VERSION ""

NS_ :

BS_:

BU_: CGW CLU EPB FCA SCC FR_CMR FR_RDR ADAS_PRK AMP BCW LDW_LKA MDPS RVM HUD AVM ACU ESC AFS

BO_ 870 CGW_PC4: 7 CGW
 SG_ F_N_ENG : 49|1@1+ (1,0) [0|1] ""  CLU,EPB,FCA,SCC,FR_CMR,FR_RDR
 SG_ N : 8|16@1+ (0.25,0) [0|16383.75] "rpm"  ADAS_PRK,AMP,CLU,EPB,FCA,SCC,FR_CMR,FR_RDR

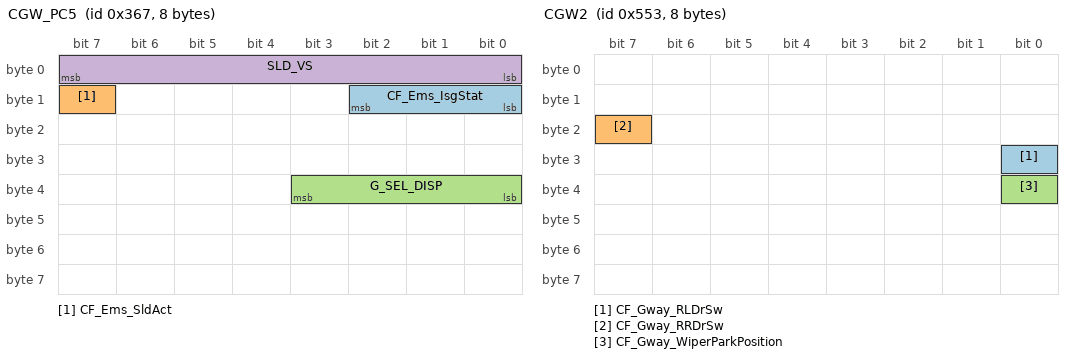
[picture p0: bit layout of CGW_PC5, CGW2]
BO_ 871 CGW_PC5: 8 CGW
 SG_ CF_Ems_IsgStat : 8|3@1+ (1,0) [0|7] ""  BCW,CLU,EPB,LDW_LKA,MDPS,SCC,FR_CMR,FR_RDR
 SG_ CF_Ems_SldAct : 15|1@1+ (1,0) [0|1] ""  CLU,LDW_LKA,SCC,FR_CMR,FR_RDR
 SG_ G_SEL_DISP : 32|4@1+ (1,0) [0|15] ""  ADAS_PRK,BCW,CLU,EPB,FCA,LDW_LKA,RVM,SCC,FR_CMR,FR_RDR
 SG_ SLD_VS : 0|8@1+ (1,0) [0|255] "km/h"  CLU,LDW_LKA,FR_CMR,FR_RDR

BO_ 1345 CGW1: 8 CGW
 SG_ CF_Gway_AstDrSw : 35|1@1+ (1,0) [0|1] ""  ADAS_PRK,CLU,LDW_LKA,FR_CMR,FR_RDR
 SG_ CF_Gway_DrvDrSw : 8|2@1+ (1,0) [0|3] ""  ADAS_PRK,CLU,EPB,LDW_LKA,SCC,FR_CMR,FR_RDR
 SG_ CF_Gway_DrvSeatBeltSw : 10|2@1+ (1,0) [0|3] ""  ADAS_PRK,EPB,LDW_LKA,FR_CMR,FR_RDR
 SG_ CF_Gway_HazardSw : 33|2@1+ (1,0) [0|3] ""  LDW_LKA,FR_CMR,FR_RDR
 SG_ CF_Gway_HBAControlMode : 52|1@1+ (1,0) [0|1] ""  LDW_LKA,FR_CMR,FR_RDR
 SG_ CF_Gway_HeadLampHigh : 32|1@1+ (1,0) [0|1] ""  CLU,LDW_LKA,FR_CMR,FR_RDR
 SG_ CF_Gway_HeadLampLow : 31|1@1+ (1,0) [0|1] ""  CLU,LDW_LKA,FR_CMR,FR_RDR
 SG_ CF_Gway_InhibitRMT : 54|2@1+ (1,0) [0|3] ""  ADAS_PRK,BCW,CLU,EPB,FCA,LDW_LKA,RVM,FR_CMR,FR_RDR
 SG_ CF_Gway_RainSnsState : 28|3@1+ (1,0) [0|7] ""  LDW_LKA,FR_CMR,FR_RDR
 SG_ CF_Gway_TSigLHSw : 42|1@1+ (1,0) [0|1] ""  FCA,LDW_LKA,FR_CMR,FR_RDR
 SG_ CF_Gway_TSigRHSw : 41|1@1+ (1,0) [0|1] ""  FCA,LDW_LKA,FR_CMR,FR_RDR
 SG_ CF_Gway_TurnSigLh : 19|2@1+ (1,0) [0|3] ""  BCW,CLU,LDW_LKA,SCC,FR_CMR,FR_RDR
 SG_ CF_Gway_TurnSigRh : 62|2@1+ (1,0) [0|3] ""  BCW,CLU,LDW_LKA,SCC,FR_CMR,FR_RDR
 SG_ CF_Gway_WiperAutoSw : 27|1@1+ (1,0) [0|1] ""  LDW_LKA,FR_CMR,FR_RDR
 SG_ CF_Gway_WiperHighSw : 26|1@1+ (1,0) [0|1] ""  LDW_LKA,FR_CMR,FR_RDR
 SG_ CF_Gway_WiperIntSw : 24|1@1+ (1,0) [0|1] ""  LDW_LKA,FR_CMR,FR_RDR
 SG_ CF_Gway_WiperIntT : 21|3@1+ (1,0) [0|7] ""  CLU,LDW_LKA,FR_CMR,FR_RDR
 SG_ CF_Gway_WiperLowSw : 25|1@1+ (1,0) [0|1] ""  LDW_LKA,FR_CMR,FR_RDR
 SG_ CF_Gway_IGNSw : 0|3@1+ (1,0) [0|7] ""  ADAS_PRK,CLU,LDW_LKA,RVM,HUD,EPB,AVM,BCW,SCC,FR_CMR,FR_RDR

BO_ 1363 CGW2: 8 CGW
 SG_ CF_Gway_RLDrSw : 24|1@1+ (1,0) [0|1] ""  ADAS_PRK,CLU,LDW_LKA,FR_CMR,FR_RDR
 SG_ CF_Gway_RRDrSw : 23|1@1+ (1,0) [0|1] ""  ADAS_PRK,CLU,LDW_LKA,FR_CMR,FR_RDR
 SG_ CF_Gway_WiperParkPosition : 32|1@1+ (1,0) [0|1] ""  LDW_LKA,FR_CMR,FR_RDR

BO_ 1193 CGW8: 8 CGW
 SG_ C_SMKTeleEngineRunning : 3|1@1+ (1,0) [0|1] ""  LDW_LKA,FR_CMR,FR_RDR

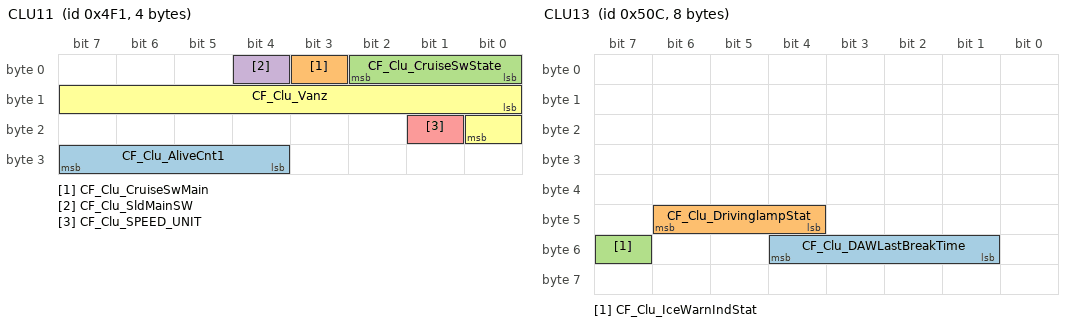
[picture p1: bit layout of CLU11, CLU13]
BO_ 1265 CLU11: 4 CLU
 SG_ CF_Clu_AliveCnt1 : 28|4@1+ (1,0) [0|15] ""  CGW,EPB,FCA,LDW_LKA,MDPS,SCC,FR_CMR,FR_RDR
 SG_ CF_Clu_CruiseSwMain : 3|1@1+ (1,0) [0|1] ""  CGW,SCC,FR_CMR,FR_RDR
 SG_ CF_Clu_CruiseSwState : 0|3@1+ (1,0) [0|7] ""  CGW,LDW_LKA,SCC,FR_CMR,FR_RDR
 SG_ CF_Clu_SldMainSW : 4|1@1+ (1,0) [0|1] ""  CGW,SCC,FR_CMR,FR_RDR
 SG_ CF_Clu_SPEED_UNIT : 17|1@1+ (1,0) [0|1] ""  ACU,ADAS_PRK,BCW,CGW,ESC,FCA,LDW_LKA,MDPS,SCC,FR_CMR,FR_RDR
 SG_ CF_Clu_Vanz : 8|9@1+ (0.5,0) [0|255] "km/h or MPH"  ADAS_PRK,BCW,CGW,FCA,LDW_LKA,MDPS,SCC,FR_CMR,FR_RDR

BO_ 1456 CLU12: 4 CLU
 SG_ CF_Clu_Odometer : 0|24@1+ (0.1,0) [0|1677721.4] "km"  BCW,CGW,EPB,FCA,SCC,FR_CMR,FR_RDR

BO_ 1292 CLU13: 8 CLU
 SG_ CF_Clu_DAWLastBreakTime : 49|4@1+ (1,0) [0|15] ""  CGW,LDW_LKA,FR_CMR,FR_RDR
 SG_ CF_Clu_DrivinglampStat : 44|3@1+ (1,0) [0|7] ""  CGW,ESC,MDPS,SCC,FR_CMR,FR_RDR
 SG_ CF_Clu_IceWarnIndStat : 55|1@1+ (1,0) [0|1] ""  LDW_LKA,FR_CMR,FR_RDR

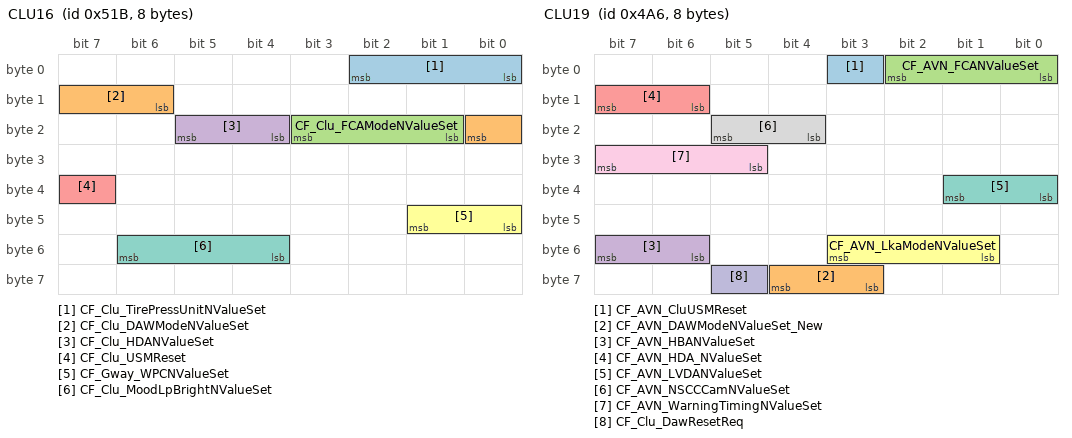
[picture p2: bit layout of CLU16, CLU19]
BO_ 1307 CLU16: 8 CLU
 SG_ CF_Clu_TirePressUnitNValueSet : 0|3@1+ (1,0) [0|7] ""  CGW,FR_CMR,FR_RDR
 SG_ CF_Clu_DAWModeNValueSet : 14|3@1+ (1,0) [0|7] ""  FR_CMR,FR_RDR
 SG_ CF_Clu_FCAModeNValueSet : 17|3@1+ (1,0) [0|7] ""  FR_RDR
 SG_ CF_Clu_HDANValueSet : 20|2@1+ (1,0) [0|3] ""  FR_CMR,FR_RDR
 SG_ CF_Clu_USMReset : 39|1@1+ (1,0) [0|1] ""  SCC,FR_CMR,HUD,CGW,BCW,AFS,FR_RDR
 SG_ CF_Gway_WPCNValueSet : 40|2@1+ (1,0) [0|3] ""  CGW,FR_CMR,FR_RDR
 SG_ CF_Clu_MoodLpBrightNValueSet : 52|3@1+ (1,0) [0|7] ""  CGW,FR_CMR,FR_RDR

BO_ 1190 CLU19: 8 CLU
 SG_ CF_AVN_CluUSMReset : 3|1@1+ (1,0) [0|1] ""  ADAS_PRK,BCW,FCA,LDW_LKA,SCC,FR_CMR,FR_RDR
 SG_ CF_AVN_DAWModeNValueSet_New : 59|2@1+ (1,0) [0|3] ""  LDW_LKA,FR_CMR,FR_RDR
 SG_ CF_AVN_FCANValueSet : 0|3@1+ (1,0) [0|7] ""  FCA,FR_CMR,FR_RDR
 SG_ CF_AVN_HBANValueSet : 54|2@1+ (1,0) [0|3] ""  CGW,LDW_LKA,FR_CMR,FR_RDR
 SG_ CF_AVN_HDA_NValueSet : 14|2@1+ (1,0) [0|3] ""  LDW_LKA,FR_CMR,FR_RDR
 SG_ CF_AVN_LkaModeNValueSet : 49|3@1+ (1,0) [0|7] ""  LDW_LKA,FR_CMR,FR_RDR
 SG_ CF_AVN_LVDANValueSet : 32|2@1+ (1,0) [0|3] ""  LDW_LKA,FR_CMR,FR_RDR
 SG_ CF_AVN_NSCCCamNValueSet : 20|2@1+ (1,0) [0|3] ""  SCC,FR_CMR,FR_RDR
 SG_ CF_AVN_WarningTimingNValueSet : 29|3@1+ (1,0) [0|7] ""  ADAS_PRK,BCW,FCA,LDW_LKA,FR_CMR,FR_RDR
 SG_ CF_Clu_DawResetReq : 61|1@1+ (1,0) [0|1] ""  LDW_LKA,FR_CMR,FR_RDR

BO_ 913 CLU21: 8 CLU
 SG_ CF_Clu_LFASwState : 4|1@1+ (1,0) [0|1] ""  LDW_LKA,FR_CMR,FR_RDR

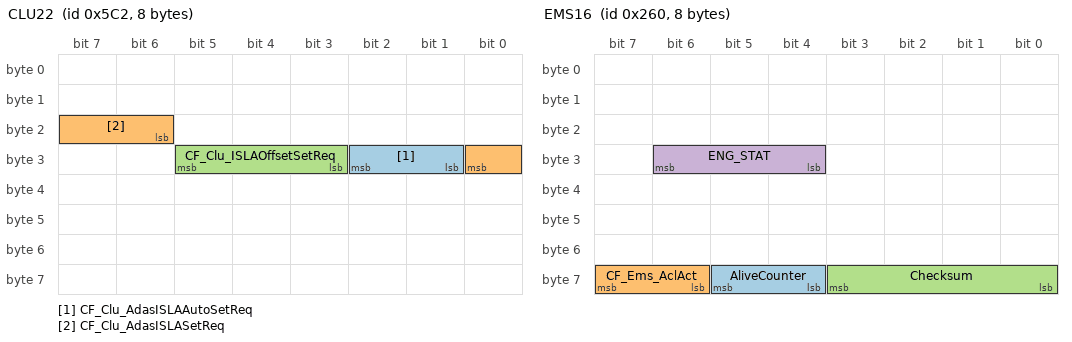
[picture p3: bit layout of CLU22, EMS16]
BO_ 1474 CLU22: 8 CLU
 SG_ CF_Clu_AdasISLAAutoSetReq : 25|2@1+ (1,0) [0|3] ""  LDW_LKA,FR_CMR,FR_RDR
 SG_ CF_Clu_AdasISLASetReq : 22|3@1+ (1,0) [0|7] ""  LDW_LKA,FR_CMR,FR_RDR
 SG_ CF_Clu_ISLAOffsetSetReq : 27|3@1+ (1,0) [0|7] ""  LDW_LKA,FR_CMR,FR_RDR

BO_ 809 EMS12: 8 CGW
 SG_ ACC_ACT : 30|1@1+ (1,0) [0|1] ""  AMP,FCA,FR_CMR,FR_RDR
 SG_ CONF_TCU m1 : 0|6@1+ (1,0) [0|63] ""  AMP,BCW,EPB,FCA,LDW_LKA,FR_CMR,FR_RDR
 SG_ MUL_CODE M : 6|2@1+ (1,0) [0|3] ""  ADAS_PRK,AMP,BCW,EPB,FCA,LDW_LKA,FR_CMR,FR_RDR
 SG_ PV_AV_CAN : 48|8@1+ (0.3906,0) [0|99.603] "%"  ADAS_PRK,AMP,EPB,FCA,LDW_LKA,SCC,FR_CMR,FR_RDR

BO_ 608 EMS16: 8 CGW
 SG_ AliveCounter : 60|2@1+ (1,0) [0|3] ""  FCA,MDPS,SCC,FR_CMR,FR_RDR
 SG_ CF_Ems_AclAct : 62|2@1+ (1,0) [0|3] ""  FCA,FR_CMR,FR_RDR
 SG_ Checksum : 56|4@1+ (1,0) [0|15] ""  FCA,MDPS,SCC,FR_CMR,FR_RDR
 SG_ ENG_STAT : 28|3@1+ (1,0) [0|7] ""  ADAS_PRK,AMP,BCW,CLU,EPB,FCA,LDW_LKA,MDPS,SCC,FR_CMR,FR_RDR

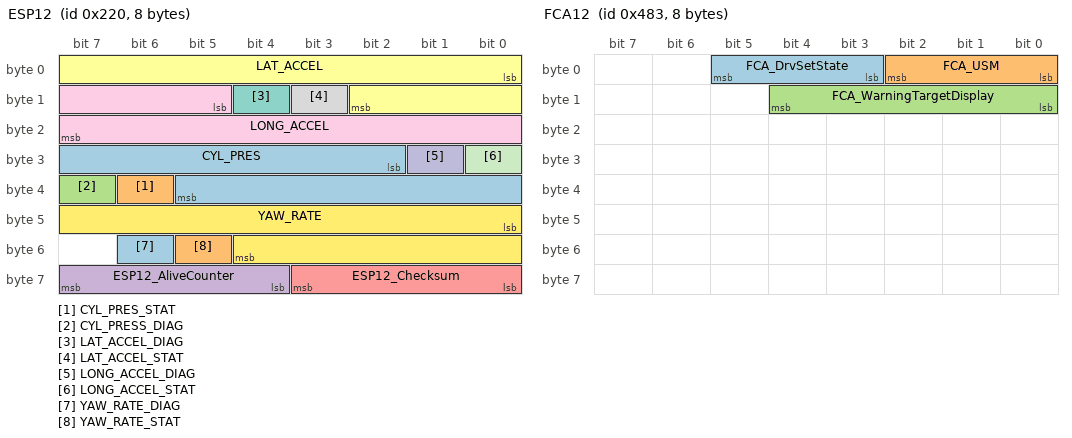
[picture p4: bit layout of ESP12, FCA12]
BO_ 544 ESP12: 8 ESC
 SG_ CYL_PRES : 26|12@1+ (0.1,0) [0|409.5] "Bar"  ADAS_PRK,CGW,EPB,FCA,LDW_LKA,SCC,FR_CMR,FR_RDR
 SG_ CYL_PRES_STAT : 38|1@1+ (1,0) [0|1] ""  ADAS_PRK,CGW,EPB,FCA,LDW_LKA,SCC,FR_CMR,FR_RDR
 SG_ CYL_PRESS_DIAG : 39|1@1+ (1,0) [0|1] ""  CGW,EPB,FCA,LDW_LKA,SCC,FR_CMR,FR_RDR
 SG_ ESP12_AliveCounter : 60|4@1+ (1,0) [0|15] ""  ADAS_PRK,FCA,LDW_LKA,FR_CMR,FR_RDR
 SG_ ESP12_Checksum : 56|4@1+ (1,0) [0|15] ""  ADAS_PRK,FCA,LDW_LKA,FR_CMR,FR_RDR
 SG_ LAT_ACCEL : 0|11@1+ (0.01,-10.23) [-10.23|10.24] "m/s^2"  CGW,FCA,LDW_LKA,MDPS,SCC,FR_CMR,FR_RDR
 SG_ LAT_ACCEL_DIAG : 12|1@1+ (1,0) [0|1] ""  CGW,FCA,LDW_LKA,MDPS,SCC,FR_CMR,FR_RDR
 SG_ LAT_ACCEL_STAT : 11|1@1+ (1,0) [0|1] ""  CGW,FCA,LDW_LKA,MDPS,SCC,FR_CMR,FR_RDR
 SG_ LONG_ACCEL : 13|11@1+ (0.01,-10.23) [-10.23|10.24] "m/s^2"  ADAS_PRK,CGW,EPB,FCA,LDW_LKA,SCC,FR_CMR,FR_RDR
 SG_ LONG_ACCEL_DIAG : 25|1@1+ (1,0) [0|1] ""  ADAS_PRK,CGW,EPB,FCA,LDW_LKA,SCC,FR_CMR,FR_RDR
 SG_ LONG_ACCEL_STAT : 24|1@1+ (1,0) [0|1] ""  ADAS_PRK,CGW,EPB,FCA,LDW_LKA,SCC,FR_CMR,FR_RDR
 SG_ YAW_RATE : 40|13@1+ (0.01,-40.95) [-40.95|40.96] "Deg/s"  ADAS_PRK,BCW,CGW,FCA,LDW_LKA,MDPS,SCC,FR_CMR,FR_RDR
 SG_ YAW_RATE_DIAG : 54|1@1+ (1,0) [0|1] ""  ADAS_PRK,CGW,FCA,LDW_LKA,MDPS,SCC,FR_CMR,FR_RDR
 SG_ YAW_RATE_STAT : 53|1@1+ (1,0) [0|1] ""  ADAS_PRK,CGW,FCA,LDW_LKA,MDPS,SCC,FR_CMR,FR_RDR

BO_ 909 FCA11_FS: 8 FR_CMR
 SG_ CF_VSM_BeltCmd : 5|3@1+ (1,0) [0|7] ""  ESC
 SG_ CF_VSM_DecCmdAct : 31|1@1+ (1,0) [0|1] ""  ESC
 SG_ CF_VSM_HBACmd : 1|2@1+ (1,0) [0|3] ""  ESC
 SG_ CF_VSM_Prefill : 0|1@1+ (1,0) [0|1] ""  CGW,ESC
 SG_ CF_VSM_Warn : 3|2@1+ (1,0) [0|3] ""  ACU,BCW,CGW,CLU,ESC
 SG_ CR_FCA_Alive : 35|4@1+ (1,0) [0|15] ""  ACU,ESC
 SG_ CR_VSM_DecCmd : 8|8@1+ (0.01,0) [0|2.55] "g"  ESC
 SG_ FCA_CmdAct : 20|1@1+ (1,0) [0|1] ""  CGW,ESC
 SG_ FCA_CRC : 56|8@1+ (1,0) [0|255] ""  ACU,ESC
 SG_ FCA_DrvSetStatus : 22|3@1+ (1,0) [0|7] ""  ESC,LDW_LKA
 SG_ FCA_Failinfo : 32|3@1+ (1,0) [0|7] ""  ACU,CGW,CLU,ESC
 SG_ FCA_RelativeVelocity : 39|9@1+ (0.1,-25.5) [-25.5|25.5] "m/s"  ACU
 SG_ FCA_Sensor_Type : 16|1@1+ (1,0) [0|1] ""  ACU
 SG_ FCA_Status : 18|2@1+ (1,0) [0|3] ""  ACU,CGW,CLU,ESC
 SG_ FCA_StopReq : 21|1@1+ (1,0) [0|1] ""  CGW,CLU,ESC
 SG_ FCA_TimetoCollision : 48|8@1+ (10,0) [0|2540] "ms"  ACU
 SG_ FCA_WrngSndSta : 29|2@1+ (1,0) [0|3] ""  CGW,CLU

BO_ 1155 FCA12: 8 FR_CMR
 SG_ FCA_DrvSetState : 3|3@1+ (1,0) [0|7] ""  CGW,CLU,LDW_LKA,FR_CMR
 SG_ FCA_USM : 0|3@1+ (1,0) [0|7] ""  CGW,CLU,FR_CMR
 SG_ FCA_WarningTargetDisplay : 8|5@1+ (1,0) [0|31] ""  CLU,FR_CMR

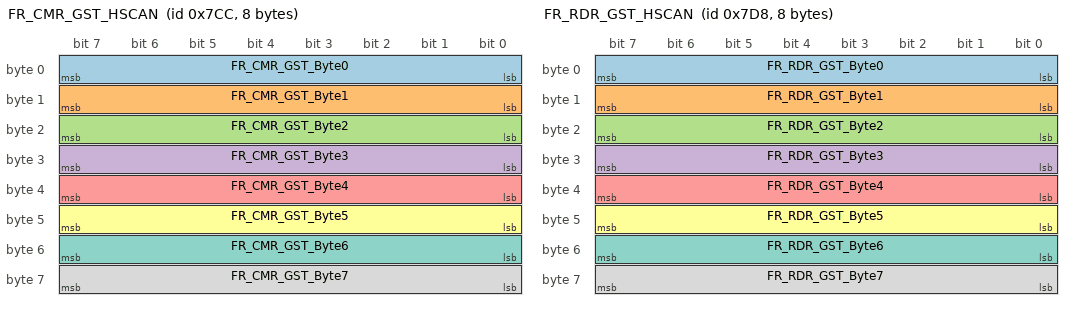
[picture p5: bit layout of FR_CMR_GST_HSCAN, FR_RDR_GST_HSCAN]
BO_ 1996 FR_CMR_GST_HSCAN: 8 FR_CMR
 SG_ FR_CMR_GST_Byte0 : 0|8@1+ (1,0) [0|255] ""  CGW
 SG_ FR_CMR_GST_Byte1 : 8|8@1+ (1,0) [0|255] ""  CGW
 SG_ FR_CMR_GST_Byte2 : 16|8@1+ (1,0) [0|255] ""  CGW
 SG_ FR_CMR_GST_Byte3 : 24|8@1+ (1,0) [0|255] ""  CGW
 SG_ FR_CMR_GST_Byte4 : 32|8@1+ (1,0) [0|255] ""  CGW
 SG_ FR_CMR_GST_Byte5 : 40|8@1+ (1,0) [0|255] ""  CGW
 SG_ FR_CMR_GST_Byte6 : 48|8@1+ (1,0) [0|255] ""  CGW
 SG_ FR_CMR_GST_Byte7 : 56|8@1+ (1,0) [0|255] ""  CGW

BO_ 2008 FR_RDR_GST_HSCAN: 8 FR_CMR
 SG_ FR_RDR_GST_Byte0 : 0|8@1+ (1,0) [0|255] ""  CGW
 SG_ FR_RDR_GST_Byte1 : 8|8@1+ (1,0) [0|255] ""  CGW
 SG_ FR_RDR_GST_Byte2 : 16|8@1+ (1,0) [0|255] ""  CGW
 SG_ FR_RDR_GST_Byte3 : 24|8@1+ (1,0) [0|255] ""  CGW
 SG_ FR_RDR_GST_Byte4 : 32|8@1+ (1,0) [0|255] ""  CGW
 SG_ FR_RDR_GST_Byte5 : 40|8@1+ (1,0) [0|255] ""  CGW
 SG_ FR_RDR_GST_Byte6 : 48|8@1+ (1,0) [0|255] ""  CGW
 SG_ FR_RDR_GST_Byte7 : 56|8@1+ (1,0) [0|255] ""  CGW

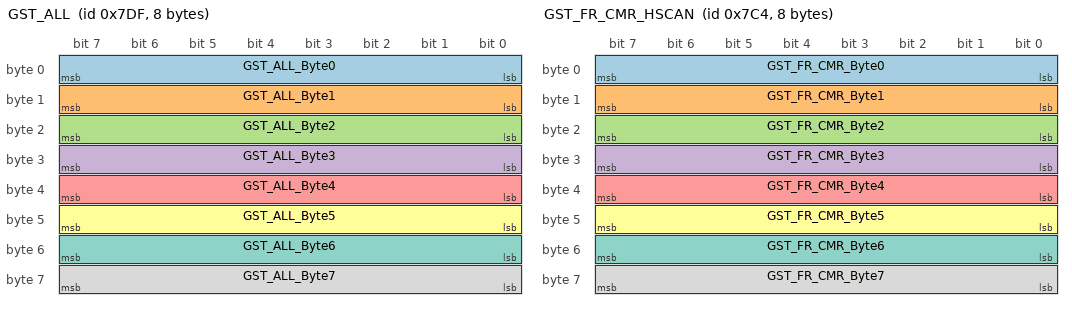
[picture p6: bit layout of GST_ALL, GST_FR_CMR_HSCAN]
BO_ 2015 GST_ALL: 8 CGW
 SG_ GST_ALL_Byte0 : 0|8@1+ (1,0) [0|255] ""  FR_CMR
 SG_ GST_ALL_Byte1 : 8|8@1+ (1,0) [0|255] ""  FR_CMR
 SG_ GST_ALL_Byte2 : 16|8@1+ (1,0) [0|255] ""  FR_CMR
 SG_ GST_ALL_Byte3 : 24|8@1+ (1,0) [0|255] ""  FR_CMR
 SG_ GST_ALL_Byte4 : 32|8@1+ (1,0) [0|255] ""  FR_CMR
 SG_ GST_ALL_Byte5 : 40|8@1+ (1,0) [0|255] ""  FR_CMR
 SG_ GST_ALL_Byte6 : 48|8@1+ (1,0) [0|255] ""  FR_CMR
 SG_ GST_ALL_Byte7 : 56|8@1+ (1,0) [0|255] ""  FR_CMR

BO_ 1988 GST_FR_CMR_HSCAN: 8 CGW
 SG_ GST_FR_CMR_Byte0 : 0|8@1+ (1,0) [0|255] ""  FR_CMR
 SG_ GST_FR_CMR_Byte1 : 8|8@1+ (1,0) [0|255] ""  FR_CMR
 SG_ GST_FR_CMR_Byte2 : 16|8@1+ (1,0) [0|255] ""  FR_CMR
 SG_ GST_FR_CMR_Byte3 : 24|8@1+ (1,0) [0|255] ""  FR_CMR
 SG_ GST_FR_CMR_Byte4 : 32|8@1+ (1,0) [0|255] ""  FR_CMR
 SG_ GST_FR_CMR_Byte5 : 40|8@1+ (1,0) [0|255] ""  FR_CMR
 SG_ GST_FR_CMR_Byte6 : 48|8@1+ (1,0) [0|255] ""  FR_CMR
 SG_ GST_FR_CMR_Byte7 : 56|8@1+ (1,0) [0|255] ""  FR_CMR

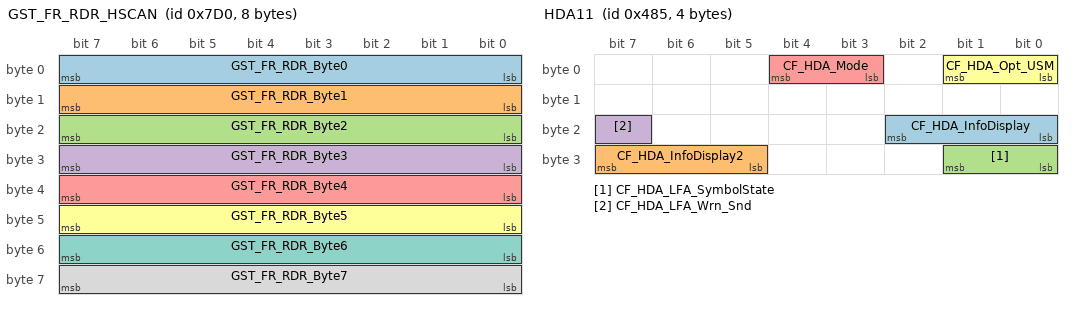
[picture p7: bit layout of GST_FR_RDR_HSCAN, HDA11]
BO_ 2000 GST_FR_RDR_HSCAN: 8 CGW
 SG_ GST_FR_RDR_Byte0 : 0|8@1+ (1,0) [0|255] ""  FR_CMR
 SG_ GST_FR_RDR_Byte1 : 8|8@1+ (1,0) [0|255] ""  FR_CMR
 SG_ GST_FR_RDR_Byte2 : 16|8@1+ (1,0) [0|255] ""  FR_CMR
 SG_ GST_FR_RDR_Byte3 : 24|8@1+ (1,0) [0|255] ""  FR_CMR
 SG_ GST_FR_RDR_Byte4 : 32|8@1+ (1,0) [0|255] ""  FR_CMR
 SG_ GST_FR_RDR_Byte5 : 40|8@1+ (1,0) [0|255] ""  FR_CMR
 SG_ GST_FR_RDR_Byte6 : 48|8@1+ (1,0) [0|255] ""  FR_CMR
 SG_ GST_FR_RDR_Byte7 : 56|8@1+ (1,0) [0|255] ""  FR_CMR

BO_ 1157 HDA11: 4 FR_CMR
 SG_ CF_HDA_InfoDisplay : 16|3@1+ (1,0) [0|7] ""  CLU
 SG_ CF_HDA_InfoDisplay2 : 29|3@1+ (1,0) [0|7] ""  CLU
 SG_ CF_HDA_LFA_SymbolState : 24|2@1+ (1,0) [0|3] ""  CGW,CLU
 SG_ CF_HDA_LFA_Wrn_Snd : 23|1@1+ (1,0) [0|1] ""  CGW,CLU
 SG_ CF_HDA_Mode : 3|2@1+ (1,0) [0|3] ""  CLU,SCC
 SG_ CF_HDA_Opt_USM : 0|2@1+ (1,0) [0|3] ""  CGW,CLU

BO_ 1470 HU_CLU_PE_05: 8 CGW
 SG_ HU_NaviCamSettingStatus : 24|8@1+ (1,0) [0|255] ""  SCC,FR_CMR
 SG_ HU_NaviStatus : 2|2@1+ (1,0) [0|3] ""  LDW_LKA,SCC,FR_CMR

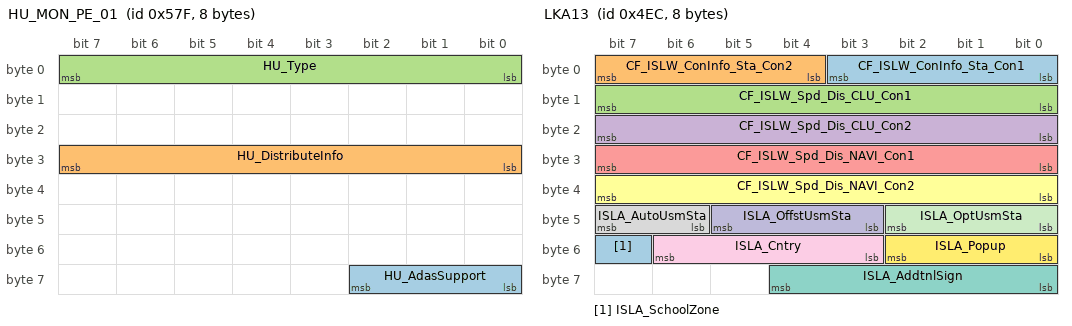
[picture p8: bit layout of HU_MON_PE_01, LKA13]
BO_ 1407 HU_MON_PE_01: 8 CGW
 SG_ HU_AdasSupport : 56|3@1+ (1,0) [0|7] ""  LDW_LKA,SCC,FR_CMR
 SG_ HU_DistributeInfo : 24|8@1+ (1,0) [0|255] ""  ADAS_PRK,LDW_LKA,RVM,SCC,FR_CMR
 SG_ HU_Type : 0|8@1+ (1,0) [0|255] ""  ADAS_PRK,LDW_LKA,RVM,FR_CMR

BO_ 832 LKA11_FS: 8 FR_CMR
 SG_ CF_HBA_Lamp : 14|1@1+ (1,0) [0|1] ""  CGW,CLU,FR_RDR
 SG_ CF_HBA_Opt : 34|1@1+ (1,0) [0|1] ""  CGW,CLU,FR_RDR
 SG_ CF_HBA_Opt_USM : 32|2@1+ (1,0) [0|3] ""  CGW,CLU,FR_RDR
 SG_ CF_HBA_SysState : 29|3@1+ (1,0) [0|7] ""  CGW,CLU,FR_RDR
 SG_ CF_LKA_ActToi : 27|1@1+ (1,0) [0|1] ""  CGW,MDPS,FR_RDR
 SG_ CF_LKA_CRC : 48|8@1+ (1,0) [0|255] ""  CGW,FCA,MDPS,FR_RDR
 SG_ CF_LKA_FusionState : 45|2@1+ (1,0) [0|3] ""  CGW,FCA,FR_RDR
 SG_ CF_LKA_HandsOff_Snd : 15|1@1+ (1,0) [0|1] ""  CGW,CLU,FR_RDR
 SG_ CF_LKA_LaneRecogState : 0|2@1+ (1,0) [0|3] ""  CGW,CLU,FR_RDR
 SG_ CF_LKA_LHWarning : 10|2@1+ (1,0) [0|3] ""  CGW,CLU,FR_RDR
 SG_ CF_LKA_MsgCount : 36|4@1+ (1,0) [0|15] ""  CGW,FCA,MDPS,FR_RDR
 SG_ CF_LKA_Opt_USM : 59|3@1+ (1,0) [0|7] ""  CGW,CLU,FR_RDR
 SG_ CF_LKA_RHWarning : 12|2@1+ (1,0) [0|3] ""  CGW,CLU,FR_RDR
 SG_ CF_LKA_SymbolState : 56|3@1+ (1,0) [0|7] ""  BCW,CGW,CLU,FR_RDR
 SG_ CF_LKA_SysState : 2|4@1+ (1,0) [0|15] ""  BCW,FR_RDR
 SG_ CF_LKA_SysWarning : 6|4@1+ (1,0) [0|15] ""  CGW,CLU,FR_RDR
 SG_ CF_LKA_ToiFlt : 28|1@1+ (1,0) [0|1] ""  CGW,MDPS,FR_RDR
 SG_ CF_LKA_USM_Mode : 40|2@1+ (1,0) [0|3] ""  CGW,CLU,FR_RDR
 SG_ CR_LKA_StrToqReq : 16|11@1+ (0.0078125,-8) [-8|8] "Nm"  CGW,MDPS,FR_RDR

BO_ 1342 LKA12: 8 FR_CMR
 SG_ CF_DAW_Opt_USM_NEW : 46|2@1+ (1,0) [0|3] ""  CGW,CLU,FR_RDR
 SG_ CF_DAW_Status : 40|4@1+ (1,0) [0|15] ""  CLU,FR_RDR
 SG_ CF_DAW_TimeReset : 36|1@1+ (1,0) [0|1] ""  CLU,FR_RDR
 SG_ CF_DAW_Warn : 44|2@1+ (1,0) [0|3] ""  CGW,CLU,FR_RDR
 SG_ CF_ISLW_Addinfo_Display : 8|2@1+ (1,0) [0|3] ""  CGW,CLU,FR_RDR
 SG_ CF_ISLW_OvrlapSign_Dis : 14|2@1+ (1,0) [0|3] ""  CGW,CLU,FR_RDR
 SG_ CF_ISLW_Spd_Dis_CLU_Main : 16|8@1+ (1,0) [0|255] ""  CGW,CLU,SCC,FR_RDR
 SG_ CF_ISLW_Spd_Dis_NAVI_Main : 24|8@1+ (1,0) [0|255] ""  CGW,FR_RDR
 SG_ CF_ISLW_Status : 12|2@1+ (1,0) [0|3] ""  CGW,CLU,SCC,FR_RDR
 SG_ CF_LeadVehDptAlert_Display : 32|2@1+ (1,0) [0|3] ""  CLU,FR_RDR
 SG_ CF_LeadVehDptAlert_USM : 34|2@1+ (1,0) [0|3] ""  CGW,CLU,FR_RDR
 SG_ ISLA_IcyWrn : 3|1@1+ (1,0) [0|1] ""  CGW,CLU,FR_RDR
 SG_ ISLA_SpdChgReq : 58|2@1+ (1,0) [0|3] ""  CGW,SCC,FR_RDR
 SG_ ISLA_SpdwOffst : 48|8@1+ (1,0) [0|255] ""  CGW,CLU,SCC,FR_RDR
 SG_ ISLA_SpdWrn : 60|1@1+ (1,0) [0|1] ""  CGW,CLU,FR_RDR
 SG_ ISLA_SwIgnoreReq : 56|2@1+ (1,0) [0|3] ""  CGW,SCC,FR_RDR
 SG_ ISLA_SymFlashMod : 61|3@1+ (1,0) [0|7] ""  CGW,CLU,FR_RDR

BO_ 1260 LKA13: 8 FR_CMR
 SG_ CF_ISLW_ConInfo_Sta_Con1 : 0|4@1+ (1,0) [0|15] ""  CGW,CLU,FR_RDR
 SG_ CF_ISLW_ConInfo_Sta_Con2 : 4|4@1+ (1,0) [0|15] ""  CGW,CLU,FR_RDR
 SG_ CF_ISLW_Spd_Dis_CLU_Con1 : 8|8@1+ (1,0) [0|255] ""  CGW,CLU,FR_RDR
 SG_ CF_ISLW_Spd_Dis_CLU_Con2 : 16|8@1+ (1,0) [0|255] ""  CGW,CLU,FR_RDR
 SG_ CF_ISLW_Spd_Dis_NAVI_Con1 : 24|8@1+ (1,0) [0|255] ""  CGW,FR_RDR
 SG_ CF_ISLW_Spd_Dis_NAVI_Con2 : 32|8@1+ (1,0) [0|255] ""  CGW,FR_RDR
 SG_ ISLA_AddtnlSign : 56|5@1+ (1,0) [0|31] ""  CGW,CLU,FR_RDR
 SG_ ISLA_AutoUsmSta : 46|2@1+ (1,0) [0|3] ""  CGW,CLU,FR_RDR
 SG_ ISLA_Cntry : 51|4@1+ (1,0) [0|15] ""  CGW,CLU,FR_RDR
 SG_ ISLA_OffstUsmSta : 43|3@1+ (1,0) [0|7] ""  CGW,CLU,FR_RDR
 SG_ ISLA_OptUsmSta : 40|3@1+ (1,0) [0|7] ""  CGW,CLU,SCC,FR_RDR
 SG_ ISLA_Popup : 48|3@1+ (1,0) [0|7] ""  CGW,CLU,FR_RDR
 SG_ ISLA_SchoolZone : 55|1@1+ (1,0) [0|1] ""  CGW,CLU,FR_RDR

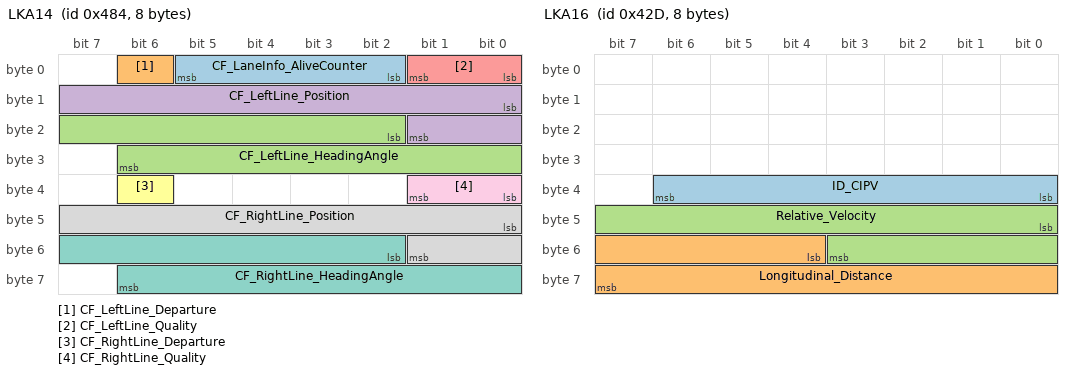
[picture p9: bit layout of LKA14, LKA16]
BO_ 1156 LKA14: 8 FR_CMR
 SG_ CF_LaneInfo_AliveCounter : 2|4@1+ (1,0) [0|15] ""  BCW,FR_RDR
 SG_ CF_LeftLine_Departure : 6|1@1+ (1,0) [0|1] ""  BCW,FR_RDR
 SG_ CF_LeftLine_HeadingAngle : 18|13@1+ (1.52588E-005,-0.0625) [-0.0625|0.0624848308] ""  BCW,FR_RDR
 SG_ CF_LeftLine_Position : 8|10@1- (0.00390625,0) [-2|1.99] ""  BCW,FR_RDR
 SG_ CF_LeftLine_Quality : 0|2@1+ (1,0) [0|3] ""  BCW,FR_RDR
 SG_ CF_RightLine_Departure : 38|1@1+ (1,0) [0|1] ""  BCW,FR_RDR
 SG_ CF_RightLine_HeadingAngle : 50|13@1+ (1.52588E-005,-0.0625) [-0.0625|0.0624848308] ""  BCW,FR_RDR
 SG_ CF_RightLine_Position : 40|10@1- (0.00390625,0) [-2|1.99] "m"  BCW,FR_RDR
 SG_ CF_RightLine_Quality : 32|2@1+ (1,0) [0|3] ""  BCW,FR_RDR

BO_ 1191 LKA15: 2 FR_CMR
 SG_ CF_FCA_Equip_FR_CMR : 0|3@1+ (1,0) [0|7] ""  ACU,ESC,FCA,FR_RDR

BO_ 1069 LKA16: 8 FR_CMR
 SG_ ID_CIPV : 32|7@1+ (1,0) [0|127] ""  CGW,FR_RDR
 SG_ Longitudinal_Distance : 52|12@1+ (0.05,0) [0|200] "m"  CGW,FR_RDR
 SG_ Relative_Velocity : 40|12@1+ (0.05,-100) [-100|100] "m/s"  CGW,FR_RDR

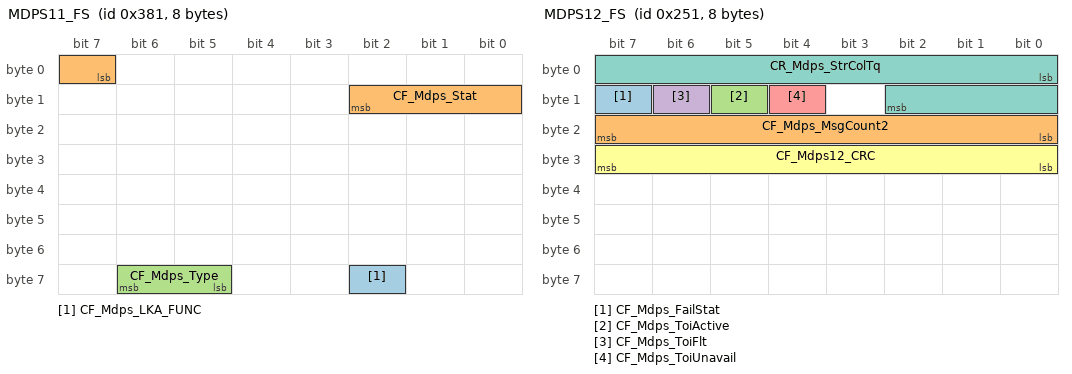
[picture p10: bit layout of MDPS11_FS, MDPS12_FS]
BO_ 897 MDPS11_FS: 8 MDPS
 SG_ CF_Mdps_LKA_FUNC : 58|1@1+ (1,0) [0|1] "flag"  CGW,LDW_LKA,FR_CMR
 SG_ CF_Mdps_Stat : 7|4@1+ (1,0) [0|15] ""  ADAS_PRK,CGW,LDW_LKA,FR_CMR
 SG_ CF_Mdps_Type : 61|2@1+ (1,0) [0|2] ""  ADAS_PRK,CGW,LDW_LKA,FR_CMR

BO_ 593 MDPS12_FS: 8 MDPS
 SG_ CF_Mdps_FailStat : 15|1@1+ (1,0) [0|1] ""  CGW,LDW_LKA,FR_CMR
 SG_ CF_Mdps_MsgCount2 : 16|8@1+ (1,0) [0|255] ""  CGW,ESC,LDW_LKA,FR_CMR
 SG_ CF_Mdps_ToiActive : 13|1@1+ (1,0) [0|1] ""  CGW,LDW_LKA,FR_CMR
 SG_ CF_Mdps_ToiFlt : 14|1@1+ (1,0) [0|1] ""  CGW,LDW_LKA,FR_CMR
 SG_ CF_Mdps_ToiUnavail : 12|1@1+ (1,0) [0|1] ""  CGW,LDW_LKA,FR_CMR
 SG_ CF_Mdps12_CRC : 24|8@1+ (1,0) [0|255] ""  CGW,ESC,LDW_LKA,FR_CMR
 SG_ CR_Mdps_StrColTq : 0|11@1+ (0.0078125,-8) [-8|7.984375] "Nm"  CGW,LDW_LKA,FR_CMR

BO_ 2679898130 MEAS_1: 8 FR_CMR
 SG_ Meas1Data : 0|64@1+ (1,0) [0|1.84467440737096E+019] ""  CGW,FR_RDR

BO_ 2679898131 MEAS_2: 8 FR_CMR
 SG_ Meas2Data : 0|64@1+ (1,0) [0|1.84467440737096E+019] ""  CGW,FR_RDR

BO_ 2679898132 MEAS_3: 8 FR_CMR
 SG_ Meas3Data : 0|64@1+ (1,0) [0|1.84467440737096E+019] ""  CGW,FR_RDR

BO_ 2679898133 MEAS_4: 8 FR_CMR
 SG_ Meas4Data : 0|64@1+ (1,0) [0|1.84467440737096E+019] ""  CGW,FR_RDR

BO_ 2679898134 MEAS_5: 8 FR_CMR
 SG_ Meas5Data : 0|64@1+ (1,0) [0|1.84467440737096E+019] ""  CGW,FR_RDR

CM_ BO_ 870 "[P] Periodic";
CM_ SG_ 870 F_N_ENG "fault engine speed signal";
CM_ SG_ 870 N "Engine speed";
CM_ BO_ 871 "[P] Periodic";
CM_ SG_ 871 CF_Ems_IsgStat "Status of ISG";
CM_ SG_ 871 CF_Ems_SldAct "Speed limiter device in activation";
CM_ SG_ 871 G_SEL_DISP "gear shift selector display";
CM_ SG_ 871 SLD_VS "Speed limiter vehicle speed";
CM_ BO_ 1345 "[PE] Periodic and On Event";
CM_ SG_ 1345 CF_Gway_AstDrSw "Assist door switch";
CM_ SG_ 1345 CF_Gway_DrvDrSw "Driver door switch";
CM_ SG_ 1345 CF_Gway_DrvSeatBeltSw "Driver Seat Belt Indicator";
CM_ SG_ 1345 CF_Gway_HazardSw "Hazard Switch Status";
CM_ SG_ 1345 CF_Gway_HeadLampHigh "Head Lamp High Beam On/Off Information";
CM_ SG_ 1345 CF_Gway_HeadLampLow "Head Lamp Low Beam On/Off Information";
CM_ SG_ 1345 CF_Gway_InhibitRMT "MT Gear R Switch signal";
CM_ SG_ 1345 CF_Gway_RainSnsState "Status of Rain Sensor";
CM_ SG_ 1345 CF_Gway_TSigLHSw "Turn Signal Left Switch";
CM_ SG_ 1345 CF_Gway_TSigRHSw "Turn Signal Right Switch";
CM_ SG_ 1345 CF_Gway_TurnSigLh "Status of Left Turn Signal On/Off";
CM_ SG_ 1345 CF_Gway_TurnSigRh "Status of Right Turn Signal On/Off";
CM_ SG_ 1345 CF_Gway_WiperAutoSw "Wiper Auto switch signal from MF SW";
CM_ SG_ 1345 CF_Gway_WiperHighSw "Wiper High switch signal from MF SW";
CM_ SG_ 1345 CF_Gway_WiperIntSw "Wiper INT switch signal from MF SW";
CM_ SG_ 1345 CF_Gway_WiperIntT "Wiper INT T value from MF SW";
CM_ SG_ 1345 CF_Gway_WiperLowSw "Wiper Low switch signal from MF SW";
CM_ SG_ 1345 CF_Gway_IGNSw "Ignition switch";
CM_ BO_ 1363 "[PE] Periodic and On Event";
CM_ SG_ 1363 CF_Gway_RLDrSw "Rear Left Door Switch";
CM_ SG_ 1363 CF_Gway_RRDrSw "Rear Right Door Switch";
CM_ SG_ 1363 CF_Gway_WiperParkPosition "Wiper Parking Position ";
CM_ BO_ 1193 "[PE] Periodic and On Event";
CM_ BO_ 1265 "[P] Periodic";
CM_ SG_ 1265 CF_Clu_AliveCnt1 "Alive signal";
CM_ SG_ 1265 CF_Clu_CruiseSwMain "Cruise control main switch ";
CM_ SG_ 1265 CF_Clu_CruiseSwState "Cruise operation control switch code";
CM_ SG_ 1265 CF_Clu_SldMainSW "Speed Limiter Main Switch On/Off Information";
CM_ SG_ 1265 CF_Clu_SPEED_UNIT "Kind of vehicle speed unit";
CM_ SG_ 1265 CF_Clu_Vanz "Displayed vehicle speed";
CM_ BO_ 1456 "[P] Periodic";
CM_ SG_ 1456 CF_Clu_Odometer "Odometer - Mileage information";
CM_ BO_ 1292 "[P] Periodic";
CM_ SG_ 1292 CF_Clu_DAWLastBreakTime "elapsed time count after last break_x000D_
";
CM_ SG_ 1292 CF_Clu_DrivinglampStat "This signal sends driving mode lamp status in cluster.";
CM_ SG_ 1292 CF_Clu_IceWarnIndStat "Ice warning indicator information";
CM_ BO_ 1307 "[E] On Event";
CM_ SG_ 1307 CF_Clu_TirePressUnitNValueSet "Request to set Tire Pressure Unit";
CM_ SG_ 1307 CF_Clu_DAWModeNValueSet "Request to set Driver Attention Warning USM";
CM_ SG_ 1307 CF_Clu_FCAModeNValueSet "Request to set FCA USM";
CM_ SG_ 1307 CF_Clu_HDANValueSet "Request to set HDA USM";
CM_ SG_ 1307 CF_Clu_USMReset "Request to reset USM";
CM_ SG_ 1307 CF_Gway_WPCNValueSet "-";
CM_ SG_ 1307 CF_Clu_MoodLpBrightNValueSet "Request to set Mood light bright value";
CM_ BO_ 1190 "[E] On Event";
CM_ SG_ 1190 CF_AVN_CluUSMReset "Request to reset USM menus";
CM_ SG_ 1190 CF_AVN_HBANValueSet "Request to set HBA status";
CM_ SG_ 1190 CF_AVN_LVDANValueSet "State of front vehicle departure notice function";
CM_ SG_ 1190 CF_Clu_DawResetReq "Request to DawReset";
CM_ BO_ 913 "[P] Periodic";
CM_ SG_ 913 CF_Clu_LFASwState "LFA Switch On/Off State";
CM_ BO_ 1474 "[E] On Event";
CM_ SG_ 1474 CF_Clu_AdasISLAAutoSetReq "CF_Clu_AdasISLAAutoSetReq";
CM_ SG_ 1474 CF_Clu_AdasISLASetReq "CF_Clu_AdasISLASetReq";
CM_ SG_ 1474 CF_Clu_ISLAOffsetSetReq "CF_Clu_ISLAOffsetSetReq";
CM_ BO_ 809 "[P] Periodic";
CM_ SG_ 809 ACC_ACT "Auto cruise control in activation";
CM_ SG_ 809 CONF_TCU "A/T or M/T information";
CM_ SG_ 809 MUL_CODE "Code for multiplexed information";
CM_ SG_ 809 PV_AV_CAN "Accelerator Pedal value";
CM_ BO_ 608 "[P] Periodic";
CM_ SG_ 608 AliveCounter "Alive Counter";
CM_ SG_ 608 CF_Ems_AclAct "Accelerator pedal applied";
CM_ SG_ 608 Checksum "Checksum";
CM_ SG_ 608 ENG_STAT "Engine Status";
CM_ BO_ 544 "[P] Periodic";
CM_ SG_ 544 CYL_PRES "Master cylinder pressure";
CM_ SG_ 544 CYL_PRES_STAT "Master cylinder pressure state";
CM_ SG_ 544 CYL_PRESS_DIAG "Diagnosis mode of master cylinder pressure";
CM_ SG_ 544 ESP12_AliveCounter "Message counter";
CM_ SG_ 544 ESP12_Checksum "Checksum ";
CM_ SG_ 544 LAT_ACCEL "Lateral acceleration speed";
CM_ SG_ 544 LAT_ACCEL_DIAG "Diagnosis mode of lateral acceleration ";
CM_ SG_ 544 LAT_ACCEL_STAT "Lateral acceleration signal state";
CM_ SG_ 544 LONG_ACCEL "Longitudinal acceleration speed";
CM_ SG_ 544 LONG_ACCEL_DIAG "Diagnosis mode of Longitudinal acceleration ";
CM_ SG_ 544 LONG_ACCEL_STAT "Longitudinal acceleration signal state";
CM_ SG_ 544 YAW_RATE "Yaw rate ";
CM_ SG_ 544 YAW_RATE_DIAG "Diagnosis mode of yaw rate sensor";
CM_ SG_ 544 YAW_RATE_STAT "Yaw rate signal state";
CM_ BO_ 909 "[P] Periodic";
CM_ SG_ 909 CF_VSM_BeltCmd "Command to active the seat belt";
CM_ SG_ 909 CF_VSM_DecCmdAct "Flag which indicates that the deceleration command from FCA (CR_VSM_DecCmd) is valid or not.";
CM_ SG_ 909 CF_VSM_HBACmd "Command to use lowered HBA (Hydraulic Boost Assist) threshold to sensitize the HBA entrance";
CM_ SG_ 909 CF_VSM_Prefill "Command to activate pre-fill";
CM_ SG_ 909 CF_VSM_Warn "VSM warning level";
CM_ SG_ 909 CR_FCA_Alive "FCA11_FS Message Alive-counter";
CM_ SG_ 909 CR_VSM_DecCmd "Deceleration command";
CM_ SG_ 909 FCA_CmdAct "Flag which indicates that the deceleration command from FCA (CR_VSM_DecCmd) is valid or not";
CM_ SG_ 909 FCA_CRC "CYCLIC RECUNDANCY CHECK";
CM_ SG_ 909 FCA_DrvSetStatus "Status of FCA Mode";
CM_ SG_ 909 FCA_Failinfo "Indication of FCA malfunction";
CM_ SG_ 909 FCA_RelativeVelocity "Relative Velocity between the host vehicle and a forward vehicle";
CM_ SG_ 909 FCA_Sensor_Type "Configuration information of FCA";
CM_ SG_ 909 FCA_Status "Indication of FCA Status";
CM_ SG_ 909 FCA_StopReq "Stop request flag by FCA";
CM_ SG_ 909 FCA_TimetoCollision "Predictive time to Collision between the host vehicle and a forward vehicle";
CM_ SG_ 909 FCA_WrngSndSta "FCA warning sound status";
CM_ BO_ 1155 "[PE] Periodic and On Event";
CM_ SG_ 1155 FCA_DrvSetState "State of FCA Mode";
CM_ SG_ 1155 FCA_USM "Indication of FCA State";
CM_ SG_ 1155 FCA_WarningTargetDisplay "FCA_WarningTargetDisplay";
CM_ BO_ 1996 "[EW] On Event and On Write";
CM_ SG_ 1996 FR_CMR_GST_Byte0 "FR_CMR_GST_Byte0";
CM_ SG_ 1996 FR_CMR_GST_Byte1 "FR_CMR_GST_Byte1";
CM_ SG_ 1996 FR_CMR_GST_Byte2 "FR_CMR_GST_Byte2";
CM_ SG_ 1996 FR_CMR_GST_Byte3 "FR_CMR_GST_Byte3";
CM_ SG_ 1996 FR_CMR_GST_Byte4 "FR_CMR_GST_Byte4";
CM_ SG_ 1996 FR_CMR_GST_Byte5 "FR_CMR_GST_Byte5";
CM_ SG_ 1996 FR_CMR_GST_Byte6 "FR_CMR_GST_Byte6";
CM_ SG_ 1996 FR_CMR_GST_Byte7 "FR_CMR_GST_Byte7";
CM_ BO_ 2008 "[EW] On Event and On Write";
CM_ SG_ 2008 FR_RDR_GST_Byte0 "FR_RDR_GST_Byte0";
CM_ SG_ 2008 FR_RDR_GST_Byte1 "FR_RDR_GST_Byte1";
CM_ SG_ 2008 FR_RDR_GST_Byte2 "FR_RDR_GST_Byte2";
CM_ SG_ 2008 FR_RDR_GST_Byte3 "FR_RDR_GST_Byte3";
CM_ SG_ 2008 FR_RDR_GST_Byte4 "FR_RDR_GST_Byte4";
CM_ SG_ 2008 FR_RDR_GST_Byte5 "FR_RDR_GST_Byte5";
CM_ SG_ 2008 FR_RDR_GST_Byte6 "FR_RDR_GST_Byte6";
CM_ SG_ 2008 FR_RDR_GST_Byte7 "FR_RDR_GST_Byte7";
CM_ BO_ 2015 "[EW] On Event and On Write";
CM_ SG_ 2015 GST_ALL_Byte0 "GST_ALL_Byte0";
CM_ SG_ 2015 GST_ALL_Byte1 "GST_ALL_Byte1";
CM_ SG_ 2015 GST_ALL_Byte2 "GST_ALL_Byte2";
CM_ SG_ 2015 GST_ALL_Byte3 "GST_ALL_Byte3";
CM_ SG_ 2015 GST_ALL_Byte4 "GST_ALL_Byte4";
CM_ SG_ 2015 GST_ALL_Byte5 "GST_ALL_Byte5";
CM_ SG_ 2015 GST_ALL_Byte6 "GST_ALL_Byte6";
CM_ SG_ 2015 GST_ALL_Byte7 "GST_ALL_Byte7";
CM_ BO_ 1988 "[EW] On Event and On Write";
CM_ SG_ 1988 GST_FR_CMR_Byte0 "GST_FR_CMR_Byte0";
CM_ SG_ 1988 GST_FR_CMR_Byte1 "GST_FR_CMR_Byte1";
CM_ SG_ 1988 GST_FR_CMR_Byte2 "GST_FR_CMR_Byte2";
CM_ SG_ 1988 GST_FR_CMR_Byte3 "GST_FR_CMR_Byte3";
CM_ SG_ 1988 GST_FR_CMR_Byte4 "GST_FR_CMR_Byte4";
CM_ SG_ 1988 GST_FR_CMR_Byte5 "GST_FR_CMR_Byte5";
CM_ SG_ 1988 GST_FR_CMR_Byte6 "GST_FR_CMR_Byte6";
CM_ SG_ 1988 GST_FR_CMR_Byte7 "GST_FR_CMR_Byte7";
CM_ BO_ 2000 "[EW] On Event and On Write";
CM_ SG_ 2000 GST_FR_RDR_Byte0 "GST_FR_RDR_Byte0";
CM_ SG_ 2000 GST_FR_RDR_Byte1 "GST_FR_RDR_Byte1";
CM_ SG_ 2000 GST_FR_RDR_Byte2 "GST_FR_RDR_Byte2";
CM_ SG_ 2000 GST_FR_RDR_Byte3 "GST_FR_RDR_Byte3";
CM_ SG_ 2000 GST_FR_RDR_Byte4 "GST_FR_RDR_Byte4";
CM_ SG_ 2000 GST_FR_RDR_Byte5 "GST_FR_RDR_Byte5";
CM_ SG_ 2000 GST_FR_RDR_Byte6 "GST_FR_RDR_Byte6";
CM_ SG_ 2000 GST_FR_RDR_Byte7 "GST_FR_RDR_Byte7";
CM_ BO_ 1157 "[P] Periodic";
CM_ SG_ 1157 CF_HDA_InfoDisplay "HDA Information Display";
CM_ SG_ 1157 CF_HDA_InfoDisplay2 "HDA Information Display2";
CM_ SG_ 1157 CF_HDA_LFA_SymbolState "Steering Wheel Symbol State";
CM_ SG_ 1157 CF_HDA_LFA_Wrn_Snd "HDA/LFA Additional Warning Sound";
CM_ SG_ 1157 CF_HDA_Mode "HDA Control Mode";
CM_ SG_ 1157 CF_HDA_Opt_USM "HDA USM Status";
CM_ BO_ 1470 "[PE] Periodic and On Event";
CM_ SG_ 1470 HU_NaviCamSettingStatus "Navigation Camera Alert Setting Status";
CM_ SG_ 1470 HU_NaviStatus "Navi Operation Status";
CM_ BO_ 1407 "[PE] Periodic and On Event";
CM_ SG_ 1407 HU_AdasSupport "Information about ADAS support";
CM_ SG_ 1407 HU_DistributeInfo "Information about nation of navigation";
CM_ SG_ 1407 HU_Type "H/U Type";
CM_ BO_ 832 "[P] Periodic";
CM_ SG_ 832 CF_HBA_Lamp "HBA System Indicator Lamp Status ";
CM_ SG_ 832 CF_HBA_Opt_USM "USM setting Information";
CM_ SG_ 832 CF_HBA_SysState "HBA System Status";
CM_ SG_ 832 CF_LKA_ActToi "Activate TOI";
CM_ SG_ 832 CF_LKA_CRC "CRC";
CM_ SG_ 832 CF_LKA_FusionState "Fusion Function State";
CM_ SG_ 832 CF_LKA_HandsOff_Snd "Hands-Off Sound Warning";
CM_ SG_ 832 CF_LKA_LaneRecogState "Lane Recognition Display";
CM_ SG_ 832 CF_LKA_LHWarning "LDW/LKA Left Warning";
CM_ SG_ 832 CF_LKA_MsgCount "Message Counter";
CM_ SG_ 832 CF_LKA_Opt_USM "LDW/LKA System Option & USM setting Information";
CM_ SG_ 832 CF_LKA_RHWarning "LDW/LKA Right Warning";
CM_ SG_ 832 CF_LKA_SymbolState "LKA Symbol Display";
CM_ SG_ 832 CF_LKA_SysState "LDW/LKA System State";
CM_ SG_ 832 CF_LKA_SysWarning "LKA_Additional_Info";
CM_ SG_ 832 CF_LKA_ToiFlt "LKA TOI Fault";
CM_ SG_ 832 CF_LKA_USM_Mode "LKA USM Mode Information";
CM_ SG_ 832 CR_LKA_StrToqReq "Steering Torque Request";
CM_ BO_ 1342 "[P] Periodic";
CM_ SG_ 1342 CF_DAW_Opt_USM_NEW "DAW USM ON/OFF information";
CM_ SG_ 1342 CF_DAW_Status "DAW Status or Level information";
CM_ SG_ 1342 CF_DAW_TimeReset "CLU Last Break Time Reset Request";
CM_ SG_ 1342 CF_DAW_Warn "DAW Warning Message Popup";
CM_ SG_ 1342 CF_ISLW_Addinfo_Display "Additional information of ISLW";
CM_ SG_ 1342 CF_ISLW_OvrlapSign_Dis "Indicates presence of Overlap sign";
CM_ SG_ 1342 CF_ISLW_Spd_Dis_CLU_Main "Speed information for cluster display";
CM_ SG_ 1342 CF_ISLW_Spd_Dis_NAVI_Main "Speed information for navigation display";
CM_ SG_ 1342 CF_ISLW_Status "Validity of ISLW";
CM_ SG_ 1342 CF_LeadVehDptAlert_Display "Message for displaying LVDA(Lead Vehicle Departure Alert) Warning";
CM_ SG_ 1342 CF_LeadVehDptAlert_USM "LVDA USM state";
CM_ SG_ 1342 ISLA_IcyWrn "ISLA Icy Warning";
CM_ SG_ 1342 ISLA_SpdChgReq "ISLA Speed Change Request";
CM_ SG_ 1342 ISLA_SpdwOffst "ISLA Speed With Offset";
CM_ SG_ 1342 ISLA_SpdWrn "ISLA Speed Warning";
CM_ SG_ 1342 ISLA_SwIgnoreReq "ISLA Switch Ignore Request";
CM_ SG_ 1342 ISLA_SymFlashMod "ISLA Symbol Flashing Mode";
CM_ BO_ 1260 "[P] Periodic";
CM_ SG_ 1260 CF_ISLW_ConInfo_Sta_Con1 "Indicates 1st conditional traffic sign status";
CM_ SG_ 1260 CF_ISLW_ConInfo_Sta_Con2 "Indicates 2nd conditional traffic sign status";
CM_ SG_ 1260 CF_ISLW_Spd_Dis_CLU_Con1 "Indicates speed limit of 1st conditional traffic sign";
CM_ SG_ 1260 CF_ISLW_Spd_Dis_CLU_Con2 "Indicates speed limit of 2nd conditional traffic sign";
CM_ SG_ 1260 CF_ISLW_Spd_Dis_NAVI_Con1 "Indicates speed limit of 1st conditional traffic sign";
CM_ SG_ 1260 CF_ISLW_Spd_Dis_NAVI_Con2 "Indicates speed limit of 2nd conditional traffic sign";
CM_ SG_ 1260 ISLA_AddtnlSign "ISLA Additional Sign";
CM_ SG_ 1260 ISLA_AutoUsmSta "ISLA AUTO USM Status";
CM_ SG_ 1260 ISLA_Cntry "ISLA Country";
CM_ SG_ 1260 ISLA_OffstUsmSta "ISLA Offset USM Status";
CM_ SG_ 1260 ISLA_OptUsmSta "ISLA Option USM Status";
CM_ SG_ 1260 ISLA_Popup "ISLA Pop-up";
CM_ SG_ 1260 ISLA_SchoolZone "ISLA School Zone";
CM_ BO_ 1156 "[P] Periodic";
CM_ BO_ 1191 "[P] Periodic";
CM_ SG_ 1191 CF_FCA_Equip_FR_CMR "FCA Sensor Type";
CM_ BO_ 1069 "[P] Periodic";
CM_ SG_ 1069 ID_CIPV "ID_CIPV (Valid Object = 1 to 127)";
CM_ SG_ 1069 Longitudinal_Distance "Distance to the object for ISG.";
CM_ SG_ 1069 Relative_Velocity "+ : Preceding, - : Oncoming";
CM_ BO_ 897 "[P] Periodic";
CM_ SG_ 897 CF_Mdps_LKA_FUNC "LKA plug-in status";
CM_ SG_ 897 CF_Mdps_Stat "MDPS Status";
CM_ SG_ 897 CF_Mdps_Type "Type of MDPS";
CM_ BO_ 593 "[P] Periodic";
CM_ SG_ 593 CF_Mdps_FailStat "LKA fail state";
CM_ SG_ 593 CF_Mdps_MsgCount2 "Message Counter";
CM_ SG_ 593 CF_Mdps_ToiActive "LKA TOI activated";
CM_ SG_ 593 CF_Mdps_ToiFlt "MDPS TOI fault";
CM_ SG_ 593 CF_Mdps_ToiUnavail "LKA TOI unavailable";
CM_ SG_ 593 CF_Mdps12_CRC "CYCLIC REDUNDANCY CHECK";
CM_ SG_ 593 CR_Mdps_StrColTq "Steering column torque";
CM_ BO_ 2679898130 "[P] Periodic";
CM_ SG_ 2679898130 Meas1Data "Meas1Data";
CM_ BO_ 2679898131 "[P] Periodic";
CM_ SG_ 2679898131 Meas2Data "Meas2Data";
CM_ BO_ 2679898132 "[P] Periodic";
CM_ SG_ 2679898132 Meas3Data "Meas3Data";
CM_ BO_ 2679898133 "[P] Periodic";
CM_ SG_ 2679898133 Meas4Data "Meas4Data";
CM_ BO_ 2679898134 "[P] Periodic";
CM_ SG_ 2679898134 Meas5Data "Meas5Data";
BA_DEF_ BO_  "GenMsgILSupport" ENUM  "No","Yes";
BA_DEF_ BO_  "DiagRequest" ENUM  "No","Yes";
BA_DEF_ BO_  "DiagResponse" ENUM  "No","Yes";
BA_DEF_ BO_  "DiagState" ENUM  "No","Yes";
BA_DEF_  "BusType" STRING ;
BA_DEF_ BO_  "VFrameFormat" ENUM  "StandardCAN","ExtendedCAN","reserved","reserved","reserved","reserved","reserved","reserved","reserved","reserved","reserved","reserved","reserved","reserved","StandardCAN_FD","ExtendedCAN_FD";
BA_DEF_ BO_  "GenMsgSendType" ENUM  "Cyclic","NoMsgSendType";
BA_DEF_ SG_  "UserSigValidity" ENUM  "B+","ACC","IG","IG1","IG2","IG3","IG1 or IG2","IG1 or IG3","Undef";
BA_DEF_ SG_  "RoutingFactor" INT 1 1215752192;
BA_DEF_ SG_  "Description" STRING ;
BA_DEF_ SG_  "Version" STRING ;
BA_DEF_ BO_  "GenMsgCycleTime" INT 0 2000;
BA_DEF_ BO_  "GenMsgStartDelayTime" INT 0 2000;
BA_DEF_ BU_  "NmNode" ENUM  "No","Yes";
BA_DEF_ SG_  "UsrSigPurpose" ENUM  "Undef","FN","DIAG","DEV","NM";
BA_DEF_ SG_  "GenSigStartValue" INT 0 0;
BA_DEF_DEF_  "GenMsgILSupport" "Yes";
BA_DEF_DEF_  "DiagRequest" "No";
BA_DEF_DEF_  "DiagResponse" "No";
BA_DEF_DEF_  "DiagState" "No";
BA_DEF_DEF_  "BusType" "CAN";
BA_DEF_DEF_  "VFrameFormat" "";
BA_DEF_DEF_  "GenMsgSendType" "NoMsgSendType";
BA_DEF_DEF_  "UserSigValidity" "IG";
BA_DEF_DEF_  "RoutingFactor" 1;
BA_DEF_DEF_  "Description" "";
BA_DEF_DEF_  "Version" "";
BA_DEF_DEF_  "GenMsgCycleTime" 0;
BA_DEF_DEF_  "GenMsgStartDelayTime" 0;
BA_DEF_DEF_  "NmNode" "Yes";
BA_DEF_DEF_  "UsrSigPurpose" "FN";
BA_DEF_DEF_  "GenSigStartValue" 0;
BA_ "NmNode" BU_ CGW 0;
BA_ "NmNode" BU_ CLU 0;
BA_ "NmNode" BU_ SCC 0;
BA_ "NmNode" BU_ FR_CMR 0;
BA_ "NmNode" BU_ FR_RDR 0;
BA_ "NmNode" BU_ MDPS 0;
BA_ "NmNode" BU_ ESC 0;
BA_ "GenMsgCycleTime" BO_ 870 10;
BA_ "GenMsgSendType" BO_ 870 0;
BA_ "VFrameFormat" BO_ 870 0;
BA_ "GenMsgCycleTime" BO_ 871 10;
BA_ "GenMsgSendType" BO_ 871 0;
BA_ "VFrameFormat" BO_ 871 0;
BA_ "GenMsgCycleTime" BO_ 1345 100;
BA_ "GenMsgSendType" BO_ 1345 0;
BA_ "VFrameFormat" BO_ 1345 0;
BA_ "GenMsgCycleTime" BO_ 1363 200;
BA_ "GenMsgSendType" BO_ 1363 0;
BA_ "VFrameFormat" BO_ 1363 0;
BA_ "GenMsgCycleTime" BO_ 1193 200;
BA_ "GenMsgSendType" BO_ 1193 0;
BA_ "VFrameFormat" BO_ 1193 0;
BA_ "GenMsgCycleTime" BO_ 1265 20;
BA_ "GenMsgSendType" BO_ 1265 0;
BA_ "VFrameFormat" BO_ 1265 0;
BA_ "GenMsgCycleTime" BO_ 1456 1000;
BA_ "GenMsgSendType" BO_ 1456 0;
BA_ "VFrameFormat" BO_ 1456 0;
BA_ "GenMsgCycleTime" BO_ 1292 100;
BA_ "GenMsgSendType" BO_ 1292 0;
BA_ "VFrameFormat" BO_ 1292 0;
BA_ "GenMsgSendType" BO_ 1307 0;
BA_ "VFrameFormat" BO_ 1307 0;
BA_ "GenMsgSendType" BO_ 1190 0;
BA_ "VFrameFormat" BO_ 1190 0;
BA_ "GenMsgCycleTime" BO_ 913 20;
BA_ "GenMsgSendType" BO_ 913 0;
BA_ "VFrameFormat" BO_ 913 0;
BA_ "GenMsgSendType" BO_ 1474 0;
BA_ "VFrameFormat" BO_ 1474 0;
BA_ "GenMsgCycleTime" BO_ 809 10;
BA_ "GenMsgSendType" BO_ 809 0;
BA_ "VFrameFormat" BO_ 809 0;
BA_ "GenMsgCycleTime" BO_ 608 10;
BA_ "GenMsgSendType" BO_ 608 0;
BA_ "VFrameFormat" BO_ 608 0;
BA_ "GenMsgCycleTime" BO_ 544 10;
BA_ "GenMsgSendType" BO_ 544 0;
BA_ "VFrameFormat" BO_ 544 0;
BA_ "GenMsgCycleTime" BO_ 909 20;
BA_ "GenMsgSendType" BO_ 909 0;
BA_ "VFrameFormat" BO_ 909 0;
BA_ "GenMsgCycleTime" BO_ 1155 200;
BA_ "GenMsgSendType" BO_ 1155 0;
BA_ "VFrameFormat" BO_ 1155 0;
BA_ "GenMsgILSupport" BO_ 1996 0;
BA_ "VFrameFormat" BO_ 1996 0;
BA_ "DiagResponse" BO_ 1996 1;
BA_ "GenMsgILSupport" BO_ 2008 0;
BA_ "VFrameFormat" BO_ 2008 0;
BA_ "GenMsgILSupport" BO_ 2015 0;
BA_ "VFrameFormat" BO_ 2015 0;
BA_ "DiagRequest" BO_ 2015 1;
BA_ "DiagState" BO_ 2015 1;
BA_ "GenMsgILSupport" BO_ 1988 0;
BA_ "VFrameFormat" BO_ 1988 0;
BA_ "DiagRequest" BO_ 1988 1;
BA_ "GenMsgILSupport" BO_ 2000 0;
BA_ "VFrameFormat" BO_ 2000 0;
BA_ "GenMsgCycleTime" BO_ 1157 50;
BA_ "GenMsgSendType" BO_ 1157 0;
BA_ "VFrameFormat" BO_ 1157 0;
BA_ "GenMsgCycleTime" BO_ 1470 1000;
BA_ "GenMsgSendType" BO_ 1470 0;
BA_ "VFrameFormat" BO_ 1470 0;
BA_ "GenMsgCycleTime" BO_ 1407 2000;
BA_ "GenMsgSendType" BO_ 1407 0;
BA_ "VFrameFormat" BO_ 1407 0;
BA_ "GenMsgCycleTime" BO_ 832 10;
BA_ "GenMsgSendType" BO_ 832 0;
BA_ "VFrameFormat" BO_ 832 0;
BA_ "GenMsgCycleTime" BO_ 1342 100;
BA_ "GenMsgSendType" BO_ 1342 0;
BA_ "VFrameFormat" BO_ 1342 0;
BA_ "GenMsgCycleTime" BO_ 1260 100;
BA_ "GenMsgSendType" BO_ 1260 0;
BA_ "VFrameFormat" BO_ 1260 0;
BA_ "GenMsgCycleTime" BO_ 1156 70;
BA_ "GenMsgSendType" BO_ 1156 0;
BA_ "VFrameFormat" BO_ 1156 0;
BA_ "GenMsgCycleTime" BO_ 1191 500;
BA_ "GenMsgSendType" BO_ 1191 0;
BA_ "VFrameFormat" BO_ 1191 0;
BA_ "GenMsgCycleTime" BO_ 1069 100;
BA_ "GenMsgSendType" BO_ 1069 0;
BA_ "VFrameFormat" BO_ 1069 0;
BA_ "GenMsgCycleTime" BO_ 897 20;
BA_ "GenMsgSendType" BO_ 897 0;
BA_ "VFrameFormat" BO_ 897 0;
BA_ "GenMsgCycleTime" BO_ 593 10;
BA_ "GenMsgSendType" BO_ 593 0;
BA_ "VFrameFormat" BO_ 593 0;
BA_ "GenMsgCycleTime" BO_ 2679898130 100;
BA_ "GenMsgSendType" BO_ 2679898130 0;
BA_ "VFrameFormat" BO_ 2679898130 1;
BA_ "GenMsgCycleTime" BO_ 2679898131 100;
BA_ "GenMsgSendType" BO_ 2679898131 0;
BA_ "VFrameFormat" BO_ 2679898131 1;
BA_ "GenMsgCycleTime" BO_ 2679898132 100;
BA_ "GenMsgSendType" BO_ 2679898132 0;
BA_ "VFrameFormat" BO_ 2679898132 1;
BA_ "GenMsgCycleTime" BO_ 2679898133 100;
BA_ "GenMsgSendType" BO_ 2679898133 0;
BA_ "VFrameFormat" BO_ 2679898133 1;
BA_ "GenMsgCycleTime" BO_ 2679898134 100;
BA_ "GenMsgSendType" BO_ 2679898134 0;
BA_ "VFrameFormat" BO_ 2679898134 1;
BA_ "UserSigValidity" SG_ 870 F_N_ENG 3;
BA_ "Description" SG_ 870 F_N_ENG "The signal F_N_ENG identifies an error on searching for a long tooth or on engine speed sensing.

Note : in some cases a limp-home function can be activated in the ECU (the engine speed signal is then based on the camshaft signal), and the engine may run";
BA_ "Version" SG_ 870 F_N_ENG "2.00.00";
BA_ "UserSigValidity" SG_ 870 N 3;
BA_ "Description" SG_ 870 N "The signal N is generated by crankshaft segment period measurement (in case of an six-cylinder engine, this corresponds to a crankshaft angle of 120°) and measured with a resolution of 4 us.

The signal N is represented as a 16 bit value.



The signal ";
BA_ "Version" SG_ 870 N "2.00.00";
BA_ "UserSigValidity" SG_ 871 CF_Ems_IsgStat 3;
BA_ "Description" SG_ 871 CF_Ems_IsgStat "1. ISG Status expressing CAN message divided by CF_EMS_IsgStat and CF_EMS_IsgStat2 

2. In EMS , CF_EMS_IsgStat and CF_EMS_IsgStat2 do not duplicate the output condition

(EX: If CF_EMS_IsgStat is 01h~07h, CF_EMS_IsgStat2 is 00h)";
BA_ "Version" SG_ 871 CF_Ems_IsgStat "2.68.04";
BA_ "UserSigValidity" SG_ 871 CF_Ems_SldAct 3;
BA_ "Description" SG_ 871 CF_Ems_SldAct "This signal indicates that if speed limiter function is active or not.

If the speed limiter function is activated then CF_Ems_SldAct = 1. Although “SLD Main” switch is on, if the Speed limiter function is deactivated then CF_Ems_SldAct should be set";
BA_ "Version" SG_ 871 CF_Ems_SldAct "2.00.00";
BA_ "UserSigValidity" SG_ 871 G_SEL_DISP 3;
BA_ "GenSigStartValue" SG_ 871 G_SEL_DISP 9;
BA_ "Description" SG_ 871 G_SEL_DISP "Position (P, R, N..), which was identified by the gear selector.

In case the gear selector is in a intermediate position, the last clear recognized position is used.

There is no specific phase relationship between the output and any other signal.";
BA_ "Version" SG_ 871 G_SEL_DISP "2.00.00";
BA_ "UserSigValidity" SG_ 871 SLD_VS 3;
BA_ "Description" SG_ 871 SLD_VS "The vehicle speed which is measured by the EMS has to be sent to CLUSTER. This value is used for limiting speed of EMS. 

EMS limite vehicle speed as this value.";
BA_ "Version" SG_ 871 SLD_VS "2.00.00";
BA_ "UserSigValidity" SG_ 1345 CF_Gway_AstDrSw 0;
BA_ "Description" SG_ 1345 CF_Gway_AstDrSw "This signal represents assist side door status.";
BA_ "Version" SG_ 1345 CF_Gway_AstDrSw "2.07.00";
BA_ "UserSigValidity" SG_ 1345 CF_Gway_DrvDrSw 0;
BA_ "Description" SG_ 1345 CF_Gway_DrvDrSw "This signal represents driver side door status. It is coming from IPMmsg02 in the B-CAN and cluster transmits the same signal to C-CAN as gateway. (B-CAN Name : DRVDRSW)

The update period of IPMmsg02 is 200ms. During the time between IPMmsg02 update, cl";
BA_ "Version" SG_ 1345 CF_Gway_DrvDrSw "2.07.00";
BA_ "UserSigValidity" SG_ 1345 CF_Gway_DrvSeatBeltSw 3;
BA_ "Description" SG_ 1345 CF_Gway_DrvSeatBeltSw "This signal represents driver seat belt indication command. It is coming from IPMmsg02 in the B-CAN and cluster transmits the same signal to C-CAN as gateway. (B-CAN Name : C_DRVSeatBeltSW)

The update period of IPMmsg02 is 200ms. During the time between";
BA_ "Version" SG_ 1345 CF_Gway_DrvSeatBeltSw "2.07.00";
BA_ "UserSigValidity" SG_ 1345 CF_Gway_HazardSw 3;
BA_ "Description" SG_ 1345 CF_Gway_HazardSw "Information on Hazard Switch On/Off status from Cluster.";
BA_ "Version" SG_ 1345 CF_Gway_HazardSw "2.07.00";
BA_ "UserSigValidity" SG_ 1345 CF_Gway_HBAControlMode 3;
BA_ "Description" SG_ 1345 CF_Gway_HBAControlMode "This signal indicates the status of BCM HBA control mode.";
BA_ "Version" SG_ 1345 CF_Gway_HBAControlMode "2.09.01";
BA_ "UserSigValidity" SG_ 1345 CF_Gway_HeadLampHigh 3;
BA_ "Description" SG_ 1345 CF_Gway_HeadLampHigh "This signal represents headlamp  High beam status. It is coming from IPMmsg03 or BOXmsg02 in the B-CAN and cluster transmits the same signal to C-CAN as gateway.

(B-CAN name : C_HeadLampHighIND or C_HLampHIGH_Act)";
BA_ "Version" SG_ 1345 CF_Gway_HeadLampHigh "2.03.00";
BA_ "UserSigValidity" SG_ 1345 CF_Gway_HeadLampLow 3;
BA_ "Description" SG_ 1345 CF_Gway_HeadLampLow "This signal represents headlamp low beam status. It is coming from IPMmsg03 or BOXmsg02 in the B-CAN and cluster transmits the same signal to C-CAN as gateway.

(B-CAN name : C_HeadLampLowIND or C_HLampLOW_Act)";
BA_ "Version" SG_ 1345 CF_Gway_HeadLampLow "2.03.00";
BA_ "UserSigValidity" SG_ 1345 CF_Gway_InhibitRMT 3;
BA_ "Description" SG_ 1345 CF_Gway_InhibitRMT "This signal indicates the MT Gear R Switch signal for ESC system.";
BA_ "Version" SG_ 1345 CF_Gway_InhibitRMT "2.07.00";
BA_ "UserSigValidity" SG_ 1345 CF_Gway_RainSnsState 3;
BA_ "Description" SG_ 1345 CF_Gway_RainSnsState "This signal represents the status of Rain Sensor signal state. It is coming from FAM in the B-CAN and cluster transmits the same signal to C-CAN as gateway. (B-CAN Name : C_RainSNSRStatus)

When the incoming B-CAN signal is timeout, cluster transmits the";
BA_ "Version" SG_ 1345 CF_Gway_RainSnsState "2.03.00";
BA_ "UserSigValidity" SG_ 1345 CF_Gway_TSigLHSw 3;
BA_ "Description" SG_ 1345 CF_Gway_TSigLHSw "This signal is used for confirm the status about Turn switch.";
BA_ "Version" SG_ 1345 CF_Gway_TSigLHSw "2.03.00";
BA_ "UserSigValidity" SG_ 1345 CF_Gway_TSigRHSw 3;
BA_ "Description" SG_ 1345 CF_Gway_TSigRHSw "This signal is used for confirm the status about Turn switch.";
BA_ "Version" SG_ 1345 CF_Gway_TSigRHSw "2.03.00";
BA_ "UserSigValidity" SG_ 1345 CF_Gway_TurnSigLh 3;
BA_ "Description" SG_ 1345 CF_Gway_TurnSigLh "This signal represents the left turn signal state. It is coming from MFSW in the B-CAN and cluster transmits the same signal to C-CAN as gateway. (B-CAN Name : C_TSigLHSW)

When the incoming B-CAN signal is timeout, cluster transmits the value for invali";
BA_ "Version" SG_ 1345 CF_Gway_TurnSigLh "2.07.00";
BA_ "UserSigValidity" SG_ 1345 CF_Gway_TurnSigRh 3;
BA_ "Description" SG_ 1345 CF_Gway_TurnSigRh "This signal represents the right turn signal state. It is coming from MFSW in the B-CAN and cluster transmits the same signal to C-CAN as gateway. (B-CAN Name : C_TSigRHSW)

When the incoming B-CAN signal is timeout, cluster transmits the value for inval";
BA_ "Version" SG_ 1345 CF_Gway_TurnSigRh "2.07.00";
BA_ "UserSigValidity" SG_ 1345 CF_Gway_WiperAutoSw 3;
BA_ "Description" SG_ 1345 CF_Gway_WiperAutoSw "This signal represents the wiper auto switch signal state. It is coming from MFSW in the B-CAN and cluster transmits the same signal to C-CAN as gateway. (B-CAN Name : C_WiperAutoSW)

When the incoming B-CAN signal is timeout, cluster transmits the value";
BA_ "Version" SG_ 1345 CF_Gway_WiperAutoSw "2.03.00";
BA_ "UserSigValidity" SG_ 1345 CF_Gway_WiperHighSw 3;
BA_ "Description" SG_ 1345 CF_Gway_WiperHighSw "This signal represents the wiper high switch signal state. It is coming from MFSW in the B-CAN and cluster transmits the same signal to C-CAN as gateway. (B-CAN Name : C_WiperHighSW)

When the incoming B-CAN signal is timeout, cluster transmits the value";
BA_ "Version" SG_ 1345 CF_Gway_WiperHighSw "2.03.00";
BA_ "UserSigValidity" SG_ 1345 CF_Gway_WiperIntSw 3;
BA_ "Description" SG_ 1345 CF_Gway_WiperIntSw "This signal represents the Wiper INT switch signal state. It is coming from MFSW in the B-CAN and cluster transmits the same signal to C-CAN as gateway. (B-CAN Name : C_WiperIntSW)

When the incoming B-CAN signal is timeout, cluster transmits the value f";
BA_ "Version" SG_ 1345 CF_Gway_WiperIntSw "2.03.00";
BA_ "UserSigValidity" SG_ 1345 CF_Gway_WiperIntT 3;
BA_ "Description" SG_ 1345 CF_Gway_WiperIntT "This signal represents the Wiper INT T value. It is coming from MFSW in the B-CAN and cluster 

transmits the same signal to C-CAN as gateway. (B-CAN Name : C_WiperIntT)

When the incoming B-CAN signal is timeout, cluster transmits the value for invalid ";
BA_ "Version" SG_ 1345 CF_Gway_WiperIntT "2.25.00";
BA_ "UserSigValidity" SG_ 1345 CF_Gway_WiperLowSw 3;
BA_ "Description" SG_ 1345 CF_Gway_WiperLowSw "This signal represents the wiper low switch signal state. It is coming from MFSW in the B-CAN and cluster transmits the same signal to C-CAN as gateway. (B-CAN Name : C_WiperLowSW)

When the incoming B-CAN signal is timeout, cluster transmits the value f";
BA_ "Version" SG_ 1345 CF_Gway_WiperLowSw "2.03.00";
BA_ "UserSigValidity" SG_ 1345 CF_Gway_IGNSw 0;
BA_ "Description" SG_ 1345 CF_Gway_IGNSw "This signal represents Ignition switch status";
BA_ "Version" SG_ 1345 CF_Gway_IGNSw "0.00.01";
BA_ "UserSigValidity" SG_ 1363 CF_Gway_RLDrSw 0;
BA_ "Description" SG_ 1363 CF_Gway_RLDrSw "This signal is valid from B+ (Battery attached) state. (Also valid over B+ : ACC, IGN1)

And it can be used to wake up C-CAN bus during IG-OFF Status.";
BA_ "Version" SG_ 1363 CF_Gway_RLDrSw "2.12.00";
BA_ "UserSigValidity" SG_ 1363 CF_Gway_RRDrSw 0;
BA_ "Description" SG_ 1363 CF_Gway_RRDrSw "This signal is valid from B+ (Battery attached) state. (Also valid over B+ : ACC, IGN1)

And it can be used to wake up C-CAN bus during IG-OFF Status.";
BA_ "Version" SG_ 1363 CF_Gway_RRDrSw "2.12.00";
BA_ "UserSigValidity" SG_ 1363 CF_Gway_WiperParkPosition 3;
BA_ "Description" SG_ 1363 CF_Gway_WiperParkPosition "This signal indicates Wiper Parking Position ";
BA_ "Version" SG_ 1363 CF_Gway_WiperParkPosition "2.03.00";
BA_ "UserSigValidity" SG_ 1193 C_SMKTeleEngineRunning 0;
BA_ "Version" SG_ 1193 C_SMKTeleEngineRunning "2.54.07";
BA_ "UserSigValidity" SG_ 1265 CF_Clu_AliveCnt1 3;
BA_ "Description" SG_ 1265 CF_Clu_AliveCnt1 "This cyclic counter indicates the actuality of the dashboard message.

This signal counts up every 20msec only when ignition is ON.

When ignition is off, AliveCounter is set as initial value (00H) 



IPM receives this signal from CLUSTER and IPM sends ";
BA_ "Version" SG_ 1265 CF_Clu_AliveCnt1 "2.11.00";
BA_ "UserSigValidity" SG_ 1265 CF_Clu_CruiseSwMain 3;
BA_ "Description" SG_ 1265 CF_Clu_CruiseSwMain "This signal enables or disables ACC/SCC function (ACC/SCC main switch). Default value of this sgnal is 0 and the value is set to 1 only while a driver is pressing the ACC/SCC main switch. This signal changes enable/disable state of SCC function according";
BA_ "Version" SG_ 1265 CF_Clu_CruiseSwMain "2.03.00";
BA_ "UserSigValidity" SG_ 1265 CF_Clu_CruiseSwState 3;
BA_ "Description" SG_ 1265 CF_Clu_CruiseSwState "Depending on whether “One-touch' logic is applied, the meaning of each signal value is divided into two cases as shown below



Case1) Not applied

0x0:Idle Position

0x1:Resume/Plus

0x2:Set/Minus

0x3:Time gap (Distance, SCC only)

0x4:ACC/SCC cancel";
BA_ "Version" SG_ 1265 CF_Clu_CruiseSwState "2.62.05";
BA_ "UserSigValidity" SG_ 1265 CF_Clu_SldMainSW 3;
BA_ "Description" SG_ 1265 CF_Clu_SldMainSW "This signal represents operating status of Speed Limiter Main Switch in Steering Wheel. This signal enables or disables SLD function (SLD main switch). Default value of this signal is 0 and the value is set to 1 only while a driver is pressing the SLD ma";
BA_ "Version" SG_ 1265 CF_Clu_SldMainSW "2.03.00";
BA_ "UserSigValidity" SG_ 1265 CF_Clu_SPEED_UNIT 3;
BA_ "Description" SG_ 1265 CF_Clu_SPEED_UNIT "This signal indicates the unit of the speed displayed in the speedometer.";
BA_ "Version" SG_ 1265 CF_Clu_SPEED_UNIT "2.03.00";
BA_ "UserSigValidity" SG_ 1265 CF_Clu_Vanz 3;
BA_ "Description" SG_ 1265 CF_Clu_Vanz "The vehicle speed which is indicated in the speedmeter has to be sent to SCC. This value is used for evalution of SCC command values instead of the vehicle velocity in order to avoid significant difference between the speedmeter indicator and the set spe";
BA_ "Version" SG_ 1265 CF_Clu_Vanz "2.54.00";
BA_ "UserSigValidity" SG_ 1456 CF_Clu_Odometer 3;
BA_ "Description" SG_ 1456 CF_Clu_Odometer "This signal indicates mileage counter of a vehicle. Cluster calculates total mileage and sends it to SCC and CUBIS. This value shall be the same with the mileage that is displayed to a driver.";
BA_ "Version" SG_ 1456 CF_Clu_Odometer "2.21.00";
BA_ "UserSigValidity" SG_ 1292 CF_Clu_DAWLastBreakTime 3;
BA_ "Description" SG_ 1292 CF_Clu_DAWLastBreakTime "This signal indicates that the elapsed time count after last driver's break. The elapsed time count increase 1 at an interval of 30 minutes._x000D_

";
BA_ "Version" SG_ 1292 CF_Clu_DAWLastBreakTime "2.47.03";
BA_ "UserSigValidity" SG_ 1292 CF_Clu_DrivinglampStat 3;
BA_ "Description" SG_ 1292 CF_Clu_DrivinglampStat "This signal sends driving mode lamp status in cluster_x000D_

(normal, eco, sport, sport+, smart, individual, N-mode)";
BA_ "Version" SG_ 1292 CF_Clu_DrivinglampStat "2.43.10";
BA_ "UserSigValidity" SG_ 1292 CF_Clu_IceWarnIndStat 3;
BA_ "Description" SG_ 1292 CF_Clu_IceWarnIndStat "This signal indicates that the Ice warning indicator in the cluster is on or off.

When Ice warning indicator is on, its value is 0x1 otherwise its value is 0x0.

";
BA_ "Version" SG_ 1292 CF_Clu_IceWarnIndStat "2.46.01";
BA_ "UserSigValidity" SG_ 1307 CF_Clu_TirePressUnitNValueSet 3;
BA_ "Description" SG_ 1307 CF_Clu_TirePressUnitNValueSet "This signal requests to set Tire Pressure Unit";
BA_ "Version" SG_ 1307 CF_Clu_TirePressUnitNValueSet "0.00.01";
BA_ "UserSigValidity" SG_ 1307 CF_Clu_DAWModeNValueSet 3;
BA_ "Description" SG_ 1307 CF_Clu_DAWModeNValueSet "This signal is used for Driver Attention Warning USM setting";
BA_ "Version" SG_ 1307 CF_Clu_DAWModeNValueSet "0.00.01";
BA_ "UserSigValidity" SG_ 1307 CF_Clu_FCAModeNValueSet 3;
BA_ "Description" SG_ 1307 CF_Clu_FCAModeNValueSet "This signal is used for FCA USM setting";
BA_ "Version" SG_ 1307 CF_Clu_FCAModeNValueSet "0.00.01";
BA_ "UserSigValidity" SG_ 1307 CF_Clu_HDANValueSet 3;
BA_ "Description" SG_ 1307 CF_Clu_HDANValueSet "This signal is used for HDA USM setting";
BA_ "Version" SG_ 1307 CF_Clu_HDANValueSet "0.00.01";
BA_ "UserSigValidity" SG_ 1307 CF_Clu_USMReset 3;
BA_ "Description" SG_ 1307 CF_Clu_USMReset "This signal is used to reset USM";
BA_ "Version" SG_ 1307 CF_Clu_USMReset "0.00.01";
BA_ "UserSigValidity" SG_ 1307 CF_Gway_WPCNValueSet 3;
BA_ "Description" SG_ 1307 CF_Gway_WPCNValueSet "-";
BA_ "Version" SG_ 1307 CF_Gway_WPCNValueSet "0.00.01";
BA_ "UserSigValidity" SG_ 1307 CF_Clu_MoodLpBrightNValueSet 3;
BA_ "Description" SG_ 1307 CF_Clu_MoodLpBrightNValueSet "This signal is used for Mood light bright setting";
BA_ "Version" SG_ 1307 CF_Clu_MoodLpBrightNValueSet "0.00.01";
BA_ "UserSigValidity" SG_ 1190 CF_AVN_CluUSMReset 3;
BA_ "Description" SG_ 1190 CF_AVN_CluUSMReset "This signal is used for a request to reset the value of USM menus._x000D_

When this signal change, the message (CLU19) is sent 3 times.";
BA_ "Version" SG_ 1190 CF_AVN_CluUSMReset "2.53.03";
BA_ "UserSigValidity" SG_ 1190 CF_AVN_DAWModeNValueSet_New 3;
BA_ "Description" SG_ 1190 CF_AVN_DAWModeNValueSet_New "This signal is used for a request to set the value of USM Menus.



If USM setting is changed, the message is sent 3 times.";
BA_ "Version" SG_ 1190 CF_AVN_DAWModeNValueSet_New "2.61.08";
BA_ "UserSigValidity" SG_ 1190 CF_AVN_FCANValueSet 3;
BA_ "Description" SG_ 1190 CF_AVN_FCANValueSet "This signal is used for a request to set the value of USM Menus. This signal requests to change status of FCA.";
BA_ "Version" SG_ 1190 CF_AVN_FCANValueSet "2.50.09";
BA_ "UserSigValidity" SG_ 1190 CF_AVN_HBANValueSet 3;
BA_ "Description" SG_ 1190 CF_AVN_HBANValueSet "This signal is used for a request to set the value of USM Menus. This signal requests to set HBA status.

When this signal change, the message is sent 3 times.";
BA_ "Version" SG_ 1190 CF_AVN_HBANValueSet "2.59.21";
BA_ "UserSigValidity" SG_ 1190 CF_AVN_HDA_NValueSet 3;
BA_ "Description" SG_ 1190 CF_AVN_HDA_NValueSet "This signal is used to set HDA(Highway Driving Assist) Function.";
BA_ "Version" SG_ 1190 CF_AVN_HDA_NValueSet "2.53.03";
BA_ "UserSigValidity" SG_ 1190 CF_AVN_LkaModeNValueSet 3;
BA_ "Description" SG_ 1190 CF_AVN_LkaModeNValueSet "This signal is used for a request to set the value of USM Menus. This signal requests to set LKA control mode.

When this signal change, the message is sent 3 times.";
BA_ "Version" SG_ 1190 CF_AVN_LkaModeNValueSet "2.51.07";
BA_ "UserSigValidity" SG_ 1190 CF_AVN_LVDANValueSet 3;
BA_ "Description" SG_ 1190 CF_AVN_LVDANValueSet "This signal is used for a request to set the value of USM menus. 

This signal requests to change the state of front vehicle departure notice function.



When this signal change, the message is sent 3 times";
BA_ "Version" SG_ 1190 CF_AVN_LVDANValueSet "2.58.05";
BA_ "UserSigValidity" SG_ 1190 CF_AVN_NSCCCamNValueSet 3;
BA_ "Description" SG_ 1190 CF_AVN_NSCCCamNValueSet "This signal is used for a request to set the value of USM Menus. This signal requests to change status of SCC interlocked with Navi Camera function.



When this signal change, the message is sent 3 times.";
BA_ "Version" SG_ 1190 CF_AVN_NSCCCamNValueSet "2.50.09";
BA_ "UserSigValidity" SG_ 1190 CF_AVN_WarningTimingNValueSet 3;
BA_ "Description" SG_ 1190 CF_AVN_WarningTimingNValueSet "Reqeust to set Warning Timing state";
BA_ "Version" SG_ 1190 CF_AVN_WarningTimingNValueSet "2.50.09";
BA_ "UserSigValidity" SG_ 1190 CF_Clu_DawResetReq 3;
BA_ "Description" SG_ 1190 CF_Clu_DawResetReq "This signal is used for a request to Daw reset request

When this signal change, the message is sent 3 times.";
BA_ "Version" SG_ 1190 CF_Clu_DawResetReq "2.65.05";
BA_ "UserSigValidity" SG_ 913 CF_Clu_LFASwState 3;
BA_ "Description" SG_ 913 CF_Clu_LFASwState "This signal represents operating status of ISA Main Switch in Steering Wheel. This signal enables or disables LFA function. Default value of this signal is 0 and the value is set to 1 only while a driver is pressing the LFA main switch. This signal chang";
BA_ "Version" SG_ 913 CF_Clu_LFASwState "2.59.21";
BA_ "UserSigValidity" SG_ 1474 CF_Clu_AdasISLAAutoSetReq 3;
BA_ "Description" SG_ 1474 CF_Clu_AdasISLAAutoSetReq "This signal is used for a request to set the value of USM menus.";
BA_ "Version" SG_ 1474 CF_Clu_AdasISLAAutoSetReq "2.67.04";
BA_ "UserSigValidity" SG_ 1474 CF_Clu_AdasISLASetReq 3;
BA_ "Description" SG_ 1474 CF_Clu_AdasISLASetReq "This signal is used for a request to set the value of USM menus.

If USM setting is changed, the message is sent 3 times.";
BA_ "Version" SG_ 1474 CF_Clu_AdasISLASetReq "2.67.04";
BA_ "UserSigValidity" SG_ 1474 CF_Clu_ISLAOffsetSetReq 3;
BA_ "Description" SG_ 1474 CF_Clu_ISLAOffsetSetReq "This signal is used for a request to set the value of USM menus.";
BA_ "Version" SG_ 1474 CF_Clu_ISLAOffsetSetReq "2.67.04";
BA_ "UserSigValidity" SG_ 809 ACC_ACT 3;
BA_ "Description" SG_ 809 ACC_ACT "EMS sends the state of the cruise control via the signal ACC_ACT. 

If the EMS does not support this signal the value is 00H



If the cruise control is activated then ACC_ACT = 1. In this period, vehicle speed control (cruise control) is performed by th";
BA_ "Version" SG_ 809 ACC_ACT "2.00.00";
BA_ "UserSigValidity" SG_ 809 CONF_TCU 3;
BA_ "Description" SG_ 809 CONF_TCU "A/T or M/T information generated by automatic variant coding.

A/T information is got from the “TCU_TYPE” signal of TCU1 message. (See TCU1 message information)";
BA_ "Version" SG_ 809 CONF_TCU "2.63.11";
BA_ "UserSigValidity" SG_ 809 MUL_CODE 3;
BA_ "Description" SG_ 809 MUL_CODE "In MUL_INFO the EMS transmits up to four multiplexed messages. The information is selected via MUL_CODE.

In general, the transmission of MUL_INFO and MUL_CODE starts with CAN_VERS.

The information is switched at intervals of 50..100 ms. Cyclic switchin";
BA_ "Version" SG_ 809 MUL_CODE "2.00.00";
BA_ "UserSigValidity" SG_ 809 PV_AV_CAN 3;
BA_ "Description" SG_ 809 PV_AV_CAN "The signal PV_AV_CAN is a measure of the Accelerator Pedal value.

The accelerator pedal value is determined via 2 pedal sensors, which are connected mechanically to the

accelerator pedal. If the EMS-ECU recognizes that the accelerator pedal is not acti";
BA_ "Version" SG_ 809 PV_AV_CAN "2.00.00";
BA_ "UserSigValidity" SG_ 608 AliveCounter 3;
BA_ "Description" SG_ 608 AliveCounter "This value is used to verify the correct transmission of EMS6.";
BA_ "Version" SG_ 608 AliveCounter "2.00.00";
BA_ "UserSigValidity" SG_ 608 CF_Ems_AclAct 3;
BA_ "Description" SG_ 608 CF_Ems_AclAct "This signal indicates if the driver applies the accelerator pedal. 

The signal always indicates the actual operation of the accelerator pedal, independent from SCC mode.";
BA_ "Version" SG_ 608 CF_Ems_AclAct "2.29.00";
BA_ "UserSigValidity" SG_ 608 Checksum 3;
BA_ "Description" SG_ 608 Checksum "(PH) = 10H - (Least Significant Nibbles of (Byte0 + Byte1 + Byte2 + Byte3 + Byte 4 + Byte5 + Byte6) + Most Significant Nibbles of (Byte0 + Byte1 + Byte2 + Byte3 + Byte4 + Byte5 + Byte6 + Byte7))";
BA_ "Version" SG_ 608 Checksum "2.00.00";
BA_ "UserSigValidity" SG_ 608 ENG_STAT 3;
BA_ "Description" SG_ 608 ENG_STAT "This signal indicates that a status of engine.";
BA_ "Version" SG_ 608 ENG_STAT "2.65.03";
BA_ "UserSigValidity" SG_ 544 CYL_PRES 3;
BA_ "Description" SG_ 544 CYL_PRES "This signal indicates pressure of brake master cylinder and provides information how deeply  a driver is pressing brake pedal.";
BA_ "Version" SG_ 544 CYL_PRES "2.25.00";
BA_ "UserSigValidity" SG_ 544 CYL_PRES_STAT 3;
BA_ "Description" SG_ 544 CYL_PRES_STAT "This signal indicates validity of CYL_PRES signal. If pressure signal is invalid, this signal shall be set to 1.";
BA_ "Version" SG_ 544 CYL_PRES_STAT "2.25.00";
BA_ "UserSigValidity" SG_ 544 CYL_PRESS_DIAG 3;
BA_ "Description" SG_ 544 CYL_PRESS_DIAG "This signal indicates self-diagnosis mode of master cylinder pressure signal. During system check, master cylinder pressure information cannot be sent(not available) and this bit should be set to 1.";
BA_ "Version" SG_ 544 CYL_PRESS_DIAG "2.25.00";
BA_ "UserSigValidity" SG_ 544 ESP12_AliveCounter 3;
BA_ "Description" SG_ 544 ESP12_AliveCounter "This signal indicates message counter (alive-counter) for robustness._x000D_

_x000D_

* 0 to15 rolling count ; increases by 1 at every sampling count(20ms)_x000D_

* after the counter is 15, it starts again at 0_x000D_

";
BA_ "Version" SG_ 544 ESP12_AliveCounter "2.33.03";
BA_ "UserSigValidity" SG_ 544 ESP12_Checksum 3;
BA_ "Description" SG_ 544 ESP12_Checksum "This value is used to check the ESP12 message is correctly transmitted._x000D_

(PH) = [ (Byte 0 + Byte 1 + Byte 2 + Byte 3 + Byte 4 + Byte 5 + Byte 6) ] XOR [0x9h]";
BA_ "Version" SG_ 544 ESP12_Checksum "2.33.03";
BA_ "UserSigValidity" SG_ 544 LAT_ACCEL 3;
BA_ "Description" SG_ 544 LAT_ACCEL "This signal indicates lateral acceleration speed information.";
BA_ "Version" SG_ 544 LAT_ACCEL "2.25.00";
BA_ "UserSigValidity" SG_ 544 LAT_ACCEL_DIAG 3;
BA_ "Description" SG_ 544 LAT_ACCEL_DIAG "This signal indicates self-diagnosis mode of lateral acceleration signal. During system check, lateral acceleration speed information cannot be sent(not available) and this bit should be set to 1.";
BA_ "Version" SG_ 544 LAT_ACCEL_DIAG "2.25.00";
BA_ "UserSigValidity" SG_ 544 LAT_ACCEL_STAT 3;
BA_ "Description" SG_ 544 LAT_ACCEL_STAT "This signal indicates validity of LAT_ACCEL signal. If acceleration signal is invalid, this signal shall be set to 1.";
BA_ "Version" SG_ 544 LAT_ACCEL_STAT "2.25.00";
BA_ "UserSigValidity" SG_ 544 LONG_ACCEL 3;
BA_ "Description" SG_ 544 LONG_ACCEL "This signal indicates longitudinal acceleration speed information. 

This signal is offset calibrated value that can cover minimum ±0.07G range offset by installation. 

If calibration process is missed or failed, then this signal send 0x7FF data as err";
BA_ "Version" SG_ 544 LONG_ACCEL "2.25.00";
BA_ "UserSigValidity" SG_ 544 LONG_ACCEL_DIAG 3;
BA_ "Description" SG_ 544 LONG_ACCEL_DIAG "This signal indicates self-diagnosis mode of longitudinal acceleration signal. During system check, longitudinal acceleration speed information cannot be sent(not available) and this bit should be set to 1.";
BA_ "Version" SG_ 544 LONG_ACCEL_DIAG "2.25.00";
BA_ "UserSigValidity" SG_ 544 LONG_ACCEL_STAT 3;
BA_ "Description" SG_ 544 LONG_ACCEL_STAT "This signal indicates validity of LONG_ACCEL signal. If acceleration signal is invalid, this signal shall be set to 1.";
BA_ "Version" SG_ 544 LONG_ACCEL_STAT "2.25.00";
BA_ "UserSigValidity" SG_ 544 YAW_RATE 3;
BA_ "Description" SG_ 544 YAW_RATE "The yaw rate signal provides information about the lateral motion of a vehicle and is used to calculate the curvature of the current vehicle trajectory. This signal is essential to SCC control in curves or during lane changes. If the demanded requirement";
BA_ "Version" SG_ 544 YAW_RATE "2.25.00";
BA_ "UserSigValidity" SG_ 544 YAW_RATE_DIAG 3;
BA_ "Description" SG_ 544 YAW_RATE_DIAG "This signal indicates self-diagnosis mode of yaw rate sensor. During system check, yaw rate information cannot be sent(not available) and this bit should be set to 1.";
BA_ "Version" SG_ 544 YAW_RATE_DIAG "2.25.00";
BA_ "UserSigValidity" SG_ 544 YAW_RATE_STAT 3;
BA_ "Description" SG_ 544 YAW_RATE_STAT "This signal indicates validity of YAW_RATE signal. If yaw rate sensor signal is invalid, this signal shall be set to 1.";
BA_ "Version" SG_ 544 YAW_RATE_STAT "2.25.00";
BA_ "UserSigValidity" SG_ 909 CF_VSM_BeltCmd 3;
BA_ "Description" SG_ 909 CF_VSM_BeltCmd "Depending on the driving situation, FCA tells PSB to release(no alert), retract or pull the seat belt for occupant protection or warning.";
BA_ "Version" SG_ 909 CF_VSM_BeltCmd "2.48.06";
BA_ "UserSigValidity" SG_ 909 CF_VSM_DecCmdAct 3;
BA_ "Description" SG_ 909 CF_VSM_DecCmdAct "Depending on the driving situation, FCA tells ESC to apply brake to decelerate at CR_VSM_DecCmd (pre-brake, BA+) before the driver applies the brake. The signal is to indicate that CR_VSM_DecCmd is valid or not.";
BA_ "Version" SG_ 909 CF_VSM_DecCmdAct "2.46.06";
BA_ "UserSigValidity" SG_ 909 CF_VSM_HBACmd 3;
BA_ "Description" SG_ 909 CF_VSM_HBACmd "Depending on the driving situation, FCA tells ESC to use lowered HBA (Hydraulic Boost Assist) threshold to sensitize the HBA entrance. The boost assist function is more easily activated than under normal driving condition.";
BA_ "Version" SG_ 909 CF_VSM_HBACmd "2.48.06";
BA_ "UserSigValidity" SG_ 909 CF_VSM_Prefill 3;
BA_ "Description" SG_ 909 CF_VSM_Prefill "Depending on the driving situation, FCA tells ESC to apply brake slightly so that the gap between brake pad and disc is removed. The pre-fill enables the braking force to be generated as soon as the driver applies the brake. Without pre-fill, the initial";
BA_ "Version" SG_ 909 CF_VSM_Prefill "2.48.06";
BA_ "UserSigValidity" SG_ 909 CF_VSM_Warn 3;
BA_ "Description" SG_ 909 CF_VSM_Warn "Request CLU to activate the corresponding warning device(s) according to the FCA warning level.";
BA_ "Version" SG_ 909 CF_VSM_Warn "2.48.06";
BA_ "UserSigValidity" SG_ 909 CR_FCA_Alive 3;
BA_ "Description" SG_ 909 CR_FCA_Alive "This signal indicates Alivecounter for robustness._x000D_

_x000D_

(PH)=1*(HEX)_x000D_

0~14 : After the counter is 14 it starts again at 0_x000D_

15 : signal invalid";
BA_ "Version" SG_ 909 CR_FCA_Alive "2.51.04";
BA_ "UserSigValidity" SG_ 909 CR_VSM_DecCmd 3;
BA_ "Description" SG_ 909 CR_VSM_DecCmd "Depending on the driving situation, FCA gives ESC the deceleration command. ESC maintains the deceleration.";
BA_ "Version" SG_ 909 CR_VSM_DecCmd "2.48.06";
BA_ "UserSigValidity" SG_ 909 FCA_CmdAct 3;
BA_ "Description" SG_ 909 FCA_CmdAct "Deceleration command from FCA Control logic is valid or not.";
BA_ "Version" SG_ 909 FCA_CmdAct "2.48.06";
BA_ "UserSigValidity" SG_ 909 FCA_CRC 3;
BA_ "GenSigStartValue" SG_ 909 FCA_CRC 255;
BA_ "Description" SG_ 909 FCA_CRC "Sender calculates CRC : _x000D__x000D_

The sender of safety relevant CAN output signals shall protect the output signals with a CRC on application software level._x000D__x000D_

_x000D__x000D_

Each CAN frame with safety relevant signals shall contain i";
BA_ "Version" SG_ 909 FCA_CRC "2.51.04";
BA_ "UserSigValidity" SG_ 909 FCA_DrvSetStatus 3;
BA_ "GenSigStartValue" SG_ 909 FCA_DrvSetStatus 1;
BA_ "Description" SG_ 909 FCA_DrvSetStatus "1. Acknowledge signal for USM signal from CLU._x000D_

_x000D_

2. Status of FCA control mode.";
BA_ "Version" SG_ 909 FCA_DrvSetStatus "2.46.06";
BA_ "UserSigValidity" SG_ 909 FCA_Failinfo 3;
BA_ "Description" SG_ 909 FCA_Failinfo "This signal describes the failure information of FCA Function.";
BA_ "Version" SG_ 909 FCA_Failinfo "2.46.06";
BA_ "UserSigValidity" SG_ 909 FCA_RelativeVelocity 3;
BA_ "Description" SG_ 909 FCA_RelativeVelocity "This signal indicates the relative velocity between the host vehicle and a forward vehicle._x000D_

_x000D_

(PH) = ((HEX)-0FFH)*0.1 [m/s/digit]_x000D_

       = (HEX)*0.1 [m/s/digit] - 25.5 [m/s]_x000D_

CAN Message Physical range : Max. Relative veloci";
BA_ "Version" SG_ 909 FCA_RelativeVelocity "2.51.04";
BA_ "UserSigValidity" SG_ 909 FCA_Sensor_Type 3;
BA_ "Description" SG_ 909 FCA_Sensor_Type "This signal describes the information for the FCA hardware configuration._x000D_

0x0h : Not Sensor fusion_x000D_

0x1h : Sensor fusion_x000D_

";
BA_ "Version" SG_ 909 FCA_Sensor_Type "2.51.08";
BA_ "UserSigValidity" SG_ 909 FCA_Status 3;
BA_ "Description" SG_ 909 FCA_Status "This signal describes the FCA Function.";
BA_ "Version" SG_ 909 FCA_Status "2.48.06";
BA_ "UserSigValidity" SG_ 909 FCA_StopReq 3;
BA_ "Description" SG_ 909 FCA_StopReq "A control request flag for vehicle stop. FCA expects vehicle to be controlled to a complete stop and hold its state by ESC.";
BA_ "Version" SG_ 909 FCA_StopReq "2.46.06";
BA_ "UserSigValidity" SG_ 909 FCA_TimetoCollision 3;
BA_ "Description" SG_ 909 FCA_TimetoCollision "This signal indicates predictive time to Collision between the host vehicle and a forward vehicle._x000D_

_x000D_

(PH) = 10*(HEX) [ms]_x000D_

CAN Message Physical range : 0 ~ 2540 [ms], Resolution : 10ms";
BA_ "Version" SG_ 909 FCA_TimetoCollision "2.51.04";
BA_ "UserSigValidity" SG_ 909 FCA_WrngSndSta 3;
BA_ "Description" SG_ 909 FCA_WrngSndSta "FCA warning sound status";
BA_ "Version" SG_ 909 FCA_WrngSndSta "2.69.10";
BA_ "UserSigValidity" SG_ 1155 FCA_DrvSetState 3;
BA_ "GenSigStartValue" SG_ 1155 FCA_DrvSetState 2;
BA_ "Description" SG_ 1155 FCA_DrvSetState "1. Acknowledge signal for USM signal from CLU._x000D_

_x000D_

2. State of FCA control mode.";
BA_ "Version" SG_ 1155 FCA_DrvSetState "2.49.06";
BA_ "UserSigValidity" SG_ 1155 FCA_USM 3;
BA_ "GenSigStartValue" SG_ 1155 FCA_USM 3;
BA_ "Description" SG_ 1155 FCA_USM "This signal describes the FCA State.";
BA_ "Version" SG_ 1155 FCA_USM "2.49.06";
BA_ "UserSigValidity" SG_ 1155 FCA_WarningTargetDisplay 3;
BA_ "Description" SG_ 1155 FCA_WarningTargetDisplay "Request CLU to activate the corresponding warning device(s) according to the type of FCA warning target.

- FCA 경고 대상 종류별 표시 정보신호";
BA_ "Version" SG_ 1155 FCA_WarningTargetDisplay "2.61.06";
BA_ "UserSigValidity" SG_ 1996 FR_CMR_GST_Byte0 3;
BA_ "Description" SG_ 1996 FR_CMR_GST_Byte0 "-";
BA_ "Version" SG_ 1996 FR_CMR_GST_Byte0 "0.00.01";
BA_ "UsrSigPurpose" SG_ 1996 FR_CMR_GST_Byte0 2;
BA_ "UserSigValidity" SG_ 1996 FR_CMR_GST_Byte1 3;
BA_ "Description" SG_ 1996 FR_CMR_GST_Byte1 "-";
BA_ "Version" SG_ 1996 FR_CMR_GST_Byte1 "0.00.01";
BA_ "UsrSigPurpose" SG_ 1996 FR_CMR_GST_Byte1 2;
BA_ "UserSigValidity" SG_ 1996 FR_CMR_GST_Byte2 3;
BA_ "Description" SG_ 1996 FR_CMR_GST_Byte2 "-";
BA_ "Version" SG_ 1996 FR_CMR_GST_Byte2 "0.00.01";
BA_ "UsrSigPurpose" SG_ 1996 FR_CMR_GST_Byte2 2;
BA_ "UserSigValidity" SG_ 1996 FR_CMR_GST_Byte3 3;
BA_ "Description" SG_ 1996 FR_CMR_GST_Byte3 "-";
BA_ "Version" SG_ 1996 FR_CMR_GST_Byte3 "0.00.01";
BA_ "UsrSigPurpose" SG_ 1996 FR_CMR_GST_Byte3 2;
BA_ "UserSigValidity" SG_ 1996 FR_CMR_GST_Byte4 3;
BA_ "Description" SG_ 1996 FR_CMR_GST_Byte4 "-";
BA_ "Version" SG_ 1996 FR_CMR_GST_Byte4 "0.00.01";
BA_ "UsrSigPurpose" SG_ 1996 FR_CMR_GST_Byte4 2;
BA_ "UserSigValidity" SG_ 1996 FR_CMR_GST_Byte5 3;
BA_ "Description" SG_ 1996 FR_CMR_GST_Byte5 "-";
BA_ "Version" SG_ 1996 FR_CMR_GST_Byte5 "0.00.01";
BA_ "UsrSigPurpose" SG_ 1996 FR_CMR_GST_Byte5 2;
BA_ "UserSigValidity" SG_ 1996 FR_CMR_GST_Byte6 3;
BA_ "Description" SG_ 1996 FR_CMR_GST_Byte6 "-";
BA_ "Version" SG_ 1996 FR_CMR_GST_Byte6 "0.00.01";
BA_ "UsrSigPurpose" SG_ 1996 FR_CMR_GST_Byte6 2;
BA_ "UserSigValidity" SG_ 1996 FR_CMR_GST_Byte7 3;
BA_ "Description" SG_ 1996 FR_CMR_GST_Byte7 "-";
BA_ "Version" SG_ 1996 FR_CMR_GST_Byte7 "0.00.01";
BA_ "UsrSigPurpose" SG_ 1996 FR_CMR_GST_Byte7 2;
BA_ "UserSigValidity" SG_ 2008 FR_RDR_GST_Byte0 3;
BA_ "Description" SG_ 2008 FR_RDR_GST_Byte0 "-";
BA_ "Version" SG_ 2008 FR_RDR_GST_Byte0 "0.00.01";
BA_ "UsrSigPurpose" SG_ 2008 FR_RDR_GST_Byte0 2;
BA_ "UserSigValidity" SG_ 2008 FR_RDR_GST_Byte1 3;
BA_ "Description" SG_ 2008 FR_RDR_GST_Byte1 "-";
BA_ "Version" SG_ 2008 FR_RDR_GST_Byte1 "0.00.01";
BA_ "UsrSigPurpose" SG_ 2008 FR_RDR_GST_Byte1 2;
BA_ "UserSigValidity" SG_ 2008 FR_RDR_GST_Byte2 3;
BA_ "Description" SG_ 2008 FR_RDR_GST_Byte2 "-";
BA_ "Version" SG_ 2008 FR_RDR_GST_Byte2 "0.00.01";
BA_ "UsrSigPurpose" SG_ 2008 FR_RDR_GST_Byte2 2;
BA_ "UserSigValidity" SG_ 2008 FR_RDR_GST_Byte3 3;
BA_ "Description" SG_ 2008 FR_RDR_GST_Byte3 "-";
BA_ "Version" SG_ 2008 FR_RDR_GST_Byte3 "0.00.01";
BA_ "UsrSigPurpose" SG_ 2008 FR_RDR_GST_Byte3 2;
BA_ "UserSigValidity" SG_ 2008 FR_RDR_GST_Byte4 3;
BA_ "Description" SG_ 2008 FR_RDR_GST_Byte4 "-";
BA_ "Version" SG_ 2008 FR_RDR_GST_Byte4 "0.00.01";
BA_ "UsrSigPurpose" SG_ 2008 FR_RDR_GST_Byte4 2;
BA_ "UserSigValidity" SG_ 2008 FR_RDR_GST_Byte5 3;
BA_ "Description" SG_ 2008 FR_RDR_GST_Byte5 "-";
BA_ "Version" SG_ 2008 FR_RDR_GST_Byte5 "0.00.01";
BA_ "UsrSigPurpose" SG_ 2008 FR_RDR_GST_Byte5 2;
BA_ "UserSigValidity" SG_ 2008 FR_RDR_GST_Byte6 3;
BA_ "Description" SG_ 2008 FR_RDR_GST_Byte6 "-";
BA_ "Version" SG_ 2008 FR_RDR_GST_Byte6 "0.00.01";
BA_ "UsrSigPurpose" SG_ 2008 FR_RDR_GST_Byte6 2;
BA_ "UserSigValidity" SG_ 2008 FR_RDR_GST_Byte7 3;
BA_ "Description" SG_ 2008 FR_RDR_GST_Byte7 "-";
BA_ "Version" SG_ 2008 FR_RDR_GST_Byte7 "0.00.01";
BA_ "UsrSigPurpose" SG_ 2008 FR_RDR_GST_Byte7 2;
BA_ "UserSigValidity" SG_ 2015 GST_ALL_Byte0 3;
BA_ "Description" SG_ 2015 GST_ALL_Byte0 "-";
BA_ "Version" SG_ 2015 GST_ALL_Byte0 "0.00.01";
BA_ "UsrSigPurpose" SG_ 2015 GST_ALL_Byte0 2;
BA_ "UserSigValidity" SG_ 2015 GST_ALL_Byte1 3;
BA_ "Description" SG_ 2015 GST_ALL_Byte1 "-";
BA_ "Version" SG_ 2015 GST_ALL_Byte1 "0.00.01";
BA_ "UsrSigPurpose" SG_ 2015 GST_ALL_Byte1 2;
BA_ "UserSigValidity" SG_ 2015 GST_ALL_Byte2 3;
BA_ "Description" SG_ 2015 GST_ALL_Byte2 "-";
BA_ "Version" SG_ 2015 GST_ALL_Byte2 "0.00.01";
BA_ "UsrSigPurpose" SG_ 2015 GST_ALL_Byte2 2;
BA_ "UserSigValidity" SG_ 2015 GST_ALL_Byte3 3;
BA_ "Description" SG_ 2015 GST_ALL_Byte3 "-";
BA_ "Version" SG_ 2015 GST_ALL_Byte3 "0.00.01";
BA_ "UsrSigPurpose" SG_ 2015 GST_ALL_Byte3 2;
BA_ "UserSigValidity" SG_ 2015 GST_ALL_Byte4 3;
BA_ "Description" SG_ 2015 GST_ALL_Byte4 "-";
BA_ "Version" SG_ 2015 GST_ALL_Byte4 "0.00.01";
BA_ "UsrSigPurpose" SG_ 2015 GST_ALL_Byte4 2;
BA_ "UserSigValidity" SG_ 2015 GST_ALL_Byte5 3;
BA_ "Description" SG_ 2015 GST_ALL_Byte5 "-";
BA_ "Version" SG_ 2015 GST_ALL_Byte5 "0.00.01";
BA_ "UsrSigPurpose" SG_ 2015 GST_ALL_Byte5 2;
BA_ "UserSigValidity" SG_ 2015 GST_ALL_Byte6 3;
BA_ "Description" SG_ 2015 GST_ALL_Byte6 "-";
BA_ "Version" SG_ 2015 GST_ALL_Byte6 "0.00.01";
BA_ "UsrSigPurpose" SG_ 2015 GST_ALL_Byte6 2;
BA_ "UserSigValidity" SG_ 2015 GST_ALL_Byte7 3;
BA_ "Description" SG_ 2015 GST_ALL_Byte7 "-";
BA_ "Version" SG_ 2015 GST_ALL_Byte7 "0.00.01";
BA_ "UsrSigPurpose" SG_ 2015 GST_ALL_Byte7 2;
BA_ "UserSigValidity" SG_ 1988 GST_FR_CMR_Byte0 3;
BA_ "Description" SG_ 1988 GST_FR_CMR_Byte0 "-";
BA_ "Version" SG_ 1988 GST_FR_CMR_Byte0 "0.00.01";
BA_ "UsrSigPurpose" SG_ 1988 GST_FR_CMR_Byte0 2;
BA_ "UserSigValidity" SG_ 1988 GST_FR_CMR_Byte1 3;
BA_ "Description" SG_ 1988 GST_FR_CMR_Byte1 "-";
BA_ "Version" SG_ 1988 GST_FR_CMR_Byte1 "0.00.01";
BA_ "UsrSigPurpose" SG_ 1988 GST_FR_CMR_Byte1 2;
BA_ "UserSigValidity" SG_ 1988 GST_FR_CMR_Byte2 3;
BA_ "Description" SG_ 1988 GST_FR_CMR_Byte2 "-";
BA_ "Version" SG_ 1988 GST_FR_CMR_Byte2 "0.00.01";
BA_ "UsrSigPurpose" SG_ 1988 GST_FR_CMR_Byte2 2;
BA_ "UserSigValidity" SG_ 1988 GST_FR_CMR_Byte3 3;
BA_ "Description" SG_ 1988 GST_FR_CMR_Byte3 "-";
BA_ "Version" SG_ 1988 GST_FR_CMR_Byte3 "0.00.01";
BA_ "UsrSigPurpose" SG_ 1988 GST_FR_CMR_Byte3 2;
BA_ "UserSigValidity" SG_ 1988 GST_FR_CMR_Byte4 3;
BA_ "Description" SG_ 1988 GST_FR_CMR_Byte4 "-";
BA_ "Version" SG_ 1988 GST_FR_CMR_Byte4 "0.00.01";
BA_ "UsrSigPurpose" SG_ 1988 GST_FR_CMR_Byte4 2;
BA_ "UserSigValidity" SG_ 1988 GST_FR_CMR_Byte5 3;
BA_ "Description" SG_ 1988 GST_FR_CMR_Byte5 "-";
BA_ "Version" SG_ 1988 GST_FR_CMR_Byte5 "0.00.01";
BA_ "UsrSigPurpose" SG_ 1988 GST_FR_CMR_Byte5 2;
BA_ "UserSigValidity" SG_ 1988 GST_FR_CMR_Byte6 3;
BA_ "Description" SG_ 1988 GST_FR_CMR_Byte6 "-";
BA_ "Version" SG_ 1988 GST_FR_CMR_Byte6 "0.00.01";
BA_ "UsrSigPurpose" SG_ 1988 GST_FR_CMR_Byte6 2;
BA_ "UserSigValidity" SG_ 1988 GST_FR_CMR_Byte7 3;
BA_ "Description" SG_ 1988 GST_FR_CMR_Byte7 "-";
BA_ "Version" SG_ 1988 GST_FR_CMR_Byte7 "0.00.01";
BA_ "UsrSigPurpose" SG_ 1988 GST_FR_CMR_Byte7 2;
BA_ "UserSigValidity" SG_ 2000 GST_FR_RDR_Byte0 3;
BA_ "Description" SG_ 2000 GST_FR_RDR_Byte0 "-";
BA_ "Version" SG_ 2000 GST_FR_RDR_Byte0 "0.00.01";
BA_ "UsrSigPurpose" SG_ 2000 GST_FR_RDR_Byte0 2;
BA_ "UserSigValidity" SG_ 2000 GST_FR_RDR_Byte1 3;
BA_ "Description" SG_ 2000 GST_FR_RDR_Byte1 "-";
BA_ "Version" SG_ 2000 GST_FR_RDR_Byte1 "0.00.01";
BA_ "UsrSigPurpose" SG_ 2000 GST_FR_RDR_Byte1 2;
BA_ "UserSigValidity" SG_ 2000 GST_FR_RDR_Byte2 3;
BA_ "Description" SG_ 2000 GST_FR_RDR_Byte2 "-";
BA_ "Version" SG_ 2000 GST_FR_RDR_Byte2 "0.00.01";
BA_ "UsrSigPurpose" SG_ 2000 GST_FR_RDR_Byte2 2;
BA_ "UserSigValidity" SG_ 2000 GST_FR_RDR_Byte3 3;
BA_ "Description" SG_ 2000 GST_FR_RDR_Byte3 "-";
BA_ "Version" SG_ 2000 GST_FR_RDR_Byte3 "0.00.01";
BA_ "UsrSigPurpose" SG_ 2000 GST_FR_RDR_Byte3 2;
BA_ "UserSigValidity" SG_ 2000 GST_FR_RDR_Byte4 3;
BA_ "Description" SG_ 2000 GST_FR_RDR_Byte4 "-";
BA_ "Version" SG_ 2000 GST_FR_RDR_Byte4 "0.00.01";
BA_ "UsrSigPurpose" SG_ 2000 GST_FR_RDR_Byte4 2;
BA_ "UserSigValidity" SG_ 2000 GST_FR_RDR_Byte5 3;
BA_ "Description" SG_ 2000 GST_FR_RDR_Byte5 "-";
BA_ "Version" SG_ 2000 GST_FR_RDR_Byte5 "0.00.01";
BA_ "UsrSigPurpose" SG_ 2000 GST_FR_RDR_Byte5 2;
BA_ "UserSigValidity" SG_ 2000 GST_FR_RDR_Byte6 3;
BA_ "Description" SG_ 2000 GST_FR_RDR_Byte6 "-";
BA_ "Version" SG_ 2000 GST_FR_RDR_Byte6 "0.00.01";
BA_ "UsrSigPurpose" SG_ 2000 GST_FR_RDR_Byte6 2;
BA_ "UserSigValidity" SG_ 2000 GST_FR_RDR_Byte7 3;
BA_ "Description" SG_ 2000 GST_FR_RDR_Byte7 "-";
BA_ "Version" SG_ 2000 GST_FR_RDR_Byte7 "0.00.01";
BA_ "UsrSigPurpose" SG_ 2000 GST_FR_RDR_Byte7 2;
BA_ "UserSigValidity" SG_ 1157 CF_HDA_InfoDisplay 3;
BA_ "Description" SG_ 1157 CF_HDA_InfoDisplay "This is HDA information display needed for the cluster pop-up display.";
BA_ "Version" SG_ 1157 CF_HDA_InfoDisplay "2.62.02";
BA_ "UserSigValidity" SG_ 1157 CF_HDA_InfoDisplay2 3;
BA_ "Description" SG_ 1157 CF_HDA_InfoDisplay2 "This is HDA/LFA information display needed for the cluster pop-up display.";
BA_ "Version" SG_ 1157 CF_HDA_InfoDisplay2 "2.69.00";
BA_ "UserSigValidity" SG_ 1157 CF_HDA_LFA_SymbolState 3;
BA_ "Description" SG_ 1157 CF_HDA_LFA_SymbolState "This signal shows the state of steering assist.";
BA_ "Version" SG_ 1157 CF_HDA_LFA_SymbolState "2.62.02";
BA_ "UserSigValidity" SG_ 1157 CF_HDA_LFA_Wrn_Snd 3;
BA_ "Description" SG_ 1157 CF_HDA_LFA_Wrn_Snd "This signal indicates HDA/LFA Additional Warning Sound for ACSF B1.";
BA_ "Version" SG_ 1157 CF_HDA_LFA_Wrn_Snd "2.62.02";
BA_ "UserSigValidity" SG_ 1157 CF_HDA_Mode 3;
BA_ "Description" SG_ 1157 CF_HDA_Mode "This is HDA Control Mode needed for longitudinal/lateral control and cluster display.";
BA_ "Version" SG_ 1157 CF_HDA_Mode "2.62.02";
BA_ "UserSigValidity" SG_ 1157 CF_HDA_Opt_USM 3;
BA_ "Description" SG_ 1157 CF_HDA_Opt_USM "This is HDA system status needed for the USM display. (CLU or AVN)";
BA_ "Version" SG_ 1157 CF_HDA_Opt_USM "2.62.02";
BA_ "UserSigValidity" SG_ 1470 HU_NaviCamSettingStatus 1;
BA_ "Description" SG_ 1470 HU_NaviCamSettingStatus "Navi Camera alert setting status_x000D_

_x000D_

+ Bit-coded field (On 1, Off 0)_x000D_

   - bit 0 : Fixed Camera_x000D_

   - bit 1 : Signal/Speed Violation Camera_x000D_

   - bit 2 : Movable Camera_x000D_

   - bit 3 : User Registration Fixed Camera";
BA_ "Version" SG_ 1470 HU_NaviCamSettingStatus "2.38.05";
BA_ "UserSigValidity" SG_ 1470 HU_NaviStatus 1;
BA_ "GenSigStartValue" SG_ 1470 HU_NaviStatus 3;
BA_ "Description" SG_ 1470 HU_NaviStatus "Navi Operation Status";
BA_ "Version" SG_ 1470 HU_NaviStatus "2.29.01";
BA_ "UserSigValidity" SG_ 1407 HU_AdasSupport 1;
BA_ "Description" SG_ 1407 HU_AdasSupport "Information about ADAS support";
BA_ "Version" SG_ 1407 HU_AdasSupport "2.38.05";
BA_ "UserSigValidity" SG_ 1407 HU_DistributeInfo 1;
BA_ "GenSigStartValue" SG_ 1407 HU_DistributeInfo 255;
BA_ "Description" SG_ 1407 HU_DistributeInfo "Information about nation of navigation";
BA_ "Version" SG_ 1407 HU_DistributeInfo "2.31.02";
BA_ "UserSigValidity" SG_ 1407 HU_Type 1;
BA_ "GenSigStartValue" SG_ 1407 HU_Type 255;
BA_ "Description" SG_ 1407 HU_Type "This signal indicates the type of H/U

";
BA_ "Version" SG_ 1407 HU_Type "2.68.08";
BA_ "UserSigValidity" SG_ 832 CF_HBA_Lamp 3;
BA_ "Description" SG_ 832 CF_HBA_Lamp "HBA System Indicator Lamp Status ";
BA_ "Version" SG_ 832 CF_HBA_Lamp "2.46.06";
BA_ "UserSigValidity" SG_ 832 CF_HBA_Opt 3;
BA_ "Description" SG_ 832 CF_HBA_Opt "HBA System Option Information to Lamp Controller";
BA_ "Version" SG_ 832 CF_HBA_Opt "2.46.06";
BA_ "UserSigValidity" SG_ 832 CF_HBA_Opt_USM 3;
BA_ "Description" SG_ 832 CF_HBA_Opt_USM "HBA System Option & USM setting Information to Cluster";
BA_ "Version" SG_ 832 CF_HBA_Opt_USM "2.58.00";
BA_ "UserSigValidity" SG_ 832 CF_HBA_SysState 3;
BA_ "Description" SG_ 832 CF_HBA_SysState "This signal indicates the status of High Beam Assist system.";
BA_ "Version" SG_ 832 CF_HBA_SysState "2.46.06";
BA_ "UserSigValidity" SG_ 832 CF_LKA_ActToi 3;
BA_ "Description" SG_ 832 CF_LKA_ActToi "This is a flag that is set to 1 when requesting the steering to activate the torque overlay interface (TOI).  This must be done before an attempt is made to request non-zero steering torque overlay.";
BA_ "Version" SG_ 832 CF_LKA_ActToi "2.46.06";
BA_ "UserSigValidity" SG_ 832 CF_LKA_CRC 3;
BA_ "GenSigStartValue" SG_ 832 CF_LKA_CRC 255;
BA_ "Description" SG_ 832 CF_LKA_CRC "Sender calculates CRC : _x000D_

The sender of safety relevant CAN output signals shall protect the output signals with a CRC on application software level._x000D_

_x000D_

Each CAN frame with safety relevant signals shall contain its own CRC._x000D_

 ";
BA_ "Version" SG_ 832 CF_LKA_CRC "2.46.06";
BA_ "UserSigValidity" SG_ 832 CF_LKA_FusionState 3;
BA_ "Description" SG_ 832 CF_LKA_FusionState "Fusion Function State";
BA_ "Version" SG_ 832 CF_LKA_FusionState "2.46.06";
BA_ "UserSigValidity" SG_ 832 CF_LKA_HandsOff_Snd 3;
BA_ "Description" SG_ 832 CF_LKA_HandsOff_Snd "Hands-Off Sound Warning";
BA_ "Version" SG_ 832 CF_LKA_HandsOff_Snd "2.53.03";
BA_ "UserSigValidity" SG_ 832 CF_LKA_LaneRecogState 3;
BA_ "Description" SG_ 832 CF_LKA_LaneRecogState "Lane Recognition Display";
BA_ "Version" SG_ 832 CF_LKA_LaneRecogState "2.53.03";
BA_ "UserSigValidity" SG_ 832 CF_LKA_LHWarning 3;
BA_ "Description" SG_ 832 CF_LKA_LHWarning "This is a simple warning signal that can be used by the HMI to alert the driver to a lane departure on the left hand side of the vehicle.";
BA_ "Version" SG_ 832 CF_LKA_LHWarning "2.57.06";
BA_ "UserSigValidity" SG_ 832 CF_LKA_MsgCount 3;
BA_ "Description" SG_ 832 CF_LKA_MsgCount "This is a counter (counts continuously from 0 to its maximum bit count and back to 0 again), that can be used for checking the internal logic of the LKA controller by the HMI. On power-up, this signal starts counting from 0.";
BA_ "Version" SG_ 832 CF_LKA_MsgCount "2.46.06";
BA_ "UserSigValidity" SG_ 832 CF_LKA_Opt_USM 3;
BA_ "Description" SG_ 832 CF_LKA_Opt_USM "LDW/LKA System Option & USM setting Information to Cluster";
BA_ "Version" SG_ 832 CF_LKA_Opt_USM "2.59.04";
BA_ "UserSigValidity" SG_ 832 CF_LKA_RHWarning 3;
BA_ "Description" SG_ 832 CF_LKA_RHWarning "This is a simple warning signal that can be used by the HMI to alert the driver to a lane departure on the right hand side of the vehicle.";
BA_ "Version" SG_ 832 CF_LKA_RHWarning "2.57.06";
BA_ "UserSigValidity" SG_ 832 CF_LKA_SymbolState 3;
BA_ "Description" SG_ 832 CF_LKA_SymbolState "LKA Symbol Display";
BA_ "Version" SG_ 832 CF_LKA_SymbolState "2.58.03";
BA_ "UserSigValidity" SG_ 832 CF_LKA_SysState 3;
BA_ "Description" SG_ 832 CF_LKA_SysState "A signal indicating the current operational state of the system.";
BA_ "Version" SG_ 832 CF_LKA_SysState "2.46.06";
BA_ "UserSigValidity" SG_ 832 CF_LKA_SysWarning 3;
BA_ "Description" SG_ 832 CF_LKA_SysWarning "A signal that provides additional information on the operation of the LKA system for the HMI to display to the driver. This includes additional fault information, reasons for unavailability of the system and additional warnings like the hands-off warning";
BA_ "Version" SG_ 832 CF_LKA_SysWarning "2.66.04";
BA_ "UserSigValidity" SG_ 832 CF_LKA_ToiFlt 3;
BA_ "Description" SG_ 832 CF_LKA_ToiFlt "This fault flag is set when a fault in the LKA system has been detected by the MFC such that LKA can no longer function. CAN failures, internal video ECU failures, hard-wired component (e.g. master switch) failures and other system logic failures are all";
BA_ "Version" SG_ 832 CF_LKA_ToiFlt "2.46.06";
BA_ "UserSigValidity" SG_ 832 CF_LKA_USM_Mode 3;
BA_ "Description" SG_ 832 CF_LKA_USM_Mode "This signal indicates LKA USM Mode";
BA_ "Version" SG_ 832 CF_LKA_USM_Mode "2.59.07";
BA_ "UserSigValidity" SG_ 832 CR_LKA_StrToqReq 3;
BA_ "GenSigStartValue" SG_ 832 CR_LKA_StrToqReq 1024;
BA_ "Description" SG_ 832 CR_LKA_StrToqReq "This is the driver torque overlay demand value. A negative value represents a torque that would accelerate the steering wheel in a clockwise direction. This signal is always zero whilst the TOI is inactive.";
BA_ "Version" SG_ 832 CR_LKA_StrToqReq "2.46.06";
BA_ "UserSigValidity" SG_ 1342 CF_DAW_Opt_USM_NEW 3;
BA_ "Description" SG_ 1342 CF_DAW_Opt_USM_NEW "This signal represents the lastest DAW ON/OFF value of USM.

※ This signal applies from vehicles produced after '19.1.";
BA_ "Version" SG_ 1342 CF_DAW_Opt_USM_NEW "2.67.00";
BA_ "UserSigValidity" SG_ 1342 CF_DAW_Status 3;
BA_ "Description" SG_ 1342 CF_DAW_Status "This signal represents DAW Status or Attention Level.";
BA_ "Version" SG_ 1342 CF_DAW_Status "2.67.00";
BA_ "UserSigValidity" SG_ 1342 CF_DAW_TimeReset 3;
BA_ "Description" SG_ 1342 CF_DAW_TimeReset "This signal requests CLU 'Last Break Time' Reset.



DAW send '0x1' when detecting driver's rest.";
BA_ "Version" SG_ 1342 CF_DAW_TimeReset "2.67.00";
BA_ "UserSigValidity" SG_ 1342 CF_DAW_Warn 3;
BA_ "Description" SG_ 1342 CF_DAW_Warn "0x1 value requests DAW Rest recommend warning message popup at CLU.

0x2 value requests HDA/LFA Hands-Off call at TMS.";
BA_ "Version" SG_ 1342 CF_DAW_Warn "2.68.03";
BA_ "UserSigValidity" SG_ 1342 CF_ISLW_Addinfo_Display 3;
BA_ "Description" SG_ 1342 CF_ISLW_Addinfo_Display "This signal indicates additional information of Traffic sign. For example no passing.

";
BA_ "Version" SG_ 1342 CF_ISLW_Addinfo_Display "2.67.00";
BA_ "UserSigValidity" SG_ 1342 CF_ISLW_OvrlapSign_Dis 3;
BA_ "Description" SG_ 1342 CF_ISLW_OvrlapSign_Dis "Indicates presence of Overlap sign";
BA_ "Version" SG_ 1342 CF_ISLW_OvrlapSign_Dis "2.67.00";
BA_ "UserSigValidity" SG_ 1342 CF_ISLW_Spd_Dis_CLU_Main 3;
BA_ "Description" SG_ 1342 CF_ISLW_Spd_Dis_CLU_Main "Speed information for cluster display



(0x1~0xFCH : 1*(HEX VALUE)



[KPH or MPH : Reference signal is CF_Clu_SPEED_UNIT of CLU])";
BA_ "Version" SG_ 1342 CF_ISLW_Spd_Dis_CLU_Main "2.67.00";
BA_ "UserSigValidity" SG_ 1342 CF_ISLW_Spd_Dis_NAVI_Main 3;
BA_ "Description" SG_ 1342 CF_ISLW_Spd_Dis_NAVI_Main "Speed information for navigation display



(0x1~0xFCH : 1*(HEX VALUE)



[KPH or MPH : Reference signal is Navi_ISLW_SpdUnit of Navigation])";
BA_ "Version" SG_ 1342 CF_ISLW_Spd_Dis_NAVI_Main "2.67.00";
BA_ "UserSigValidity" SG_ 1342 CF_ISLW_Status 3;
BA_ "Description" SG_ 1342 CF_ISLW_Status "Validity of ISLW";
BA_ "Version" SG_ 1342 CF_ISLW_Status "2.67.00";
BA_ "UserSigValidity" SG_ 1342 CF_LeadVehDptAlert_Display 3;
BA_ "Description" SG_ 1342 CF_LeadVehDptAlert_Display "Message for displaying LVDA(Lead Vehicle Departure Alert) Warning";
BA_ "Version" SG_ 1342 CF_LeadVehDptAlert_Display "2.67.00";
BA_ "UserSigValidity" SG_ 1342 CF_LeadVehDptAlert_USM 3;
BA_ "Description" SG_ 1342 CF_LeadVehDptAlert_USM "LVDA USM state";
BA_ "Version" SG_ 1342 CF_LeadVehDptAlert_USM "2.67.00";
BA_ "UserSigValidity" SG_ 1342 ISLA_IcyWrn 3;
BA_ "Description" SG_ 1342 ISLA_IcyWrn "This is a warning signal when the snow or ice sign is recognized when it is less than 4˚C.";
BA_ "Version" SG_ 1342 ISLA_IcyWrn "2.67.03";
BA_ "UserSigValidity" SG_ 1342 ISLA_SpdChgReq 3;
BA_ "Description" SG_ 1342 ISLA_SpdChgReq "This is a signal requesting to change the set speed of MSLA/CC/SCC to the ISLA speed.";
BA_ "Version" SG_ 1342 ISLA_SpdChgReq "2.67.03";
BA_ "UserSigValidity" SG_ 1342 ISLA_SpdwOffst 3;
BA_ "Description" SG_ 1342 ISLA_SpdwOffst "This is a ISLA speed with offset to change the set speed of MSLA/CC/SCC.

Unit (kph or mph) refers to cluster signal : CF_Clu_SPEED_UNIT@CLU11";
BA_ "Version" SG_ 1342 ISLA_SpdwOffst "2.67.03";
BA_ "UserSigValidity" SG_ 1342 ISLA_SpdWrn 3;
BA_ "Description" SG_ 1342 ISLA_SpdWrn "This is a warning signal when VANZ exceeds the speed limit.";
BA_ "Version" SG_ 1342 ISLA_SpdWrn "2.67.03";
BA_ "UserSigValidity" SG_ 1342 ISLA_SwIgnoreReq 3;
BA_ "Description" SG_ 1342 ISLA_SwIgnoreReq "This is a signal requesting to ignore the -(SET) or +(SET) switch input of the driver.";
BA_ "Version" SG_ 1342 ISLA_SwIgnoreReq "2.67.03";
BA_ "UserSigValidity" SG_ 1342 ISLA_SymFlashMod 3;
BA_ "Description" SG_ 1342 ISLA_SymFlashMod "This is a signal for the flashing mode of the symbol.";
BA_ "Version" SG_ 1342 ISLA_SymFlashMod "2.67.03";
BA_ "UserSigValidity" SG_ 1260 CF_ISLW_ConInfo_Sta_Con1 3;
BA_ "Description" SG_ 1260 CF_ISLW_ConInfo_Sta_Con1 "Indicates 1st conditional traffic sign status";
BA_ "Version" SG_ 1260 CF_ISLW_ConInfo_Sta_Con1 "2.66.00";
BA_ "UserSigValidity" SG_ 1260 CF_ISLW_ConInfo_Sta_Con2 3;
BA_ "Description" SG_ 1260 CF_ISLW_ConInfo_Sta_Con2 "Indicates 2nd conditional traffic sign status";
BA_ "Version" SG_ 1260 CF_ISLW_ConInfo_Sta_Con2 "2.66.00";
BA_ "UserSigValidity" SG_ 1260 CF_ISLW_Spd_Dis_CLU_Con1 3;
BA_ "Description" SG_ 1260 CF_ISLW_Spd_Dis_CLU_Con1 "Indicates speed limit of 1st conditional traffic sign_x000D_

_x000D_

0x0:No Recognition (Default)_x000D_

_x000D_

0x1~0xFC:1~252 (PH)=1*(HEX)_x000D_

_x000D_

               [KPH or MPH : CLU11의 SPEED_UNIT 신호 참조]_x000D_

_x000D_

0xFD:LHD Co";
BA_ "Version" SG_ 1260 CF_ISLW_Spd_Dis_CLU_Con1 "2.49.03";
BA_ "UserSigValidity" SG_ 1260 CF_ISLW_Spd_Dis_CLU_Con2 3;
BA_ "Description" SG_ 1260 CF_ISLW_Spd_Dis_CLU_Con2 "Indicates speed limit of 2nd conditional traffic sign_x000D_

_x000D_

0x0:No Recognition (Default)_x000D_

_x000D_

0x1~0xFC:1~252 (PH)=1*(HEX)_x000D_

_x000D_

               [KPH or MPH : CLU11의 SPEED_UNIT 신호 참조]_x000D_

_x000D_

0xFD:LHD Co";
BA_ "Version" SG_ 1260 CF_ISLW_Spd_Dis_CLU_Con2 "2.49.03";
BA_ "UserSigValidity" SG_ 1260 CF_ISLW_Spd_Dis_NAVI_Con1 3;
BA_ "Description" SG_ 1260 CF_ISLW_Spd_Dis_NAVI_Con1 "Indicates speed limit of 1st conditional traffic sign_x000D_

_x000D_

0x0:No Recognition (Default)_x000D_

_x000D_

0x1~0xFC:1~252 (PH)=1*(HEX)_x000D_

_x000D_

               [KPH or MPH : NAVI_ISLW의 Navi_ISLW_Spd_Unit 신호 참조]_x000D_

_x000D_

";
BA_ "Version" SG_ 1260 CF_ISLW_Spd_Dis_NAVI_Con1 "2.50.03";
BA_ "UserSigValidity" SG_ 1260 CF_ISLW_Spd_Dis_NAVI_Con2 3;
BA_ "Description" SG_ 1260 CF_ISLW_Spd_Dis_NAVI_Con2 "Indicates speed limit of 2nd conditional traffic sign_x000D_

_x000D_

0x0:No Recognition (Default)_x000D_

_x000D_

0x1~0xFC:1~252 (PH)=1*(HEX)_x000D_

_x000D_

               [KPH or MPH : NAVI_ISLW의 Navi_SLIF_Spd_Unit 신호 참조]_x000D_

_x000D_

";
BA_ "Version" SG_ 1260 CF_ISLW_Spd_Dis_NAVI_Con2 "2.50.03";
BA_ "UserSigValidity" SG_ 1260 ISLA_AddtnlSign 3;
BA_ "Description" SG_ 1260 ISLA_AddtnlSign "This is a signal for additional sign";
BA_ "Version" SG_ 1260 ISLA_AddtnlSign "2.68.07";
BA_ "UserSigValidity" SG_ 1260 ISLA_AutoUsmSta 3;
BA_ "Description" SG_ 1260 ISLA_AutoUsmSta "This is a signal for ISLA AUTO USM set by the driver.";
BA_ "Version" SG_ 1260 ISLA_AutoUsmSta "2.67.03";
BA_ "UserSigValidity" SG_ 1260 ISLA_Cntry 3;
BA_ "GenSigStartValue" SG_ 1260 ISLA_Cntry 15;
BA_ "Description" SG_ 1260 ISLA_Cntry "This is a signal for categorizing countries";
BA_ "Version" SG_ 1260 ISLA_Cntry "2.71.02";
BA_ "UserSigValidity" SG_ 1260 ISLA_OffstUsmSta 3;
BA_ "Description" SG_ 1260 ISLA_OffstUsmSta "This is a signal for offset speed set by the driver.

Unit (kph or mph) refers to cluster signal : CF_Clu_SPEED_UNIT@CLU11";
BA_ "Version" SG_ 1260 ISLA_OffstUsmSta "2.67.03";
BA_ "UserSigValidity" SG_ 1260 ISLA_OptUsmSta 3;
BA_ "Description" SG_ 1260 ISLA_OptUsmSta "This is a ISLA Option USM signal set by the driver.";
BA_ "Version" SG_ 1260 ISLA_OptUsmSta "2.67.03";
BA_ "UserSigValidity" SG_ 1260 ISLA_Popup 3;
BA_ "Description" SG_ 1260 ISLA_Popup "This is a signal for ISLA pop-up.";
BA_ "Version" SG_ 1260 ISLA_Popup "2.67.03";
BA_ "UserSigValidity" SG_ 1260 ISLA_SchoolZone 3;
BA_ "Description" SG_ 1260 ISLA_SchoolZone "This is a signal for School Zone";
BA_ "Version" SG_ 1260 ISLA_SchoolZone "2.68.07";
BA_ "UserSigValidity" SG_ 1156 CF_LaneInfo_AliveCounter 3;
BA_ "Description" SG_ 1156 CF_LaneInfo_AliveCounter "This indicates the alive status of lane information message.";
BA_ "Version" SG_ 1156 CF_LaneInfo_AliveCounter "2.46.06";
BA_ "UserSigValidity" SG_ 1156 CF_LeftLine_Departure 3;
BA_ "Description" SG_ 1156 CF_LeftLine_Departure "This signal indicates the lane departure status of left line.";
BA_ "Version" SG_ 1156 CF_LeftLine_Departure "2.46.06";
BA_ "UserSigValidity" SG_ 1156 CF_LeftLine_HeadingAngle 3;
BA_ "Description" SG_ 1156 CF_LeftLine_HeadingAngle "This signal outputs the heading angle of left line.";
BA_ "Version" SG_ 1156 CF_LeftLine_HeadingAngle "2.46.06";
BA_ "UserSigValidity" SG_ 1156 CF_LeftLine_Position 3;
BA_ "Description" SG_ 1156 CF_LeftLine_Position "This signal outputs the position of left line from camera center.";
BA_ "Version" SG_ 1156 CF_LeftLine_Position "2.46.06";
BA_ "UserSigValidity" SG_ 1156 CF_LeftLine_Quality 3;
BA_ "Description" SG_ 1156 CF_LeftLine_Quality "This signal indicates the quality of left line.";
BA_ "Version" SG_ 1156 CF_LeftLine_Quality "2.46.06";
BA_ "UserSigValidity" SG_ 1156 CF_RightLine_Departure 3;
BA_ "Description" SG_ 1156 CF_RightLine_Departure "This signal indicates the lane departure status of right line.";
BA_ "Version" SG_ 1156 CF_RightLine_Departure "2.46.06";
BA_ "UserSigValidity" SG_ 1156 CF_RightLine_HeadingAngle 3;
BA_ "Description" SG_ 1156 CF_RightLine_HeadingAngle "This signal outputs the heading angle of right line.";
BA_ "Version" SG_ 1156 CF_RightLine_HeadingAngle "2.46.06";
BA_ "UserSigValidity" SG_ 1156 CF_RightLine_Position 3;
BA_ "Description" SG_ 1156 CF_RightLine_Position "This signal outputs the position of right line from camera center.";
BA_ "Version" SG_ 1156 CF_RightLine_Position "2.46.06";
BA_ "UserSigValidity" SG_ 1156 CF_RightLine_Quality 3;
BA_ "Description" SG_ 1156 CF_RightLine_Quality "This signal indicates the quality of right line.";
BA_ "Version" SG_ 1156 CF_RightLine_Quality "2.46.06";
BA_ "UserSigValidity" SG_ 1191 CF_FCA_Equip_FR_CMR 3;
BA_ "Description" SG_ 1191 CF_FCA_Equip_FR_CMR "A signal indicating the FCA sensor type. (for detecting coding error)";
BA_ "Version" SG_ 1191 CF_FCA_Equip_FR_CMR "2.71.00";
BA_ "UserSigValidity" SG_ 1069 ID_CIPV 3;
BA_ "Description" SG_ 1069 ID_CIPV "Valid Object = 1 to 127

- ID detected by front camera can vary depending on vehicle environment.

- Additional logic would be required to apply this signal for ISG. 

- Confirmaiton by Autonomous Driving Engineering Team is required to use ID_CIPV signa";
BA_ "Version" SG_ 1069 ID_CIPV "2.68.09";
BA_ "UserSigValidity" SG_ 1069 Longitudinal_Distance 3;
BA_ "Description" SG_ 1069 Longitudinal_Distance "Distance to the object for ISG.

- Distance detected by front camera can vary depending on vehicle environment.

- Additional logic would be required to apply this signal for ISG. ";
BA_ "Version" SG_ 1069 Longitudinal_Distance "2.68.06";
BA_ "UserSigValidity" SG_ 1069 Relative_Velocity 3;
BA_ "Description" SG_ 1069 Relative_Velocity "+ : Preceding, - : Oncoming

- Velocity detected by front camera can vary depending on vehicle environment.

- Additional logic would be required to apply this signal for ISG. ";
BA_ "Version" SG_ 1069 Relative_Velocity "2.68.06";
BA_ "UserSigValidity" SG_ 897 CF_Mdps_LKA_FUNC 3;
BA_ "Description" SG_ 897 CF_Mdps_LKA_FUNC "This signal indicates whether the LKA function of MDPS is plugged in or not._x000D_

";
BA_ "Version" SG_ 897 CF_Mdps_LKA_FUNC "2.47.02";
BA_ "UserSigValidity" SG_ 897 CF_Mdps_Stat 3;
BA_ "GenSigStartValue" SG_ 897 CF_Mdps_Stat 1;
BA_ "Description" SG_ 897 CF_Mdps_Stat "This signal indicates the status of the automatic steering function.";
BA_ "Version" SG_ 897 CF_Mdps_Stat "2.47.00";
BA_ "UserSigValidity" SG_ 897 CF_Mdps_Type 3;
BA_ "Description" SG_ 897 CF_Mdps_Type "Information regarding the type of MDPS. (C-MDPS / R-MDPS)";
BA_ "Version" SG_ 897 CF_Mdps_Type "2.45.07";
BA_ "UserSigValidity" SG_ 593 CF_Mdps_FailStat 3;
BA_ "Description" SG_ 593 CF_Mdps_FailStat "This fault flag is set whilst the MDPS TOI is in a fail state and has not yet recovered from it. This could either be due to an MDPS detected fault (as communicated by the ‘CF_Mdps_ToiFlt’ flag) or an LKA detected fault (as communicated by the ‘CF_";
BA_ "Version" SG_ 593 CF_Mdps_FailStat "2.47.00";
BA_ "UserSigValidity" SG_ 593 CF_Mdps_MsgCount2 3;
BA_ "Description" SG_ 593 CF_Mdps_MsgCount2 "This is a counter (counts continuously from 0 to its maximum bit count and back to 0 again), that can be used for checking the internal logic of the LKA controller. On power-up, this signal starts counting from 0.";
BA_ "Version" SG_ 593 CF_Mdps_MsgCount2 "2.47.00";
BA_ "UserSigValidity" SG_ 593 CF_Mdps_ToiActive 3;
BA_ "Description" SG_ 593 CF_Mdps_ToiActive "This flag is set to 1 in response to the LKA Controller requesting the activation of the torque interface and set back to 0 in response to the LKA Controller requesting the de-activation of the torque interface.";
BA_ "Version" SG_ 593 CF_Mdps_ToiActive "2.47.00";
BA_ "UserSigValidity" SG_ 593 CF_Mdps_ToiFlt 3;
BA_ "Description" SG_ 593 CF_Mdps_ToiFlt "This fault flag is set when a fault within the MDPS system has been detected such that the LKA TOI can no longer function. CAN failures, internal MDPS failures, and LKA controller logic failures are all reported by this flag. Failures reported by the LKA";
BA_ "Version" SG_ 593 CF_Mdps_ToiFlt "2.47.00";
BA_ "UserSigValidity" SG_ 593 CF_Mdps_ToiUnavail 3;
BA_ "Description" SG_ 593 CF_Mdps_ToiUnavail "This is a flag that is set when the MDPS is not faulty, but is temporarily unable to activate the TOI due to steering torque limiting e.g. when the supply voltage is too low.";
BA_ "Version" SG_ 593 CF_Mdps_ToiUnavail "2.47.00";
BA_ "UserSigValidity" SG_ 593 CF_Mdps12_CRC 3;
BA_ "GenSigStartValue" SG_ 593 CF_Mdps12_CRC 255;
BA_ "Description" SG_ 593 CF_Mdps12_CRC "Sender calculates CRC : _x000D_

The sender of safety relevant CAN output signals shall protect the output signals with a CRC on application software level._x000D_

_x000D_

Each CAN frame with safety relevant signals shall contain its own CRC._x000D_

�";
BA_ "Version" SG_ 593 CF_Mdps12_CRC "2.45.07";
BA_ "UserSigValidity" SG_ 593 CR_Mdps_StrColTq 3;
BA_ "GenSigStartValue" SG_ 593 CR_Mdps_StrColTq 1024;
BA_ "Description" SG_ 593 CR_Mdps_StrColTq "The human driver input torque on the steering column as measured by the MDPS torque and angle sensor.  A negative value represents a torque that would accelerate the steering wheel in clockwise direction.";
BA_ "Version" SG_ 593 CR_Mdps_StrColTq "2.57.05";
BA_ "UserSigValidity" SG_ 2679898130 Meas1Data 3;
BA_ "Description" SG_ 2679898130 Meas1Data "-";
BA_ "Version" SG_ 2679898130 Meas1Data "0.00.01";
BA_ "UsrSigPurpose" SG_ 2679898130 Meas1Data 2;
BA_ "UserSigValidity" SG_ 2679898131 Meas2Data 3;
BA_ "Description" SG_ 2679898131 Meas2Data "-";
BA_ "Version" SG_ 2679898131 Meas2Data "0.00.01";
BA_ "UsrSigPurpose" SG_ 2679898131 Meas2Data 2;
BA_ "UserSigValidity" SG_ 2679898132 Meas3Data 3;
BA_ "Description" SG_ 2679898132 Meas3Data "-";
BA_ "Version" SG_ 2679898132 Meas3Data "0.00.01";
BA_ "UsrSigPurpose" SG_ 2679898132 Meas3Data 2;
BA_ "UserSigValidity" SG_ 2679898133 Meas4Data 3;
BA_ "Description" SG_ 2679898133 Meas4Data "-";
BA_ "Version" SG_ 2679898133 Meas4Data "0.00.01";
BA_ "UsrSigPurpose" SG_ 2679898133 Meas4Data 2;
BA_ "UserSigValidity" SG_ 2679898134 Meas5Data 3;
BA_ "Description" SG_ 2679898134 Meas5Data "-";
BA_ "Version" SG_ 2679898134 Meas5Data "0.00.01";
BA_ "UsrSigPurpose" SG_ 2679898134 Meas5Data 2;
VAL_ 870 F_N_ENG 0 "No error" 1 "Engine speed sensor defective" ;
VAL_ 871 CF_Ems_IsgStat 0 "ISG is not operating Normal engine operating without ISG" 1 "Idle stop is activated Idle is stopped by ECU during driving" 2 "Automatically started by ECU Engine is automatically started by ECU regardless driver’s volition during idle stop because the condition that ISG function to be prohibited is satisfied, for example SOC is too low." 3 "ISG is prohibited Driver prohibits to activate ISG in order to avoid start lag when he met traffic jam for example." 4 "Fault is existing in ISG There is fault, which is related with ISG. So, idle stop is prohibited and engine started automatically if it is idle stop condition. But for the vehicles that use CF_EMS_ISGStat2, the condition for not-activated battery sensor can" 5 "Idle stop is inhibited by system automatically for safety and  convenient condition related with battery SOC, brake vacuum pressure etc. ISG function check for EOL." 6 "Auto start is deactivated system automatically to keep safety, Such as door open, hood open and seat belt unlock." 7 "If driver shift gear N to D range without braking to make auto starting. (Economy ISG Only)" ;
VAL_ 871 CF_Ems_SldAct 0 "Speed limiter function is not active" 1 "Speed limiter function is active" ;
VAL_ 871 G_SEL_DISP 0 "P" 1 "L" 2 "2" 3 "3" 4 "DS Mode" 5 "D" 6 "N" 7 "R" 8 "sports mode / manual shift / paddle shift" 9 "Not Display at Cluster" 10 "Sub-Rom Communication" 11 "Sub-Rom Communication Error" 12 "Paddle shift (D-position)" 13 "Reserved" 14 "Intermediate Position" 15 "fault" ;
VAL_ 1345 CF_Gway_AstDrSw 0 "Close" 1 "Open" ;
VAL_ 1345 CF_Gway_DrvDrSw 0 "Close" 1 "Open" 3 "B-CAN signal Time-out" ;
VAL_ 1345 CF_Gway_DrvSeatBeltSw 0 "Unbelted" 1 "Belted" 3 "B-CAN signal Time-out" ;
VAL_ 1345 CF_Gway_HazardSw 0 "Off" 1 "On" 3 "B-CAN signal Time-out" ;
VAL_ 1345 CF_Gway_HBAControlMode 0 "HLamp High Control Mode by BCM" 1 "HLamp High Control Mode by HBA" ;
VAL_ 1345 CF_Gway_HeadLampHigh 0 "Off" 1 "On" ;
VAL_ 1345 CF_Gway_HeadLampLow 0 "Off" 1 "On" ;
VAL_ 1345 CF_Gway_InhibitRMT 0 "Gear_R Switch Off" 1 "Gear_R Switch On" 3 "B-CAN signal Time-out" ;
VAL_ 1345 CF_Gway_RainSnsState 0 "OFF" 1 "Rain Detected" 2 "Low" 3 "High" 4 "Fault 1" 5 "Fault 2" 6 "Fault 3" 7 "Reserved" ;
VAL_ 1345 CF_Gway_TSigLHSw 0 "Off" 1 "On" ;
VAL_ 1345 CF_Gway_TSigRHSw 0 "Off" 1 "On" ;
VAL_ 1345 CF_Gway_TurnSigLh 0 "Off" 1 "On" 3 "B-CAN Time-out" ;
VAL_ 1345 CF_Gway_TurnSigRh 0 "Off" 1 "On" 3 "B-CAN Time-out" ;
VAL_ 1345 CF_Gway_WiperAutoSw 0 "Off" 1 "On" ;
VAL_ 1345 CF_Gway_WiperHighSw 0 "Off" 1 "On" ;
VAL_ 1345 CF_Gway_WiperIntSw 0 "Off" 1 "On" ;
VAL_ 1345 CF_Gway_WiperIntT 0 "Step1(SLOW)" 1 "Step2" 2 "Step3" 3 "Step4" 4 "Step5(FAST)" ;
VAL_ 1345 CF_Gway_WiperLowSw 0 "Off" 1 "On" ;
VAL_ 1345 CF_Gway_IGNSw 0 "Key Off" 1 "Key In" 2 "ACC" 3 "IGN" 4 "Start" 5 "Reserved" 6 "Reserved" 7 "B-CAN signal Timt-out" ;
VAL_ 1363 CF_Gway_RLDrSw 0 "Close" 1 "Open" ;
VAL_ 1363 CF_Gway_RRDrSw 0 "Close" 1 "Open" ;
VAL_ 1363 CF_Gway_WiperParkPosition 0 "else" 1 "Parking Position" ;
VAL_ 1193 C_SMKTeleEngineRunning 0 "Off" 1 "Tele Running" ;
VAL_ 1265 CF_Clu_CruiseSwMain 0 "Off" 1 "On" ;
VAL_ 1265 CF_Clu_CruiseSwState 0 "Idle Position" 1 "Plus" 2 "Minus" 3 "Time gap (Distance, SCC only)" 4 "Cancel/Pause" 5 "Reserved" 6 "Reserved" 7 "Reserved" ;
VAL_ 1265 CF_Clu_SldMainSW 0 "Off" 1 "On" ;
VAL_ 1265 CF_Clu_SPEED_UNIT 0 "km/h" 1 "MPH" ;
VAL_ 1292 CF_Clu_DAWLastBreakTime 0 "Value x 30min (0~6.5hr)" 1 "Value x 30min (0~6.5hr)" 2 "Value x 30min (0~6.5hr)" 3 "Value x 30min (0~6.5hr)" 4 "Value x 30min (0~6.5hr)" 5 "Value x 30min (0~6.5hr)" 6 "Value x 30min (0~6.5hr)" 7 "Value x 30min (0~6.5hr)" 8 "Value x 30min (0~6.5hr)" 9 "Value x 30min (0~6.5hr)" 10 "Value x 30min (0~6.5hr)" 11 "Value x 30min (0~6.5hr)" 12 "Value x 30min (0~6.5hr)" 13 "Value x 30min (0~6.5hr)" 14 "7hr or more" 15 "Invalid" ;
VAL_ 1292 CF_Clu_DrivinglampStat 0 "Reserved" 1 "Normal" 2 "Eco" 3 "Sport" 4 "Sport+" 5 "Smart" 6 "Individual" 7 "N-mode" ;
VAL_ 1292 CF_Clu_IceWarnIndStat 0 "Off" 1 "On" ;
VAL_ 1307 CF_Clu_TirePressUnitNValueSet 0 "Default Value" 1 "Psi" 2 "Kpa" 3 "Bar" 4 "Reserved" 5 "Reserved" 6 "Reserved" 7 "Invalid" ;
VAL_ 1307 CF_Clu_DAWModeNValueSet 0 "Default" 1 "OFF" 2 "Late" 3 "Normal" 4 "Early" 5 "Reserved" 6 "Reserved" 7 "Invalid" ;
VAL_ 1307 CF_Clu_FCAModeNValueSet 0 "Default" 1 "ON(Late)" 2 "ON(Normal)" 3 "ON(Early)" 4 "Reserved" 5 "Reserved" 6 "Reserved" 7 "Invalid" ;
VAL_ 1307 CF_Clu_HDANValueSet 0 "Default" 1 "Function Off" 2 "Function On" 3 "Invalid(Fail)" ;
VAL_ 1307 CF_Clu_USMReset 0 "Default" 1 "Reset" ;
VAL_ 1307 CF_Gway_WPCNValueSet 0 "Default" 1 "Off(Disable)" 2 "On(Enable)" 3 "Invalid" ;
VAL_ 1307 CF_Clu_MoodLpBrightNValueSet 0 "Default" 1 "Off" 2 "step 1" 3 "step 2" 4 "step 3" 5 "step 4" 6 "Reserved" 7 "Invalid" ;
VAL_ 1190 CF_AVN_CluUSMReset 0 "Defualt" 1 "Reset" ;
VAL_ 1190 CF_AVN_DAWModeNValueSet_New 0 "Default" 1 "Off" 2 "On" 3 "Invalid" ;
VAL_ 1190 CF_AVN_FCANValueSet 0 "Default(NoneFCA)" 1 "Off" 2 "Warning" 3 "Assist" 4 "Reserved" 5 "Reserved" 6 "Reserved" 7 "Invalid" ;
VAL_ 1190 CF_AVN_HBANValueSet 0 "Default(NoneHBA)" 1 "HBA Function Off" 2 "HBA Function On" 3 "Invalid" ;
VAL_ 1190 CF_AVN_HDA_NValueSet 0 "Default" 1 "Function Off" 2 "Function On" 3 "Invalid(Fail)" ;
VAL_ 1190 CF_AVN_LkaModeNValueSet 0 "Default" 1 "LDW mode" 2 "LKA" 3 "Reserved" 4 "LDW only ON (None LKA)" 5 "LDW only OFF (None LKA)" 6 "LDW/LKA OFF" 7 "Invalid" ;
VAL_ 1190 CF_AVN_LVDANValueSet 0 "Default" 1 "Off" 2 "On" 3 "Invalid" ;
VAL_ 1190 CF_AVN_NSCCCamNValueSet 0 "Default" 1 "Disable" 2 "Enable" 3 "Invalid" ;
VAL_ 1190 CF_AVN_WarningTimingNValueSet 0 "Default" 1 "Late" 2 "Normal" 3 "Reserved" 4 "Reserved" 5 "Reserved" 6 "Reserved" 7 "Invliad" ;
VAL_ 1190 CF_Clu_DawResetReq 0 "Default" 1 "ResetReq" ;
VAL_ 913 CF_Clu_LFASwState 0 "Off" 1 "On" ;
VAL_ 1474 CF_Clu_AdasISLAAutoSetReq 0 "Default" 1 "Auto off" 2 "Auto on" 3 "Invalid" ;
VAL_ 1474 CF_Clu_AdasISLASetReq 0 "Default" 1 "Off" 2 "ISLW" 3 "ISLA" 4 "Reserved" 5 "Reserved" 6 "Reserved" 7 "Invalid" ;
VAL_ 1474 CF_Clu_ISLAOffsetSetReq 0 "Default" 1 "-10kph -5mph" 2 "-5kph -3mph" 3 "0" 4 "5kph 3mph" 5 "10kph 5mph" 6 "Reserved" 7 "Invalid" ;
VAL_ 809 ACC_ACT 0 "Auto cruise control is not active" 1 "Auto cruise control is active" ;
VAL_ 809 CONF_TCU 0 "A/T vehicle (Step Shift A/T)" 9 "E-CLUTCH vehicle" 10 "CVT vehicle (CVT A/T)" 11 "DCT vehicle (DCT A/T)" 14 "AMT vehicle" 15 "M/T vehicle" ;
VAL_ 809 MUL_CODE 0 "CAN_VERS" 1 "CONF_TCU" 2 "OBD_FRF_ACK" 3 "TQ_STND" ;
VAL_ 809 PV_AV_CAN 0 "Accelerator Pedal not activated" 254 "Accelerator Pedal fully activated" 255 "Accelerator Pedal is defective (fail state) orNon-ETC system (APS is not installed)" ;
VAL_ 608 CF_Ems_AclAct 0 "Accelerator pedal not pressed" 1 "Accelerator pedal pressed" 2 "Reserved" 3 "Accelerator pedal position sensor failure" ;
VAL_ 608 ENG_STAT 0 "Engine Stop" 1 "Cranking" 2 "Stalled" 3 "Running" 4 "Auto Stopping" 5 "Reserved" 6 "Reserved" 7 "Fault" ;
VAL_ 544 CYL_PRES_STAT 0 "Master cylinder pressure signal is valid" 1 "Master cylinder pressure signal is invalid" ;
VAL_ 544 CYL_PRESS_DIAG 0 "Master cylinder pressure signal is available" 1 "Master cylinder pressure is not available temporarily" ;
VAL_ 544 LAT_ACCEL_DIAG 0 "Lateral acceleration signal is available" 1 "Lateral acceleration signal is not available temporarily" ;
VAL_ 544 LAT_ACCEL_STAT 0 "Lateral acceleration signal is valid" 1 "Lateral acceleration signal is invalid" ;
VAL_ 544 LONG_ACCEL_DIAG 0 "Longitudinal acceleration signal is available" 1 "Longitudinal acceleration signal is not available temporarily" ;
VAL_ 544 LONG_ACCEL_STAT 0 "Longitudinal acceleration signal is valid" 1 "Longitudinal acceleration signal is invalid" ;
VAL_ 544 YAW_RATE_DIAG 0 "Yaw rate signal is available" 1 "Yaw rate signal is not available temporarily" ;
VAL_ 544 YAW_RATE_STAT 0 "Yaw rate sensor signal is valid" 1 "Yaw rate sensor signal is invalid" ;
VAL_ 909 CF_VSM_BeltCmd 0 "Release " 1 "Pre-crash full retraction" 2 "Haptic warning" ;
VAL_ 909 CF_VSM_DecCmdAct 0 "No request" 1 "Request valid" ;
VAL_ 909 CF_VSM_HBACmd 0 "Standard threshold" 1 "Lowered threshold 1" 2 "Lowered threshold 2" 3 "Lowered threshold 3" ;
VAL_ 909 CF_VSM_Prefill 0 "No pre-fill" 1 "Pre-fill" ;
VAL_ 909 CF_VSM_Warn 0 "No warning" 1 "Warning level 1" 2 "Warning level 2" 3 "Warning level 3" ;
VAL_ 909 CR_FCA_Alive 15 "Signal Invalid" ;
VAL_ 909 FCA_CmdAct 0 "No request" 1 "Request valid" ;
VAL_ 909 FCA_DrvSetStatus 0 "Late" 1 "Normal" 2 "Early" 3 "Reserved" 4 "Reserved" 5 "Reserved" 6 "Not Applied" 7 "Invalid" ;
VAL_ 909 FCA_Failinfo 0 "Normal" 1 "Temp. Unavailable by Camera" 2 "Temp. Unavailable by Radar" 3 "Service Required" 4 "Temp. Unavailable by Camera (Camera only)" 5 "Reserved" 6 "Reserved" 7 "Reserved" ;
VAL_ 909 FCA_RelativeVelocity 511 "Signal Invalid" ;
VAL_ 909 FCA_Sensor_Type 0 "Not sensor fusion" 1 "Sensor fusion" ;
VAL_ 909 FCA_Status 0 "Not Applied" 1 "System Off" 2 "System On" 3 "Invaild (Fail)" ;
VAL_ 909 FCA_StopReq 0 "No request" 1 "Stop control is required" ;
VAL_ 909 FCA_WrngSndSta 0 "No warning" 1 "Warning 1" 2 "Warning 2" 3 "Warning 3" ;
VAL_ 1155 FCA_DrvSetState 0 "Default" 1 "Late" 2 "Normal" 3 "Early" 4 "Reserved" 5 "Reserved" 6 "Reserved" 7 "Invalid" ;
VAL_ 1155 FCA_USM 0 "Default" 1 "Off" 2 "Warning" 3 "Assist" 4 "Reserved" 5 "Reserved" 6 "Reserved" 7 "Invalid" ;
VAL_ 1155 FCA_WarningTargetDisplay 0 "None" 1 "FCA" 2 "Reserved" 3 "Reserved" 4 "Reserved" 5 "Reserved" 6 "Reserved" 7 "FCA-JC(L)" 8 "FCA-JC(R)" 9 "Reserved" 10 "Reserved" 11 "FCA-JT(L)" 12 "FCA-JT(R)" 13 "Reserved" 14 "Reserved" ;
VAL_ 1157 CF_HDA_InfoDisplay 0 "no pop-up" 1 "system start pop-up" 2 "system auto disengaged pop-up by highway off" 3 "system Fail pop-up(LFA)" 4 "system Fail pop-up(HDA)" 5 "Hands-off pop up" 6 "Hands-off pop up w/ sound" 7 "System Automatic off" ;
VAL_ 1157 CF_HDA_InfoDisplay2 0 "no pop-up" 1 "System Automatic off (LFA)" 2 "System Automatic off (HDA)" 3 "System Automatic off (SCC, LFA)" 4 "OK Pop-up to Activate HDA" ;
VAL_ 1157 CF_HDA_LFA_SymbolState 0 "Off" 1 "White" 2 "Green" 3 "Green blink" ;
VAL_ 1157 CF_HDA_LFA_Wrn_Snd 0 "Off" 1 "Additional Warning Sound" ;
VAL_ 1157 CF_HDA_Mode 0 "OFF" 1 "Ready" 2 "Active" 3 "Reserved" ;
VAL_ 1157 CF_HDA_Opt_USM 0 "Not Applied" 1 "Function Off" 2 "Function On" 3 "Invalid (Fail)" ;
VAL_ 1470 HU_NaviCamSettingStatus 0 "Navi Camera Alert Setting Status" 1 "Navi Camera Alert Setting Status" 2 "Navi Camera Alert Setting Status" 3 "Navi Camera Alert Setting Status" 4 "Navi Camera Alert Setting Status" 5 "Navi Camera Alert Setting Status" 6 "Navi Camera Alert Setting Status" 7 "Navi Camera Alert Setting Status" 8 "Navi Camera Alert Setting Status" 9 "Navi Camera Alert Setting Status" 10 "Navi Camera Alert Setting Status" 11 "Navi Camera Alert Setting Status" 12 "Navi Camera Alert Setting Status" 13 "Navi Camera Alert Setting Status" 14 "Navi Camera Alert Setting Status" 15 "Navi Camera Alert Setting Status" 16 "Navi Camera Alert Setting Status" 17 "Navi Camera Alert Setting Status" 18 "Navi Camera Alert Setting Status" 19 "Navi Camera Alert Setting Status" 20 "Navi Camera Alert Setting Status" 21 "Navi Camera Alert Setting Status" 22 "Navi Camera Alert Setting Status" 23 "Navi Camera Alert Setting Status" 24 "Navi Camera Alert Setting Status" 25 "Navi Camera Alert Setting Status" 26 "Navi Camera Alert Setting Status" 27 "Navi Camera Alert Setting Status" 28 "Navi Camera Alert Setting Status" 29 "Navi Camera Alert Setting Status" 30 "Navi Camera Alert Setting Status" 31 "Navi Camera Alert Setting Status" 32 "Reserved" 33 "Reserved" 34 "Reserved" 35 "Reserved" 36 "Reserved" 37 "Reserved" 38 "Reserved" 39 "Reserved" 40 "Reserved" 41 "Reserved" 42 "Reserved" 43 "Reserved" 44 "Reserved" 45 "Reserved" 46 "Reserved" 47 "Reserved" 48 "Reserved" 49 "Reserved" 50 "Reserved" 51 "Reserved" 52 "Reserved" 53 "Reserved" 54 "Reserved" 55 "Reserved" 56 "Reserved" 57 "Reserved" 58 "Reserved" 59 "Reserved" 60 "Reserved" 61 "Reserved" 62 "Reserved" 63 "Reserved" 64 "Reserved" 65 "Reserved" 66 "Reserved" 67 "Reserved" 68 "Reserved" 69 "Reserved" 70 "Reserved" 71 "Reserved" 72 "Reserved" 73 "Reserved" 74 "Reserved" 75 "Reserved" 76 "Reserved" 77 "Reserved" 78 "Reserved" 79 "Reserved" 80 "Reserved" 81 "Reserved" 82 "Reserved" 83 "Reserved" 84 "Reserved" 85 "Reserved" 86 "Reserved" 87 "Reserved" 88 "Reserved" 89 "Reserved" 90 "Reserved" 91 "Reserved" 92 "Reserved" 93 "Reserved" 94 "Reserved" 95 "Reserved" 96 "Reserved" 97 "Reserved" 98 "Reserved" 99 "Reserved" 100 "Reserved" 101 "Reserved" 102 "Reserved" 103 "Reserved" 104 "Reserved" 105 "Reserved" 106 "Reserved" 107 "Reserved" 108 "Reserved" 109 "Reserved" 110 "Reserved" 111 "Reserved" 112 "Reserved" 113 "Reserved" 114 "Reserved" 115 "Reserved" 116 "Reserved" 117 "Reserved" 118 "Reserved" 119 "Reserved" 120 "Reserved" 121 "Reserved" 122 "Reserved" 123 "Reserved" 124 "Reserved" 125 "Reserved" 126 "Reserved" 127 "Reserved" 128 "Reserved" 129 "Reserved" 130 "Reserved" 131 "Reserved" 132 "Reserved" 133 "Reserved" 134 "Reserved" 135 "Reserved" 136 "Reserved" 137 "Reserved" 138 "Reserved" 139 "Reserved" 140 "Reserved" 141 "Reserved" 142 "Reserved" 143 "Reserved" 144 "Reserved" 145 "Reserved" 146 "Reserved" 147 "Reserved" 148 "Reserved" 149 "Reserved" 150 "Reserved" 151 "Reserved" 152 "Reserved" 153 "Reserved" 154 "Reserved" 155 "Reserved" 156 "Reserved" 157 "Reserved" 158 "Reserved" 159 "Reserved" 160 "Reserved" 161 "Reserved" 162 "Reserved" 163 "Reserved" 164 "Reserved" 165 "Reserved" 166 "Reserved" 167 "Reserved" 168 "Reserved" 169 "Reserved" 170 "Reserved" 171 "Reserved" 172 "Reserved" 173 "Reserved" 174 "Reserved" 175 "Reserved" 176 "Reserved" 177 "Reserved" 178 "Reserved" 179 "Reserved" 180 "Reserved" 181 "Reserved" 182 "Reserved" 183 "Reserved" 184 "Reserved" 185 "Reserved" 186 "Reserved" 187 "Reserved" 188 "Reserved" 189 "Reserved" 190 "Reserved" 191 "Reserved" 192 "Reserved" 193 "Reserved" 194 "Reserved" 195 "Reserved" 196 "Reserved" 197 "Reserved" 198 "Reserved" 199 "Reserved" 200 "Reserved" 201 "Reserved" 202 "Reserved" 203 "Reserved" 204 "Reserved" 205 "Reserved" 206 "Reserved" 207 "Reserved" 208 "Reserved" 209 "Reserved" 210 "Reserved" 211 "Reserved" 212 "Reserved" 213 "Reserved" 214 "Reserved" 215 "Reserved" 216 "Reserved" 217 "Reserved" 218 "Reserved" 219 "Reserved" 220 "Reserved" 221 "Reserved" 222 "Reserved" 223 "Reserved" 224 "Reserved" 225 "Reserved" 226 "Reserved" 227 "Reserved" 228 "Reserved" 229 "Reserved" 230 "Reserved" 231 "Reserved" 232 "Reserved" 233 "Reserved" 234 "Reserved" 235 "Reserved" 236 "Reserved" 237 "Reserved" 238 "Reserved" 239 "Reserved" 240 "Reserved" 241 "Reserved" 242 "Reserved" 243 "Reserved" 244 "Reserved" 245 "Reserved" 246 "Reserved" 247 "Reserved" 248 "Reserved" 249 "Reserved" 250 "Reserved" 251 "Reserved" 252 "Reserved" 253 "Reserved" 254 "Reserved" 255 "Invalid" ;
VAL_ 1470 HU_NaviStatus 0 "Booting" 1 "Normal Operation" 2 "No SD Card(Map)" 3 "Invalid" ;
VAL_ 1407 HU_AdasSupport 0 "Not Support" 1 "ADAS Support(General Map)" 2 "ADAS Support(Precise Map)" 3 "Reserved" 4 "Reserved" 5 "Reserved" 6 "Reserved" 7 "Invalid" ;
VAL_ 1407 HU_DistributeInfo 255 "Invalid" 1 "KOREA" 2 "NORTH AMERICA" 3 "CANADA" 4 "EAST EUROPE" 5 "WEST EUROPE" 6 "CHINA" 7 "INDIA" 8 "AUSTRALIA" 9 "MIDDLE EAST" 10 "AFRICA" 11 "SOUTH AMERICA" 12 "RESERVED" 13 "RESERVED" 14 "GENERAL" 15 "RESERVED" ;
VAL_ 1407 HU_Type 16 "AVN(Tuner DVD KOR)" 17 "AVN(Tuner DVD EUR)" 18 "AVN(Tuner DVD China)" 19 "AVN(Tuner DVD Japan)" 20 "AVN(Tuner DVD EUR)" 21 "AVN(Tuner CDP KOR)" 22 "AVN(Tuner CDP EUR)" 23 "AVN(Tuner CDP China)" 24 "AVN(Tuner CDP Japan)" 25 "AVN(Tuner CDP EUR)" 32 "AVNT (Open)" 33 "AVNT (Not open)" 48 "Economic Audio" 64 "Standard Audio (3.0 below)" 65 "Standard Audio 4.0" 66 "STD Audio-3.0Below,No interwork" 67 "Audio 4.0 Value" 80 "AV(Tuner DVD KOR)" 81 "AV(Tuner DVD EUR)" 82 "AV(Tuner DVD China)" 83 "AV(Tuner DVD Japan)" 84 "AV(Tuner DVD EUR)" 85 "AV(Tuner CDP KOR)" 86 "AV(Tuner CDP EUR)" 87 "AV(Tuner CDP China)" 88 "AV(Tuner CDP Japan)" 89 "AV(Tuner CDP EUR)" 96 "AVN 4.0" 97 "Premium AVN2.0" 98 "EU AVN 2.0" 99 "Super Premium w Navi" 100 "Super Premium w_o Navi" 101 "Premium w Navi" 102 "Premium w_o Navi" 103 "Display Audio w_o Navi" 104 "Integrated AVN 1.0 Mobis" 105 "Gen5 Standard Nav Wide" 112 "Compact AVN & Integrated AVN 1.0 LG" 128 "Premium Navi 5th Gen(w/Navi)" 129 "Premium Navi 5th Gen(w/o Navi)" 130 "Premium Navi 6th Gen(w/ Navi)" 131 "Premium Navi 6th Gen(w/o Navi)" 238 "India PIO w_o CLU interface" 239 "India PIO w_CLU interface" 250 "PIO AVN" 251 "China only OEM AV" 252 "China OPIO w_o CLU interface" 253 "China OPIO w_CLU interface" 254 "China OEM AVNT" 255 "Invalid" ;
VAL_ 832 CF_HBA_Lamp 0 "HBA Indicator Lamp Off" 1 "HBA Indicator Lamp On" ;
VAL_ 832 CF_HBA_Opt 0 "None HBA Option (Default)" 1 "HBA System Enable" ;
VAL_ 832 CF_HBA_Opt_USM 0 "None HBA Option (Default)" 1 "HBA Function Off" 2 "HBA Function On" 3 "Invalid (Fail)" ;
VAL_ 832 CF_HBA_SysState 0 "Default (Disable)" 1 "HBA Enable & High Beam Off" 2 "HBA Enable & High Beam On" 7 "System Fail" ;
VAL_ 832 CF_LKA_ActToi 0 "De-activate TOI" 1 "Activate TOI" ;
VAL_ 832 CF_LKA_FusionState 0 "Normal" 1 "Fusion Disabled" 2 "SCC Communication Error" 3 "Camera Blockage" ;
VAL_ 832 CF_LKA_HandsOff_Snd 0 "Off" 1 "Hands-off Sound Warning" ;
VAL_ 832 CF_LKA_LaneRecogState 0 "Not Recognition" 1 "Left Lane Recognition" 2 "Right Lane Recognition" 3 "Full Lane Recognition" ;
VAL_ 832 CF_LKA_LHWarning 0 "No Warning" 1 "HAPTIC Warning and Acoustic Warning and Display" 2 "Acoustic Warning and Display" ;
VAL_ 832 CF_LKA_Opt_USM 0 "None LKA/LDW Option" 1 "LDW" 2 "LKA" 3 "ACTIVE LKA" 4 "LDW Only (None LKA)" 5 "LDW only OFF (None LKA)" 6 "LDW/LKA OFF" 7 "Invalid" ;
VAL_ 832 CF_LKA_RHWarning 0 "No Warning" 1 "HAPTIC Warning and Acoustic Warning and Display" 2 "Acoustic Warning and Display" ;
VAL_ 832 CF_LKA_SymbolState 0 "Off" 1 "White On" 2 "Green On" 3 "Green Blink" 4 "Orange On" 5 "Orange Blink" 6 "Orange ON (Regulation)" 7 "White Blink" ;
VAL_ 832 CF_LKA_SysState 0 "System OFF" 1 "Low Vehicle Speed" 2 "System Unavailable" 3 "MDPS Control_Full Lane Recognized" 4 "Full Lane Recognized" 5 "Left Line Recognized" 6 "Right Line Recognized" 7 "MDPS Control_Left Line Recognized" 8 "MDPS Control_Right Line Recognized" 14 "System Not Calibrated" 15 "System Failure" ;
VAL_ 832 CF_LKA_SysWarning 0 "No Info" 4 "Hands-Off Warning1" 5 "Hands-Off Warning2" 6 "Hands-Off Warning3" 9 "System Automatic off" 15 "System Fail" ;
VAL_ 832 CF_LKA_ToiFlt 0 "No Fault" 1 "Fault Present" ;
VAL_ 832 CF_LKA_USM_Mode 0 "NONE" 1 "LKA 1 Mode" 2 "LKA 2 Mode" 3 "LDW" ;
VAL_ 1342 CF_DAW_Opt_USM_NEW 0 "None DAW Option(Default)" 1 "System OFF" 2 "System ON" 3 "Invalid" ;
VAL_ 1342 CF_DAW_Status 0 "System OFF" 1 "Attention Level  1" 2 "Attention Level  2" 3 "Attention Level  3" 4 "Attention Level  4" 5 "Attention Level  5" 6 "Reserved" 7 "Reserved" 8 "Reserved" 9 "Reserved" 10 "Reserved" 11 "Reserved" 12 "Reserved" 13 "Reserved" 14 "System Standby" 15 "System Fail" ;
VAL_ 1342 CF_DAW_TimeReset 0 "No Signal" 1 "Time Reset" ;
VAL_ 1342 CF_DAW_Warn 0 "No Warning" 1 "Rest Recommend Warning" 2 "Hands-Off TMS Call Request" 3 "Reserved" ;
VAL_ 1342 CF_ISLW_Addinfo_Display 0 "None Display (Default)" 1 "LHD No Passing Zone Display" 2 "RHD No Passing Zone Display" 3 "Invalid" ;
VAL_ 1342 CF_ISLW_OvrlapSign_Dis 0 "None (Default)" 1 "Overlap Sign" 2 "Reserved" 3 "Reserved" ;
VAL_ 1342 CF_ISLW_Spd_Dis_CLU_Main 0 "No Recognition (Default)" 1 "1~252" 2 "1~252" 3 "1~252" 4 "1~252" 5 "1~252" 6 "1~252" 7 "1~252" 8 "1~252" 9 "1~252" 10 "1~252" 11 "1~252" 12 "1~252" 13 "1~252" 14 "1~252" 15 "1~252" 16 "1~252" 17 "1~252" 18 "1~252" 19 "1~252" 20 "1~252" 21 "1~252" 22 "1~252" 23 "1~252" 24 "1~252" 25 "1~252" 26 "1~252" 27 "1~252" 28 "1~252" 29 "1~252" 30 "1~252" 31 "1~252" 32 "1~252" 33 "1~252" 34 "1~252" 35 "1~252" 36 "1~252" 37 "1~252" 38 "1~252" 39 "1~252" 40 "1~252" 41 "1~252" 42 "1~252" 43 "1~252" 44 "1~252" 45 "1~252" 46 "1~252" 47 "1~252" 48 "1~252" 49 "1~252" 50 "1~252" 51 "1~252" 52 "1~252" 53 "1~252" 54 "1~252" 55 "1~252" 56 "1~252" 57 "1~252" 58 "1~252" 59 "1~252" 60 "1~252" 61 "1~252" 62 "1~252" 63 "1~252" 64 "1~252" 65 "1~252" 66 "1~252" 67 "1~252" 68 "1~252" 69 "1~252" 70 "1~252" 71 "1~252" 72 "1~252" 73 "1~252" 74 "1~252" 75 "1~252" 76 "1~252" 77 "1~252" 78 "1~252" 79 "1~252" 80 "1~252" 81 "1~252" 82 "1~252" 83 "1~252" 84 "1~252" 85 "1~252" 86 "1~252" 87 "1~252" 88 "1~252" 89 "1~252" 90 "1~252" 91 "1~252" 92 "1~252" 93 "1~252" 94 "1~252" 95 "1~252" 96 "1~252" 97 "1~252" 98 "1~252" 99 "1~252" 100 "1~252" 101 "1~252" 102 "1~252" 103 "1~252" 104 "1~252" 105 "1~252" 106 "1~252" 107 "1~252" 108 "1~252" 109 "1~252" 110 "1~252" 111 "1~252" 112 "1~252" 113 "1~252" 114 "1~252" 115 "1~252" 116 "1~252" 117 "1~252" 118 "1~252" 119 "1~252" 120 "1~252" 121 "1~252" 122 "1~252" 123 "1~252" 124 "1~252" 125 "1~252" 126 "1~252" 127 "1~252" 128 "1~252" 129 "1~252" 130 "1~252" 131 "1~252" 132 "1~252" 133 "1~252" 134 "1~252" 135 "1~252" 136 "1~252" 137 "1~252" 138 "1~252" 139 "1~252" 140 "1~252" 141 "1~252" 142 "1~252" 143 "1~252" 144 "1~252" 145 "1~252" 146 "1~252" 147 "1~252" 148 "1~252" 149 "1~252" 150 "1~252" 151 "1~252" 152 "1~252" 153 "1~252" 154 "1~252" 155 "1~252" 156 "1~252" 157 "1~252" 158 "1~252" 159 "1~252" 160 "1~252" 161 "1~252" 162 "1~252" 163 "1~252" 164 "1~252" 165 "1~252" 166 "1~252" 167 "1~252" 168 "1~252" 169 "1~252" 170 "1~252" 171 "1~252" 172 "1~252" 173 "1~252" 174 "1~252" 175 "1~252" 176 "1~252" 177 "1~252" 178 "1~252" 179 "1~252" 180 "1~252" 181 "1~252" 182 "1~252" 183 "1~252" 184 "1~252" 185 "1~252" 186 "1~252" 187 "1~252" 188 "1~252" 189 "1~252" 190 "1~252" 191 "1~252" 192 "1~252" 193 "1~252" 194 "1~252" 195 "1~252" 196 "1~252" 197 "1~252" 198 "1~252" 199 "1~252" 200 "1~252" 201 "1~252" 202 "1~252" 203 "1~252" 204 "1~252" 205 "1~252" 206 "1~252" 207 "1~252" 208 "1~252" 209 "1~252" 210 "1~252" 211 "1~252" 212 "1~252" 213 "1~252" 214 "1~252" 215 "1~252" 216 "1~252" 217 "1~252" 218 "1~252" 219 "1~252" 220 "1~252" 221 "1~252" 222 "1~252" 223 "1~252" 224 "1~252" 225 "1~252" 226 "1~252" 227 "1~252" 228 "1~252" 229 "1~252" 230 "1~252" 231 "1~252" 232 "1~252" 233 "1~252" 234 "1~252" 235 "1~252" 236 "1~252" 237 "1~252" 238 "1~252" 239 "1~252" 240 "1~252" 241 "1~252" 242 "1~252" 243 "1~252" 244 "1~252" 245 "1~252" 246 "1~252" 247 "1~252" 248 "1~252" 249 "1~252" 250 "1~252" 251 "1~252" 252 "1~252" 253 "Unlimited Speed" 254 "Reserved" 255 "Invalid" ;
VAL_ 1342 CF_ISLW_Spd_Dis_NAVI_Main 0 "No Recognition (Default)" 1 "1~252" 2 "1~252" 3 "1~252" 4 "1~252" 5 "1~252" 6 "1~252" 7 "1~252" 8 "1~252" 9 "1~252" 10 "1~252" 11 "1~252" 12 "1~252" 13 "1~252" 14 "1~252" 15 "1~252" 16 "1~252" 17 "1~252" 18 "1~252" 19 "1~252" 20 "1~252" 21 "1~252" 22 "1~252" 23 "1~252" 24 "1~252" 25 "1~252" 26 "1~252" 27 "1~252" 28 "1~252" 29 "1~252" 30 "1~252" 31 "1~252" 32 "1~252" 33 "1~252" 34 "1~252" 35 "1~252" 36 "1~252" 37 "1~252" 38 "1~252" 39 "1~252" 40 "1~252" 41 "1~252" 42 "1~252" 43 "1~252" 44 "1~252" 45 "1~252" 46 "1~252" 47 "1~252" 48 "1~252" 49 "1~252" 50 "1~252" 51 "1~252" 52 "1~252" 53 "1~252" 54 "1~252" 55 "1~252" 56 "1~252" 57 "1~252" 58 "1~252" 59 "1~252" 60 "1~252" 61 "1~252" 62 "1~252" 63 "1~252" 64 "1~252" 65 "1~252" 66 "1~252" 67 "1~252" 68 "1~252" 69 "1~252" 70 "1~252" 71 "1~252" 72 "1~252" 73 "1~252" 74 "1~252" 75 "1~252" 76 "1~252" 77 "1~252" 78 "1~252" 79 "1~252" 80 "1~252" 81 "1~252" 82 "1~252" 83 "1~252" 84 "1~252" 85 "1~252" 86 "1~252" 87 "1~252" 88 "1~252" 89 "1~252" 90 "1~252" 91 "1~252" 92 "1~252" 93 "1~252" 94 "1~252" 95 "1~252" 96 "1~252" 97 "1~252" 98 "1~252" 99 "1~252" 100 "1~252" 101 "1~252" 102 "1~252" 103 "1~252" 104 "1~252" 105 "1~252" 106 "1~252" 107 "1~252" 108 "1~252" 109 "1~252" 110 "1~252" 111 "1~252" 112 "1~252" 113 "1~252" 114 "1~252" 115 "1~252" 116 "1~252" 117 "1~252" 118 "1~252" 119 "1~252" 120 "1~252" 121 "1~252" 122 "1~252" 123 "1~252" 124 "1~252" 125 "1~252" 126 "1~252" 127 "1~252" 128 "1~252" 129 "1~252" 130 "1~252" 131 "1~252" 132 "1~252" 133 "1~252" 134 "1~252" 135 "1~252" 136 "1~252" 137 "1~252" 138 "1~252" 139 "1~252" 140 "1~252" 141 "1~252" 142 "1~252" 143 "1~252" 144 "1~252" 145 "1~252" 146 "1~252" 147 "1~252" 148 "1~252" 149 "1~252" 150 "1~252" 151 "1~252" 152 "1~252" 153 "1~252" 154 "1~252" 155 "1~252" 156 "1~252" 157 "1~252" 158 "1~252" 159 "1~252" 160 "1~252" 161 "1~252" 162 "1~252" 163 "1~252" 164 "1~252" 165 "1~252" 166 "1~252" 167 "1~252" 168 "1~252" 169 "1~252" 170 "1~252" 171 "1~252" 172 "1~252" 173 "1~252" 174 "1~252" 175 "1~252" 176 "1~252" 177 "1~252" 178 "1~252" 179 "1~252" 180 "1~252" 181 "1~252" 182 "1~252" 183 "1~252" 184 "1~252" 185 "1~252" 186 "1~252" 187 "1~252" 188 "1~252" 189 "1~252" 190 "1~252" 191 "1~252" 192 "1~252" 193 "1~252" 194 "1~252" 195 "1~252" 196 "1~252" 197 "1~252" 198 "1~252" 199 "1~252" 200 "1~252" 201 "1~252" 202 "1~252" 203 "1~252" 204 "1~252" 205 "1~252" 206 "1~252" 207 "1~252" 208 "1~252" 209 "1~252" 210 "1~252" 211 "1~252" 212 "1~252" 213 "1~252" 214 "1~252" 215 "1~252" 216 "1~252" 217 "1~252" 218 "1~252" 219 "1~252" 220 "1~252" 221 "1~252" 222 "1~252" 223 "1~252" 224 "1~252" 225 "1~252" 226 "1~252" 227 "1~252" 228 "1~252" 229 "1~252" 230 "1~252" 231 "1~252" 232 "1~252" 233 "1~252" 234 "1~252" 235 "1~252" 236 "1~252" 237 "1~252" 238 "1~252" 239 "1~252" 240 "1~252" 241 "1~252" 242 "1~252" 243 "1~252" 244 "1~252" 245 "1~252" 246 "1~252" 247 "1~252" 248 "1~252" 249 "1~252" 250 "1~252" 251 "1~252" 252 "1~252" 253 "Unlimited Speed" 254 "Reserved" 255 "Invalid" ;
VAL_ 1342 CF_ISLW_Status 0 "ISLW Valid (default)" 1 "ISLW Invalid/Failure" 2 "ISLW Temporary Unavailable" ;
VAL_ 1342 CF_LeadVehDptAlert_Display 0 "Default" 1 "Display “Lead Vehicle Departure Alert”" 2 "Reserved" 3 "Invalid" ;
VAL_ 1342 CF_LeadVehDptAlert_USM 0 "No Option (default)" 1 "Off" 2 "On" 3 "Invalid" ;
VAL_ 1342 ISLA_IcyWrn 0 "No Warning" 1 "Warning" ;
VAL_ 1342 ISLA_SpdChgReq 0 "Default" 1 "Speed Change Request" 2 "Reserved" 3 "Reserved" ;
VAL_ 1342 ISLA_SpdwOffst 0 "No recognition" 1 "1~252 kph or mph" 2 "1~252 kph or mph" 3 "1~252 kph or mph" 4 "1~252 kph or mph" 5 "1~252 kph or mph" 6 "1~252 kph or mph" 7 "1~252 kph or mph" 8 "1~252 kph or mph" 9 "1~252 kph or mph" 10 "1~252 kph or mph" 11 "1~252 kph or mph" 12 "1~252 kph or mph" 13 "1~252 kph or mph" 14 "1~252 kph or mph" 15 "1~252 kph or mph" 16 "1~252 kph or mph" 17 "1~252 kph or mph" 18 "1~252 kph or mph" 19 "1~252 kph or mph" 20 "1~252 kph or mph" 21 "1~252 kph or mph" 22 "1~252 kph or mph" 23 "1~252 kph or mph" 24 "1~252 kph or mph" 25 "1~252 kph or mph" 26 "1~252 kph or mph" 27 "1~252 kph or mph" 28 "1~252 kph or mph" 29 "1~252 kph or mph" 30 "1~252 kph or mph" 31 "1~252 kph or mph" 32 "1~252 kph or mph" 33 "1~252 kph or mph" 34 "1~252 kph or mph" 35 "1~252 kph or mph" 36 "1~252 kph or mph" 37 "1~252 kph or mph" 38 "1~252 kph or mph" 39 "1~252 kph or mph" 40 "1~252 kph or mph" 41 "1~252 kph or mph" 42 "1~252 kph or mph" 43 "1~252 kph or mph" 44 "1~252 kph or mph" 45 "1~252 kph or mph" 46 "1~252 kph or mph" 47 "1~252 kph or mph" 48 "1~252 kph or mph" 49 "1~252 kph or mph" 50 "1~252 kph or mph" 51 "1~252 kph or mph" 52 "1~252 kph or mph" 53 "1~252 kph or mph" 54 "1~252 kph or mph" 55 "1~252 kph or mph" 56 "1~252 kph or mph" 57 "1~252 kph or mph" 58 "1~252 kph or mph" 59 "1~252 kph or mph" 60 "1~252 kph or mph" 61 "1~252 kph or mph" 62 "1~252 kph or mph" 63 "1~252 kph or mph" 64 "1~252 kph or mph" 65 "1~252 kph or mph" 66 "1~252 kph or mph" 67 "1~252 kph or mph" 68 "1~252 kph or mph" 69 "1~252 kph or mph" 70 "1~252 kph or mph" 71 "1~252 kph or mph" 72 "1~252 kph or mph" 73 "1~252 kph or mph" 74 "1~252 kph or mph" 75 "1~252 kph or mph" 76 "1~252 kph or mph" 77 "1~252 kph or mph" 78 "1~252 kph or mph" 79 "1~252 kph or mph" 80 "1~252 kph or mph" 81 "1~252 kph or mph" 82 "1~252 kph or mph" 83 "1~252 kph or mph" 84 "1~252 kph or mph" 85 "1~252 kph or mph" 86 "1~252 kph or mph" 87 "1~252 kph or mph" 88 "1~252 kph or mph" 89 "1~252 kph or mph" 90 "1~252 kph or mph" 91 "1~252 kph or mph" 92 "1~252 kph or mph" 93 "1~252 kph or mph" 94 "1~252 kph or mph" 95 "1~252 kph or mph" 96 "1~252 kph or mph" 97 "1~252 kph or mph" 98 "1~252 kph or mph" 99 "1~252 kph or mph" 100 "1~252 kph or mph" 101 "1~252 kph or mph" 102 "1~252 kph or mph" 103 "1~252 kph or mph" 104 "1~252 kph or mph" 105 "1~252 kph or mph" 106 "1~252 kph or mph" 107 "1~252 kph or mph" 108 "1~252 kph or mph" 109 "1~252 kph or mph" 110 "1~252 kph or mph" 111 "1~252 kph or mph" 112 "1~252 kph or mph" 113 "1~252 kph or mph" 114 "1~252 kph or mph" 115 "1~252 kph or mph" 116 "1~252 kph or mph" 117 "1~252 kph or mph" 118 "1~252 kph or mph" 119 "1~252 kph or mph" 120 "1~252 kph or mph" 121 "1~252 kph or mph" 122 "1~252 kph or mph" 123 "1~252 kph or mph" 124 "1~252 kph or mph" 125 "1~252 kph or mph" 126 "1~252 kph or mph" 127 "1~252 kph or mph" 128 "1~252 kph or mph" 129 "1~252 kph or mph" 130 "1~252 kph or mph" 131 "1~252 kph or mph" 132 "1~252 kph or mph" 133 "1~252 kph or mph" 134 "1~252 kph or mph" 135 "1~252 kph or mph" 136 "1~252 kph or mph" 137 "1~252 kph or mph" 138 "1~252 kph or mph" 139 "1~252 kph or mph" 140 "1~252 kph or mph" 141 "1~252 kph or mph" 142 "1~252 kph or mph" 143 "1~252 kph or mph" 144 "1~252 kph or mph" 145 "1~252 kph or mph" 146 "1~252 kph or mph" 147 "1~252 kph or mph" 148 "1~252 kph or mph" 149 "1~252 kph or mph" 150 "1~252 kph or mph" 151 "1~252 kph or mph" 152 "1~252 kph or mph" 153 "1~252 kph or mph" 154 "1~252 kph or mph" 155 "1~252 kph or mph" 156 "1~252 kph or mph" 157 "1~252 kph or mph" 158 "1~252 kph or mph" 159 "1~252 kph or mph" 160 "1~252 kph or mph" 161 "1~252 kph or mph" 162 "1~252 kph or mph" 163 "1~252 kph or mph" 164 "1~252 kph or mph" 165 "1~252 kph or mph" 166 "1~252 kph or mph" 167 "1~252 kph or mph" 168 "1~252 kph or mph" 169 "1~252 kph or mph" 170 "1~252 kph or mph" 171 "1~252 kph or mph" 172 "1~252 kph or mph" 173 "1~252 kph or mph" 174 "1~252 kph or mph" 175 "1~252 kph or mph" 176 "1~252 kph or mph" 177 "1~252 kph or mph" 178 "1~252 kph or mph" 179 "1~252 kph or mph" 180 "1~252 kph or mph" 181 "1~252 kph or mph" 182 "1~252 kph or mph" 183 "1~252 kph or mph" 184 "1~252 kph or mph" 185 "1~252 kph or mph" 186 "1~252 kph or mph" 187 "1~252 kph or mph" 188 "1~252 kph or mph" 189 "1~252 kph or mph" 190 "1~252 kph or mph" 191 "1~252 kph or mph" 192 "1~252 kph or mph" 193 "1~252 kph or mph" 194 "1~252 kph or mph" 195 "1~252 kph or mph" 196 "1~252 kph or mph" 197 "1~252 kph or mph" 198 "1~252 kph or mph" 199 "1~252 kph or mph" 200 "1~252 kph or mph" 201 "1~252 kph or mph" 202 "1~252 kph or mph" 203 "1~252 kph or mph" 204 "1~252 kph or mph" 205 "1~252 kph or mph" 206 "1~252 kph or mph" 207 "1~252 kph or mph" 208 "1~252 kph or mph" 209 "1~252 kph or mph" 210 "1~252 kph or mph" 211 "1~252 kph or mph" 212 "1~252 kph or mph" 213 "1~252 kph or mph" 214 "1~252 kph or mph" 215 "1~252 kph or mph" 216 "1~252 kph or mph" 217 "1~252 kph or mph" 218 "1~252 kph or mph" 219 "1~252 kph or mph" 220 "1~252 kph or mph" 221 "1~252 kph or mph" 222 "1~252 kph or mph" 223 "1~252 kph or mph" 224 "1~252 kph or mph" 225 "1~252 kph or mph" 226 "1~252 kph or mph" 227 "1~252 kph or mph" 228 "1~252 kph or mph" 229 "1~252 kph or mph" 230 "1~252 kph or mph" 231 "1~252 kph or mph" 232 "1~252 kph or mph" 233 "1~252 kph or mph" 234 "1~252 kph or mph" 235 "1~252 kph or mph" 236 "1~252 kph or mph" 237 "1~252 kph or mph" 238 "1~252 kph or mph" 239 "1~252 kph or mph" 240 "1~252 kph or mph" 241 "1~252 kph or mph" 242 "1~252 kph or mph" 243 "1~252 kph or mph" 244 "1~252 kph or mph" 245 "1~252 kph or mph" 246 "1~252 kph or mph" 247 "1~252 kph or mph" 248 "1~252 kph or mph" 249 "1~252 kph or mph" 250 "1~252 kph or mph" 251 "1~252 kph or mph" 252 "1~252 kph or mph" 253 "Unlimited Speed" 254 "Reserved" 255 "Invalid" ;
VAL_ 1342 ISLA_SpdWrn 0 "No Warning" 1 "Warning" ;
VAL_ 1342 ISLA_SwIgnoreReq 0 "Allow All Switch Inputs (default)" 1 "-(SET) Switch Input Ignore" 2 "+(SET) Switch Input Ignore" 3 "-(SET) & +(SET) Switch Inputs Ignore" ;
VAL_ 1342 ISLA_SymFlashMod 0 "No Flashing" 1 "Flashing Sign" 2 "Flashing - Arrow Symbol" 3 "Flashing + Arrow Symbol" 4 "Flashing Auto Symbol" 5 "Reserved" 6 "Reserved" 7 "Reserved" ;
VAL_ 1260 CF_ISLW_ConInfo_Sta_Con1 0 "None (Default)" 1 "Rain" 2 "Snow" 3 "Snow / Rain" 4 "Trailer" 5 "Reserved" 6 "Reserved" 7 "Reserved" 8 "Reserved" 9 "Reserved" 10 "Reserved" 11 "Reserved" 12 "Reserved" 13 "Reserved" 14 "Generic" 15 "Reserved" ;
VAL_ 1260 CF_ISLW_ConInfo_Sta_Con2 0 "None (Default)" 1 "Rain" 2 "Snow" 3 "Snow / Rain" 4 "Trailer" 5 "Reserved" 6 "Reserved" 7 "Reserved" 8 "Reserved" 9 "Reserved" 10 "Reserved" 11 "Reserved" 12 "Reserved" 13 "Reserved" 14 "Generic" 15 "Reserved" ;
VAL_ 1260 CF_ISLW_Spd_Dis_CLU_Con1 0 "No Recognition (Default)" 1 "1~252 (PH)=1*(HEX) [KPH or MPH" 2 "1~252 (PH)=1*(HEX) [KPH or MPH" 3 "1~252 (PH)=1*(HEX) [KPH or MPH" 4 "1~252 (PH)=1*(HEX) [KPH or MPH" 5 "1~252 (PH)=1*(HEX) [KPH or MPH" 6 "1~252 (PH)=1*(HEX) [KPH or MPH" 7 "1~252 (PH)=1*(HEX) [KPH or MPH" 8 "1~252 (PH)=1*(HEX) [KPH or MPH" 9 "1~252 (PH)=1*(HEX) [KPH or MPH" 10 "1~252 (PH)=1*(HEX) [KPH or MPH" 11 "1~252 (PH)=1*(HEX) [KPH or MPH" 12 "1~252 (PH)=1*(HEX) [KPH or MPH" 13 "1~252 (PH)=1*(HEX) [KPH or MPH" 14 "1~252 (PH)=1*(HEX) [KPH or MPH" 15 "1~252 (PH)=1*(HEX) [KPH or MPH" 16 "1~252 (PH)=1*(HEX) [KPH or MPH" 17 "1~252 (PH)=1*(HEX) [KPH or MPH" 18 "1~252 (PH)=1*(HEX) [KPH or MPH" 19 "1~252 (PH)=1*(HEX) [KPH or MPH" 20 "1~252 (PH)=1*(HEX) [KPH or MPH" 21 "1~252 (PH)=1*(HEX) [KPH or MPH" 22 "1~252 (PH)=1*(HEX) [KPH or MPH" 23 "1~252 (PH)=1*(HEX) [KPH or MPH" 24 "1~252 (PH)=1*(HEX) [KPH or MPH" 25 "1~252 (PH)=1*(HEX) [KPH or MPH" 26 "1~252 (PH)=1*(HEX) [KPH or MPH" 27 "1~252 (PH)=1*(HEX) [KPH or MPH" 28 "1~252 (PH)=1*(HEX) [KPH or MPH" 29 "1~252 (PH)=1*(HEX) [KPH or MPH" 30 "1~252 (PH)=1*(HEX) [KPH or MPH" 31 "1~252 (PH)=1*(HEX) [KPH or MPH" 32 "1~252 (PH)=1*(HEX) [KPH or MPH" 33 "1~252 (PH)=1*(HEX) [KPH or MPH" 34 "1~252 (PH)=1*(HEX) [KPH or MPH" 35 "1~252 (PH)=1*(HEX) [KPH or MPH" 36 "1~252 (PH)=1*(HEX) [KPH or MPH" 37 "1~252 (PH)=1*(HEX) [KPH or MPH" 38 "1~252 (PH)=1*(HEX) [KPH or MPH" 39 "1~252 (PH)=1*(HEX) [KPH or MPH" 40 "1~252 (PH)=1*(HEX) [KPH or MPH" 41 "1~252 (PH)=1*(HEX) [KPH or MPH" 42 "1~252 (PH)=1*(HEX) [KPH or MPH" 43 "1~252 (PH)=1*(HEX) [KPH or MPH" 44 "1~252 (PH)=1*(HEX) [KPH or MPH" 45 "1~252 (PH)=1*(HEX) [KPH or MPH" 46 "1~252 (PH)=1*(HEX) [KPH or MPH" 47 "1~252 (PH)=1*(HEX) [KPH or MPH" 48 "1~252 (PH)=1*(HEX) [KPH or MPH" 49 "1~252 (PH)=1*(HEX) [KPH or MPH" 50 "1~252 (PH)=1*(HEX) [KPH or MPH" 51 "1~252 (PH)=1*(HEX) [KPH or MPH" 52 "1~252 (PH)=1*(HEX) [KPH or MPH" 53 "1~252 (PH)=1*(HEX) [KPH or MPH" 54 "1~252 (PH)=1*(HEX) [KPH or MPH" 55 "1~252 (PH)=1*(HEX) [KPH or MPH" 56 "1~252 (PH)=1*(HEX) [KPH or MPH" 57 "1~252 (PH)=1*(HEX) [KPH or MPH" 58 "1~252 (PH)=1*(HEX) [KPH or MPH" 59 "1~252 (PH)=1*(HEX) [KPH or MPH" 60 "1~252 (PH)=1*(HEX) [KPH or MPH" 61 "1~252 (PH)=1*(HEX) [KPH or MPH" 62 "1~252 (PH)=1*(HEX) [KPH or MPH" 63 "1~252 (PH)=1*(HEX) [KPH or MPH" 64 "1~252 (PH)=1*(HEX) [KPH or MPH" 65 "1~252 (PH)=1*(HEX) [KPH or MPH" 66 "1~252 (PH)=1*(HEX) [KPH or MPH" 67 "1~252 (PH)=1*(HEX) [KPH or MPH" 68 "1~252 (PH)=1*(HEX) [KPH or MPH" 69 "1~252 (PH)=1*(HEX) [KPH or MPH" 70 "1~252 (PH)=1*(HEX) [KPH or MPH" 71 "1~252 (PH)=1*(HEX) [KPH or MPH" 72 "1~252 (PH)=1*(HEX) [KPH or MPH" 73 "1~252 (PH)=1*(HEX) [KPH or MPH" 74 "1~252 (PH)=1*(HEX) [KPH or MPH" 75 "1~252 (PH)=1*(HEX) [KPH or MPH" 76 "1~252 (PH)=1*(HEX) [KPH or MPH" 77 "1~252 (PH)=1*(HEX) [KPH or MPH" 78 "1~252 (PH)=1*(HEX) [KPH or MPH" 79 "1~252 (PH)=1*(HEX) [KPH or MPH" 80 "1~252 (PH)=1*(HEX) [KPH or MPH" 81 "1~252 (PH)=1*(HEX) [KPH or MPH" 82 "1~252 (PH)=1*(HEX) [KPH or MPH" 83 "1~252 (PH)=1*(HEX) [KPH or MPH" 84 "1~252 (PH)=1*(HEX) [KPH or MPH" 85 "1~252 (PH)=1*(HEX) [KPH or MPH" 86 "1~252 (PH)=1*(HEX) [KPH or MPH" 87 "1~252 (PH)=1*(HEX) [KPH or MPH" 88 "1~252 (PH)=1*(HEX) [KPH or MPH" 89 "1~252 (PH)=1*(HEX) [KPH or MPH" 90 "1~252 (PH)=1*(HEX) [KPH or MPH" 91 "1~252 (PH)=1*(HEX) [KPH or MPH" 92 "1~252 (PH)=1*(HEX) [KPH or MPH" 93 "1~252 (PH)=1*(HEX) [KPH or MPH" 94 "1~252 (PH)=1*(HEX) [KPH or MPH" 95 "1~252 (PH)=1*(HEX) [KPH or MPH" 96 "1~252 (PH)=1*(HEX) [KPH or MPH" 97 "1~252 (PH)=1*(HEX) [KPH or MPH" 98 "1~252 (PH)=1*(HEX) [KPH or MPH" 99 "1~252 (PH)=1*(HEX) [KPH or MPH" 100 "1~252 (PH)=1*(HEX) [KPH or MPH" 101 "1~252 (PH)=1*(HEX) [KPH or MPH" 102 "1~252 (PH)=1*(HEX) [KPH or MPH" 103 "1~252 (PH)=1*(HEX) [KPH or MPH" 104 "1~252 (PH)=1*(HEX) [KPH or MPH" 105 "1~252 (PH)=1*(HEX) [KPH or MPH" 106 "1~252 (PH)=1*(HEX) [KPH or MPH" 107 "1~252 (PH)=1*(HEX) [KPH or MPH" 108 "1~252 (PH)=1*(HEX) [KPH or MPH" 109 "1~252 (PH)=1*(HEX) [KPH or MPH" 110 "1~252 (PH)=1*(HEX) [KPH or MPH" 111 "1~252 (PH)=1*(HEX) [KPH or MPH" 112 "1~252 (PH)=1*(HEX) [KPH or MPH" 113 "1~252 (PH)=1*(HEX) [KPH or MPH" 114 "1~252 (PH)=1*(HEX) [KPH or MPH" 115 "1~252 (PH)=1*(HEX) [KPH or MPH" 116 "1~252 (PH)=1*(HEX) [KPH or MPH" 117 "1~252 (PH)=1*(HEX) [KPH or MPH" 118 "1~252 (PH)=1*(HEX) [KPH or MPH" 119 "1~252 (PH)=1*(HEX) [KPH or MPH" 120 "1~252 (PH)=1*(HEX) [KPH or MPH" 121 "1~252 (PH)=1*(HEX) [KPH or MPH" 122 "1~252 (PH)=1*(HEX) [KPH or MPH" 123 "1~252 (PH)=1*(HEX) [KPH or MPH" 124 "1~252 (PH)=1*(HEX) [KPH or MPH" 125 "1~252 (PH)=1*(HEX) [KPH or MPH" 126 "1~252 (PH)=1*(HEX) [KPH or MPH" 127 "1~252 (PH)=1*(HEX) [KPH or MPH" 128 "1~252 (PH)=1*(HEX) [KPH or MPH" 129 "1~252 (PH)=1*(HEX) [KPH or MPH" 130 "1~252 (PH)=1*(HEX) [KPH or MPH" 131 "1~252 (PH)=1*(HEX) [KPH or MPH" 132 "1~252 (PH)=1*(HEX) [KPH or MPH" 133 "1~252 (PH)=1*(HEX) [KPH or MPH" 134 "1~252 (PH)=1*(HEX) [KPH or MPH" 135 "1~252 (PH)=1*(HEX) [KPH or MPH" 136 "1~252 (PH)=1*(HEX) [KPH or MPH" 137 "1~252 (PH)=1*(HEX) [KPH or MPH" 138 "1~252 (PH)=1*(HEX) [KPH or MPH" 139 "1~252 (PH)=1*(HEX) [KPH or MPH" 140 "1~252 (PH)=1*(HEX) [KPH or MPH" 141 "1~252 (PH)=1*(HEX) [KPH or MPH" 142 "1~252 (PH)=1*(HEX) [KPH or MPH" 143 "1~252 (PH)=1*(HEX) [KPH or MPH" 144 "1~252 (PH)=1*(HEX) [KPH or MPH" 145 "1~252 (PH)=1*(HEX) [KPH or MPH" 146 "1~252 (PH)=1*(HEX) [KPH or MPH" 147 "1~252 (PH)=1*(HEX) [KPH or MPH" 148 "1~252 (PH)=1*(HEX) [KPH or MPH" 149 "1~252 (PH)=1*(HEX) [KPH or MPH" 150 "1~252 (PH)=1*(HEX) [KPH or MPH" 151 "1~252 (PH)=1*(HEX) [KPH or MPH" 152 "1~252 (PH)=1*(HEX) [KPH or MPH" 153 "1~252 (PH)=1*(HEX) [KPH or MPH" 154 "1~252 (PH)=1*(HEX) [KPH or MPH" 155 "1~252 (PH)=1*(HEX) [KPH or MPH" 156 "1~252 (PH)=1*(HEX) [KPH or MPH" 157 "1~252 (PH)=1*(HEX) [KPH or MPH" 158 "1~252 (PH)=1*(HEX) [KPH or MPH" 159 "1~252 (PH)=1*(HEX) [KPH or MPH" 160 "1~252 (PH)=1*(HEX) [KPH or MPH" 161 "1~252 (PH)=1*(HEX) [KPH or MPH" 162 "1~252 (PH)=1*(HEX) [KPH or MPH" 163 "1~252 (PH)=1*(HEX) [KPH or MPH" 164 "1~252 (PH)=1*(HEX) [KPH or MPH" 165 "1~252 (PH)=1*(HEX) [KPH or MPH" 166 "1~252 (PH)=1*(HEX) [KPH or MPH" 167 "1~252 (PH)=1*(HEX) [KPH or MPH" 168 "1~252 (PH)=1*(HEX) [KPH or MPH" 169 "1~252 (PH)=1*(HEX) [KPH or MPH" 170 "1~252 (PH)=1*(HEX) [KPH or MPH" 171 "1~252 (PH)=1*(HEX) [KPH or MPH" 172 "1~252 (PH)=1*(HEX) [KPH or MPH" 173 "1~252 (PH)=1*(HEX) [KPH or MPH" 174 "1~252 (PH)=1*(HEX) [KPH or MPH" 175 "1~252 (PH)=1*(HEX) [KPH or MPH" 176 "1~252 (PH)=1*(HEX) [KPH or MPH" 177 "1~252 (PH)=1*(HEX) [KPH or MPH" 178 "1~252 (PH)=1*(HEX) [KPH or MPH" 179 "1~252 (PH)=1*(HEX) [KPH or MPH" 180 "1~252 (PH)=1*(HEX) [KPH or MPH" 181 "1~252 (PH)=1*(HEX) [KPH or MPH" 182 "1~252 (PH)=1*(HEX) [KPH or MPH" 183 "1~252 (PH)=1*(HEX) [KPH or MPH" 184 "1~252 (PH)=1*(HEX) [KPH or MPH" 185 "1~252 (PH)=1*(HEX) [KPH or MPH" 186 "1~252 (PH)=1*(HEX) [KPH or MPH" 187 "1~252 (PH)=1*(HEX) [KPH or MPH" 188 "1~252 (PH)=1*(HEX) [KPH or MPH" 189 "1~252 (PH)=1*(HEX) [KPH or MPH" 190 "1~252 (PH)=1*(HEX) [KPH or MPH" 191 "1~252 (PH)=1*(HEX) [KPH or MPH" 192 "1~252 (PH)=1*(HEX) [KPH or MPH" 193 "1~252 (PH)=1*(HEX) [KPH or MPH" 194 "1~252 (PH)=1*(HEX) [KPH or MPH" 195 "1~252 (PH)=1*(HEX) [KPH or MPH" 196 "1~252 (PH)=1*(HEX) [KPH or MPH" 197 "1~252 (PH)=1*(HEX) [KPH or MPH" 198 "1~252 (PH)=1*(HEX) [KPH or MPH" 199 "1~252 (PH)=1*(HEX) [KPH or MPH" 200 "1~252 (PH)=1*(HEX) [KPH or MPH" 201 "1~252 (PH)=1*(HEX) [KPH or MPH" 202 "1~252 (PH)=1*(HEX) [KPH or MPH" 203 "1~252 (PH)=1*(HEX) [KPH or MPH" 204 "1~252 (PH)=1*(HEX) [KPH or MPH" 205 "1~252 (PH)=1*(HEX) [KPH or MPH" 206 "1~252 (PH)=1*(HEX) [KPH or MPH" 207 "1~252 (PH)=1*(HEX) [KPH or MPH" 208 "1~252 (PH)=1*(HEX) [KPH or MPH" 209 "1~252 (PH)=1*(HEX) [KPH or MPH" 210 "1~252 (PH)=1*(HEX) [KPH or MPH" 211 "1~252 (PH)=1*(HEX) [KPH or MPH" 212 "1~252 (PH)=1*(HEX) [KPH or MPH" 213 "1~252 (PH)=1*(HEX) [KPH or MPH" 214 "1~252 (PH)=1*(HEX) [KPH or MPH" 215 "1~252 (PH)=1*(HEX) [KPH or MPH" 216 "1~252 (PH)=1*(HEX) [KPH or MPH" 217 "1~252 (PH)=1*(HEX) [KPH or MPH" 218 "1~252 (PH)=1*(HEX) [KPH or MPH" 219 "1~252 (PH)=1*(HEX) [KPH or MPH" 220 "1~252 (PH)=1*(HEX) [KPH or MPH" 221 "1~252 (PH)=1*(HEX) [KPH or MPH" 222 "1~252 (PH)=1*(HEX) [KPH or MPH" 223 "1~252 (PH)=1*(HEX) [KPH or MPH" 224 "1~252 (PH)=1*(HEX) [KPH or MPH" 225 "1~252 (PH)=1*(HEX) [KPH or MPH" 226 "1~252 (PH)=1*(HEX) [KPH or MPH" 227 "1~252 (PH)=1*(HEX) [KPH or MPH" 228 "1~252 (PH)=1*(HEX) [KPH or MPH" 229 "1~252 (PH)=1*(HEX) [KPH or MPH" 230 "1~252 (PH)=1*(HEX) [KPH or MPH" 231 "1~252 (PH)=1*(HEX) [KPH or MPH" 232 "1~252 (PH)=1*(HEX) [KPH or MPH" 233 "1~252 (PH)=1*(HEX) [KPH or MPH" 234 "1~252 (PH)=1*(HEX) [KPH or MPH" 235 "1~252 (PH)=1*(HEX) [KPH or MPH" 236 "1~252 (PH)=1*(HEX) [KPH or MPH" 237 "1~252 (PH)=1*(HEX) [KPH or MPH" 238 "1~252 (PH)=1*(HEX) [KPH or MPH" 239 "1~252 (PH)=1*(HEX) [KPH or MPH" 240 "1~252 (PH)=1*(HEX) [KPH or MPH" 241 "1~252 (PH)=1*(HEX) [KPH or MPH" 242 "1~252 (PH)=1*(HEX) [KPH or MPH" 243 "1~252 (PH)=1*(HEX) [KPH or MPH" 244 "1~252 (PH)=1*(HEX) [KPH or MPH" 245 "1~252 (PH)=1*(HEX) [KPH or MPH" 246 "1~252 (PH)=1*(HEX) [KPH or MPH" 247 "1~252 (PH)=1*(HEX) [KPH or MPH" 248 "1~252 (PH)=1*(HEX) [KPH or MPH" 249 "1~252 (PH)=1*(HEX) [KPH or MPH" 250 "1~252 (PH)=1*(HEX) [KPH or MPH" 251 "1~252 (PH)=1*(HEX) [KPH or MPH" 252 "1~252 (PH)=1*(HEX) [KPH or MPH" 253 "LHD Conditional No Passing ZONE" 254 "RHD Conditional No Passing ZONE" 255 "Invalid" ;
VAL_ 1260 CF_ISLW_Spd_Dis_CLU_Con2 0 "No Recognition (Default)" 1 "1~252 (PH)=1*(HEX) [KPH or MPH" 2 "1~252 (PH)=1*(HEX) [KPH or MPH" 3 "1~252 (PH)=1*(HEX) [KPH or MPH" 4 "1~252 (PH)=1*(HEX) [KPH or MPH" 5 "1~252 (PH)=1*(HEX) [KPH or MPH" 6 "1~252 (PH)=1*(HEX) [KPH or MPH" 7 "1~252 (PH)=1*(HEX) [KPH or MPH" 8 "1~252 (PH)=1*(HEX) [KPH or MPH" 9 "1~252 (PH)=1*(HEX) [KPH or MPH" 10 "1~252 (PH)=1*(HEX) [KPH or MPH" 11 "1~252 (PH)=1*(HEX) [KPH or MPH" 12 "1~252 (PH)=1*(HEX) [KPH or MPH" 13 "1~252 (PH)=1*(HEX) [KPH or MPH" 14 "1~252 (PH)=1*(HEX) [KPH or MPH" 15 "1~252 (PH)=1*(HEX) [KPH or MPH" 16 "1~252 (PH)=1*(HEX) [KPH or MPH" 17 "1~252 (PH)=1*(HEX) [KPH or MPH" 18 "1~252 (PH)=1*(HEX) [KPH or MPH" 19 "1~252 (PH)=1*(HEX) [KPH or MPH" 20 "1~252 (PH)=1*(HEX) [KPH or MPH" 21 "1~252 (PH)=1*(HEX) [KPH or MPH" 22 "1~252 (PH)=1*(HEX) [KPH or MPH" 23 "1~252 (PH)=1*(HEX) [KPH or MPH" 24 "1~252 (PH)=1*(HEX) [KPH or MPH" 25 "1~252 (PH)=1*(HEX) [KPH or MPH" 26 "1~252 (PH)=1*(HEX) [KPH or MPH" 27 "1~252 (PH)=1*(HEX) [KPH or MPH" 28 "1~252 (PH)=1*(HEX) [KPH or MPH" 29 "1~252 (PH)=1*(HEX) [KPH or MPH" 30 "1~252 (PH)=1*(HEX) [KPH or MPH" 31 "1~252 (PH)=1*(HEX) [KPH or MPH" 32 "1~252 (PH)=1*(HEX) [KPH or MPH" 33 "1~252 (PH)=1*(HEX) [KPH or MPH" 34 "1~252 (PH)=1*(HEX) [KPH or MPH" 35 "1~252 (PH)=1*(HEX) [KPH or MPH" 36 "1~252 (PH)=1*(HEX) [KPH or MPH" 37 "1~252 (PH)=1*(HEX) [KPH or MPH" 38 "1~252 (PH)=1*(HEX) [KPH or MPH" 39 "1~252 (PH)=1*(HEX) [KPH or MPH" 40 "1~252 (PH)=1*(HEX) [KPH or MPH" 41 "1~252 (PH)=1*(HEX) [KPH or MPH" 42 "1~252 (PH)=1*(HEX) [KPH or MPH" 43 "1~252 (PH)=1*(HEX) [KPH or MPH" 44 "1~252 (PH)=1*(HEX) [KPH or MPH" 45 "1~252 (PH)=1*(HEX) [KPH or MPH" 46 "1~252 (PH)=1*(HEX) [KPH or MPH" 47 "1~252 (PH)=1*(HEX) [KPH or MPH" 48 "1~252 (PH)=1*(HEX) [KPH or MPH" 49 "1~252 (PH)=1*(HEX) [KPH or MPH" 50 "1~252 (PH)=1*(HEX) [KPH or MPH" 51 "1~252 (PH)=1*(HEX) [KPH or MPH" 52 "1~252 (PH)=1*(HEX) [KPH or MPH" 53 "1~252 (PH)=1*(HEX) [KPH or MPH" 54 "1~252 (PH)=1*(HEX) [KPH or MPH" 55 "1~252 (PH)=1*(HEX) [KPH or MPH" 56 "1~252 (PH)=1*(HEX) [KPH or MPH" 57 "1~252 (PH)=1*(HEX) [KPH or MPH" 58 "1~252 (PH)=1*(HEX) [KPH or MPH" 59 "1~252 (PH)=1*(HEX) [KPH or MPH" 60 "1~252 (PH)=1*(HEX) [KPH or MPH" 61 "1~252 (PH)=1*(HEX) [KPH or MPH" 62 "1~252 (PH)=1*(HEX) [KPH or MPH" 63 "1~252 (PH)=1*(HEX) [KPH or MPH" 64 "1~252 (PH)=1*(HEX) [KPH or MPH" 65 "1~252 (PH)=1*(HEX) [KPH or MPH" 66 "1~252 (PH)=1*(HEX) [KPH or MPH" 67 "1~252 (PH)=1*(HEX) [KPH or MPH" 68 "1~252 (PH)=1*(HEX) [KPH or MPH" 69 "1~252 (PH)=1*(HEX) [KPH or MPH" 70 "1~252 (PH)=1*(HEX) [KPH or MPH" 71 "1~252 (PH)=1*(HEX) [KPH or MPH" 72 "1~252 (PH)=1*(HEX) [KPH or MPH" 73 "1~252 (PH)=1*(HEX) [KPH or MPH" 74 "1~252 (PH)=1*(HEX) [KPH or MPH" 75 "1~252 (PH)=1*(HEX) [KPH or MPH" 76 "1~252 (PH)=1*(HEX) [KPH or MPH" 77 "1~252 (PH)=1*(HEX) [KPH or MPH" 78 "1~252 (PH)=1*(HEX) [KPH or MPH" 79 "1~252 (PH)=1*(HEX) [KPH or MPH" 80 "1~252 (PH)=1*(HEX) [KPH or MPH" 81 "1~252 (PH)=1*(HEX) [KPH or MPH" 82 "1~252 (PH)=1*(HEX) [KPH or MPH" 83 "1~252 (PH)=1*(HEX) [KPH or MPH" 84 "1~252 (PH)=1*(HEX) [KPH or MPH" 85 "1~252 (PH)=1*(HEX) [KPH or MPH" 86 "1~252 (PH)=1*(HEX) [KPH or MPH" 87 "1~252 (PH)=1*(HEX) [KPH or MPH" 88 "1~252 (PH)=1*(HEX) [KPH or MPH" 89 "1~252 (PH)=1*(HEX) [KPH or MPH" 90 "1~252 (PH)=1*(HEX) [KPH or MPH" 91 "1~252 (PH)=1*(HEX) [KPH or MPH" 92 "1~252 (PH)=1*(HEX) [KPH or MPH" 93 "1~252 (PH)=1*(HEX) [KPH or MPH" 94 "1~252 (PH)=1*(HEX) [KPH or MPH" 95 "1~252 (PH)=1*(HEX) [KPH or MPH" 96 "1~252 (PH)=1*(HEX) [KPH or MPH" 97 "1~252 (PH)=1*(HEX) [KPH or MPH" 98 "1~252 (PH)=1*(HEX) [KPH or MPH" 99 "1~252 (PH)=1*(HEX) [KPH or MPH" 100 "1~252 (PH)=1*(HEX) [KPH or MPH" 101 "1~252 (PH)=1*(HEX) [KPH or MPH" 102 "1~252 (PH)=1*(HEX) [KPH or MPH" 103 "1~252 (PH)=1*(HEX) [KPH or MPH" 104 "1~252 (PH)=1*(HEX) [KPH or MPH" 105 "1~252 (PH)=1*(HEX) [KPH or MPH" 106 "1~252 (PH)=1*(HEX) [KPH or MPH" 107 "1~252 (PH)=1*(HEX) [KPH or MPH" 108 "1~252 (PH)=1*(HEX) [KPH or MPH" 109 "1~252 (PH)=1*(HEX) [KPH or MPH" 110 "1~252 (PH)=1*(HEX) [KPH or MPH" 111 "1~252 (PH)=1*(HEX) [KPH or MPH" 112 "1~252 (PH)=1*(HEX) [KPH or MPH" 113 "1~252 (PH)=1*(HEX) [KPH or MPH" 114 "1~252 (PH)=1*(HEX) [KPH or MPH" 115 "1~252 (PH)=1*(HEX) [KPH or MPH" 116 "1~252 (PH)=1*(HEX) [KPH or MPH" 117 "1~252 (PH)=1*(HEX) [KPH or MPH" 118 "1~252 (PH)=1*(HEX) [KPH or MPH" 119 "1~252 (PH)=1*(HEX) [KPH or MPH" 120 "1~252 (PH)=1*(HEX) [KPH or MPH" 121 "1~252 (PH)=1*(HEX) [KPH or MPH" 122 "1~252 (PH)=1*(HEX) [KPH or MPH" 123 "1~252 (PH)=1*(HEX) [KPH or MPH" 124 "1~252 (PH)=1*(HEX) [KPH or MPH" 125 "1~252 (PH)=1*(HEX) [KPH or MPH" 126 "1~252 (PH)=1*(HEX) [KPH or MPH" 127 "1~252 (PH)=1*(HEX) [KPH or MPH" 128 "1~252 (PH)=1*(HEX) [KPH or MPH" 129 "1~252 (PH)=1*(HEX) [KPH or MPH" 130 "1~252 (PH)=1*(HEX) [KPH or MPH" 131 "1~252 (PH)=1*(HEX) [KPH or MPH" 132 "1~252 (PH)=1*(HEX) [KPH or MPH" 133 "1~252 (PH)=1*(HEX) [KPH or MPH" 134 "1~252 (PH)=1*(HEX) [KPH or MPH" 135 "1~252 (PH)=1*(HEX) [KPH or MPH" 136 "1~252 (PH)=1*(HEX) [KPH or MPH" 137 "1~252 (PH)=1*(HEX) [KPH or MPH" 138 "1~252 (PH)=1*(HEX) [KPH or MPH" 139 "1~252 (PH)=1*(HEX) [KPH or MPH" 140 "1~252 (PH)=1*(HEX) [KPH or MPH" 141 "1~252 (PH)=1*(HEX) [KPH or MPH" 142 "1~252 (PH)=1*(HEX) [KPH or MPH" 143 "1~252 (PH)=1*(HEX) [KPH or MPH" 144 "1~252 (PH)=1*(HEX) [KPH or MPH" 145 "1~252 (PH)=1*(HEX) [KPH or MPH" 146 "1~252 (PH)=1*(HEX) [KPH or MPH" 147 "1~252 (PH)=1*(HEX) [KPH or MPH" 148 "1~252 (PH)=1*(HEX) [KPH or MPH" 149 "1~252 (PH)=1*(HEX) [KPH or MPH" 150 "1~252 (PH)=1*(HEX) [KPH or MPH" 151 "1~252 (PH)=1*(HEX) [KPH or MPH" 152 "1~252 (PH)=1*(HEX) [KPH or MPH" 153 "1~252 (PH)=1*(HEX) [KPH or MPH" 154 "1~252 (PH)=1*(HEX) [KPH or MPH" 155 "1~252 (PH)=1*(HEX) [KPH or MPH" 156 "1~252 (PH)=1*(HEX) [KPH or MPH" 157 "1~252 (PH)=1*(HEX) [KPH or MPH" 158 "1~252 (PH)=1*(HEX) [KPH or MPH" 159 "1~252 (PH)=1*(HEX) [KPH or MPH" 160 "1~252 (PH)=1*(HEX) [KPH or MPH" 161 "1~252 (PH)=1*(HEX) [KPH or MPH" 162 "1~252 (PH)=1*(HEX) [KPH or MPH" 163 "1~252 (PH)=1*(HEX) [KPH or MPH" 164 "1~252 (PH)=1*(HEX) [KPH or MPH" 165 "1~252 (PH)=1*(HEX) [KPH or MPH" 166 "1~252 (PH)=1*(HEX) [KPH or MPH" 167 "1~252 (PH)=1*(HEX) [KPH or MPH" 168 "1~252 (PH)=1*(HEX) [KPH or MPH" 169 "1~252 (PH)=1*(HEX) [KPH or MPH" 170 "1~252 (PH)=1*(HEX) [KPH or MPH" 171 "1~252 (PH)=1*(HEX) [KPH or MPH" 172 "1~252 (PH)=1*(HEX) [KPH or MPH" 173 "1~252 (PH)=1*(HEX) [KPH or MPH" 174 "1~252 (PH)=1*(HEX) [KPH or MPH" 175 "1~252 (PH)=1*(HEX) [KPH or MPH" 176 "1~252 (PH)=1*(HEX) [KPH or MPH" 177 "1~252 (PH)=1*(HEX) [KPH or MPH" 178 "1~252 (PH)=1*(HEX) [KPH or MPH" 179 "1~252 (PH)=1*(HEX) [KPH or MPH" 180 "1~252 (PH)=1*(HEX) [KPH or MPH" 181 "1~252 (PH)=1*(HEX) [KPH or MPH" 182 "1~252 (PH)=1*(HEX) [KPH or MPH" 183 "1~252 (PH)=1*(HEX) [KPH or MPH" 184 "1~252 (PH)=1*(HEX) [KPH or MPH" 185 "1~252 (PH)=1*(HEX) [KPH or MPH" 186 "1~252 (PH)=1*(HEX) [KPH or MPH" 187 "1~252 (PH)=1*(HEX) [KPH or MPH" 188 "1~252 (PH)=1*(HEX) [KPH or MPH" 189 "1~252 (PH)=1*(HEX) [KPH or MPH" 190 "1~252 (PH)=1*(HEX) [KPH or MPH" 191 "1~252 (PH)=1*(HEX) [KPH or MPH" 192 "1~252 (PH)=1*(HEX) [KPH or MPH" 193 "1~252 (PH)=1*(HEX) [KPH or MPH" 194 "1~252 (PH)=1*(HEX) [KPH or MPH" 195 "1~252 (PH)=1*(HEX) [KPH or MPH" 196 "1~252 (PH)=1*(HEX) [KPH or MPH" 197 "1~252 (PH)=1*(HEX) [KPH or MPH" 198 "1~252 (PH)=1*(HEX) [KPH or MPH" 199 "1~252 (PH)=1*(HEX) [KPH or MPH" 200 "1~252 (PH)=1*(HEX) [KPH or MPH" 201 "1~252 (PH)=1*(HEX) [KPH or MPH" 202 "1~252 (PH)=1*(HEX) [KPH or MPH" 203 "1~252 (PH)=1*(HEX) [KPH or MPH" 204 "1~252 (PH)=1*(HEX) [KPH or MPH" 205 "1~252 (PH)=1*(HEX) [KPH or MPH" 206 "1~252 (PH)=1*(HEX) [KPH or MPH" 207 "1~252 (PH)=1*(HEX) [KPH or MPH" 208 "1~252 (PH)=1*(HEX) [KPH or MPH" 209 "1~252 (PH)=1*(HEX) [KPH or MPH" 210 "1~252 (PH)=1*(HEX) [KPH or MPH" 211 "1~252 (PH)=1*(HEX) [KPH or MPH" 212 "1~252 (PH)=1*(HEX) [KPH or MPH" 213 "1~252 (PH)=1*(HEX) [KPH or MPH" 214 "1~252 (PH)=1*(HEX) [KPH or MPH" 215 "1~252 (PH)=1*(HEX) [KPH or MPH" 216 "1~252 (PH)=1*(HEX) [KPH or MPH" 217 "1~252 (PH)=1*(HEX) [KPH or MPH" 218 "1~252 (PH)=1*(HEX) [KPH or MPH" 219 "1~252 (PH)=1*(HEX) [KPH or MPH" 220 "1~252 (PH)=1*(HEX) [KPH or MPH" 221 "1~252 (PH)=1*(HEX) [KPH or MPH" 222 "1~252 (PH)=1*(HEX) [KPH or MPH" 223 "1~252 (PH)=1*(HEX) [KPH or MPH" 224 "1~252 (PH)=1*(HEX) [KPH or MPH" 225 "1~252 (PH)=1*(HEX) [KPH or MPH" 226 "1~252 (PH)=1*(HEX) [KPH or MPH" 227 "1~252 (PH)=1*(HEX) [KPH or MPH" 228 "1~252 (PH)=1*(HEX) [KPH or MPH" 229 "1~252 (PH)=1*(HEX) [KPH or MPH" 230 "1~252 (PH)=1*(HEX) [KPH or MPH" 231 "1~252 (PH)=1*(HEX) [KPH or MPH" 232 "1~252 (PH)=1*(HEX) [KPH or MPH" 233 "1~252 (PH)=1*(HEX) [KPH or MPH" 234 "1~252 (PH)=1*(HEX) [KPH or MPH" 235 "1~252 (PH)=1*(HEX) [KPH or MPH" 236 "1~252 (PH)=1*(HEX) [KPH or MPH" 237 "1~252 (PH)=1*(HEX) [KPH or MPH" 238 "1~252 (PH)=1*(HEX) [KPH or MPH" 239 "1~252 (PH)=1*(HEX) [KPH or MPH" 240 "1~252 (PH)=1*(HEX) [KPH or MPH" 241 "1~252 (PH)=1*(HEX) [KPH or MPH" 242 "1~252 (PH)=1*(HEX) [KPH or MPH" 243 "1~252 (PH)=1*(HEX) [KPH or MPH" 244 "1~252 (PH)=1*(HEX) [KPH or MPH" 245 "1~252 (PH)=1*(HEX) [KPH or MPH" 246 "1~252 (PH)=1*(HEX) [KPH or MPH" 247 "1~252 (PH)=1*(HEX) [KPH or MPH" 248 "1~252 (PH)=1*(HEX) [KPH or MPH" 249 "1~252 (PH)=1*(HEX) [KPH or MPH" 250 "1~252 (PH)=1*(HEX) [KPH or MPH" 251 "1~252 (PH)=1*(HEX) [KPH or MPH" 252 "1~252 (PH)=1*(HEX) [KPH or MPH" 253 "LHD Conditional No Passing ZONE" 254 "RHD Conditional No Passing ZONE" 255 "Invalid" ;
VAL_ 1260 CF_ISLW_Spd_Dis_NAVI_Con1 0 "No Recognition (Default)" 1 "1~252 (PH)=1*(HEX) [KPH or MPH" 2 "1~252 (PH)=1*(HEX) [KPH or MPH" 3 "1~252 (PH)=1*(HEX) [KPH or MPH" 4 "1~252 (PH)=1*(HEX) [KPH or MPH" 5 "1~252 (PH)=1*(HEX) [KPH or MPH" 6 "1~252 (PH)=1*(HEX) [KPH or MPH" 7 "1~252 (PH)=1*(HEX) [KPH or MPH" 8 "1~252 (PH)=1*(HEX) [KPH or MPH" 9 "1~252 (PH)=1*(HEX) [KPH or MPH" 10 "1~252 (PH)=1*(HEX) [KPH or MPH" 11 "1~252 (PH)=1*(HEX) [KPH or MPH" 12 "1~252 (PH)=1*(HEX) [KPH or MPH" 13 "1~252 (PH)=1*(HEX) [KPH or MPH" 14 "1~252 (PH)=1*(HEX) [KPH or MPH" 15 "1~252 (PH)=1*(HEX) [KPH or MPH" 16 "1~252 (PH)=1*(HEX) [KPH or MPH" 17 "1~252 (PH)=1*(HEX) [KPH or MPH" 18 "1~252 (PH)=1*(HEX) [KPH or MPH" 19 "1~252 (PH)=1*(HEX) [KPH or MPH" 20 "1~252 (PH)=1*(HEX) [KPH or MPH" 21 "1~252 (PH)=1*(HEX) [KPH or MPH" 22 "1~252 (PH)=1*(HEX) [KPH or MPH" 23 "1~252 (PH)=1*(HEX) [KPH or MPH" 24 "1~252 (PH)=1*(HEX) [KPH or MPH" 25 "1~252 (PH)=1*(HEX) [KPH or MPH" 26 "1~252 (PH)=1*(HEX) [KPH or MPH" 27 "1~252 (PH)=1*(HEX) [KPH or MPH" 28 "1~252 (PH)=1*(HEX) [KPH or MPH" 29 "1~252 (PH)=1*(HEX) [KPH or MPH" 30 "1~252 (PH)=1*(HEX) [KPH or MPH" 31 "1~252 (PH)=1*(HEX) [KPH or MPH" 32 "1~252 (PH)=1*(HEX) [KPH or MPH" 33 "1~252 (PH)=1*(HEX) [KPH or MPH" 34 "1~252 (PH)=1*(HEX) [KPH or MPH" 35 "1~252 (PH)=1*(HEX) [KPH or MPH" 36 "1~252 (PH)=1*(HEX) [KPH or MPH" 37 "1~252 (PH)=1*(HEX) [KPH or MPH" 38 "1~252 (PH)=1*(HEX) [KPH or MPH" 39 "1~252 (PH)=1*(HEX) [KPH or MPH" 40 "1~252 (PH)=1*(HEX) [KPH or MPH" 41 "1~252 (PH)=1*(HEX) [KPH or MPH" 42 "1~252 (PH)=1*(HEX) [KPH or MPH" 43 "1~252 (PH)=1*(HEX) [KPH or MPH" 44 "1~252 (PH)=1*(HEX) [KPH or MPH" 45 "1~252 (PH)=1*(HEX) [KPH or MPH" 46 "1~252 (PH)=1*(HEX) [KPH or MPH" 47 "1~252 (PH)=1*(HEX) [KPH or MPH" 48 "1~252 (PH)=1*(HEX) [KPH or MPH" 49 "1~252 (PH)=1*(HEX) [KPH or MPH" 50 "1~252 (PH)=1*(HEX) [KPH or MPH" 51 "1~252 (PH)=1*(HEX) [KPH or MPH" 52 "1~252 (PH)=1*(HEX) [KPH or MPH" 53 "1~252 (PH)=1*(HEX) [KPH or MPH" 54 "1~252 (PH)=1*(HEX) [KPH or MPH" 55 "1~252 (PH)=1*(HEX) [KPH or MPH" 56 "1~252 (PH)=1*(HEX) [KPH or MPH" 57 "1~252 (PH)=1*(HEX) [KPH or MPH" 58 "1~252 (PH)=1*(HEX) [KPH or MPH" 59 "1~252 (PH)=1*(HEX) [KPH or MPH" 60 "1~252 (PH)=1*(HEX) [KPH or MPH" 61 "1~252 (PH)=1*(HEX) [KPH or MPH" 62 "1~252 (PH)=1*(HEX) [KPH or MPH" 63 "1~252 (PH)=1*(HEX) [KPH or MPH" 64 "1~252 (PH)=1*(HEX) [KPH or MPH" 65 "1~252 (PH)=1*(HEX) [KPH or MPH" 66 "1~252 (PH)=1*(HEX) [KPH or MPH" 67 "1~252 (PH)=1*(HEX) [KPH or MPH" 68 "1~252 (PH)=1*(HEX) [KPH or MPH" 69 "1~252 (PH)=1*(HEX) [KPH or MPH" 70 "1~252 (PH)=1*(HEX) [KPH or MPH" 71 "1~252 (PH)=1*(HEX) [KPH or MPH" 72 "1~252 (PH)=1*(HEX) [KPH or MPH" 73 "1~252 (PH)=1*(HEX) [KPH or MPH" 74 "1~252 (PH)=1*(HEX) [KPH or MPH" 75 "1~252 (PH)=1*(HEX) [KPH or MPH" 76 "1~252 (PH)=1*(HEX) [KPH or MPH" 77 "1~252 (PH)=1*(HEX) [KPH or MPH" 78 "1~252 (PH)=1*(HEX) [KPH or MPH" 79 "1~252 (PH)=1*(HEX) [KPH or MPH" 80 "1~252 (PH)=1*(HEX) [KPH or MPH" 81 "1~252 (PH)=1*(HEX) [KPH or MPH" 82 "1~252 (PH)=1*(HEX) [KPH or MPH" 83 "1~252 (PH)=1*(HEX) [KPH or MPH" 84 "1~252 (PH)=1*(HEX) [KPH or MPH" 85 "1~252 (PH)=1*(HEX) [KPH or MPH" 86 "1~252 (PH)=1*(HEX) [KPH or MPH" 87 "1~252 (PH)=1*(HEX) [KPH or MPH" 88 "1~252 (PH)=1*(HEX) [KPH or MPH" 89 "1~252 (PH)=1*(HEX) [KPH or MPH" 90 "1~252 (PH)=1*(HEX) [KPH or MPH" 91 "1~252 (PH)=1*(HEX) [KPH or MPH" 92 "1~252 (PH)=1*(HEX) [KPH or MPH" 93 "1~252 (PH)=1*(HEX) [KPH or MPH" 94 "1~252 (PH)=1*(HEX) [KPH or MPH" 95 "1~252 (PH)=1*(HEX) [KPH or MPH" 96 "1~252 (PH)=1*(HEX) [KPH or MPH" 97 "1~252 (PH)=1*(HEX) [KPH or MPH" 98 "1~252 (PH)=1*(HEX) [KPH or MPH" 99 "1~252 (PH)=1*(HEX) [KPH or MPH" 100 "1~252 (PH)=1*(HEX) [KPH or MPH" 101 "1~252 (PH)=1*(HEX) [KPH or MPH" 102 "1~252 (PH)=1*(HEX) [KPH or MPH" 103 "1~252 (PH)=1*(HEX) [KPH or MPH" 104 "1~252 (PH)=1*(HEX) [KPH or MPH" 105 "1~252 (PH)=1*(HEX) [KPH or MPH" 106 "1~252 (PH)=1*(HEX) [KPH or MPH" 107 "1~252 (PH)=1*(HEX) [KPH or MPH" 108 "1~252 (PH)=1*(HEX) [KPH or MPH" 109 "1~252 (PH)=1*(HEX) [KPH or MPH" 110 "1~252 (PH)=1*(HEX) [KPH or MPH" 111 "1~252 (PH)=1*(HEX) [KPH or MPH" 112 "1~252 (PH)=1*(HEX) [KPH or MPH" 113 "1~252 (PH)=1*(HEX) [KPH or MPH" 114 "1~252 (PH)=1*(HEX) [KPH or MPH" 115 "1~252 (PH)=1*(HEX) [KPH or MPH" 116 "1~252 (PH)=1*(HEX) [KPH or MPH" 117 "1~252 (PH)=1*(HEX) [KPH or MPH" 118 "1~252 (PH)=1*(HEX) [KPH or MPH" 119 "1~252 (PH)=1*(HEX) [KPH or MPH" 120 "1~252 (PH)=1*(HEX) [KPH or MPH" 121 "1~252 (PH)=1*(HEX) [KPH or MPH" 122 "1~252 (PH)=1*(HEX) [KPH or MPH" 123 "1~252 (PH)=1*(HEX) [KPH or MPH" 124 "1~252 (PH)=1*(HEX) [KPH or MPH" 125 "1~252 (PH)=1*(HEX) [KPH or MPH" 126 "1~252 (PH)=1*(HEX) [KPH or MPH" 127 "1~252 (PH)=1*(HEX) [KPH or MPH" 128 "1~252 (PH)=1*(HEX) [KPH or MPH" 129 "1~252 (PH)=1*(HEX) [KPH or MPH" 130 "1~252 (PH)=1*(HEX) [KPH or MPH" 131 "1~252 (PH)=1*(HEX) [KPH or MPH" 132 "1~252 (PH)=1*(HEX) [KPH or MPH" 133 "1~252 (PH)=1*(HEX) [KPH or MPH" 134 "1~252 (PH)=1*(HEX) [KPH or MPH" 135 "1~252 (PH)=1*(HEX) [KPH or MPH" 136 "1~252 (PH)=1*(HEX) [KPH or MPH" 137 "1~252 (PH)=1*(HEX) [KPH or MPH" 138 "1~252 (PH)=1*(HEX) [KPH or MPH" 139 "1~252 (PH)=1*(HEX) [KPH or MPH" 140 "1~252 (PH)=1*(HEX) [KPH or MPH" 141 "1~252 (PH)=1*(HEX) [KPH or MPH" 142 "1~252 (PH)=1*(HEX) [KPH or MPH" 143 "1~252 (PH)=1*(HEX) [KPH or MPH" 144 "1~252 (PH)=1*(HEX) [KPH or MPH" 145 "1~252 (PH)=1*(HEX) [KPH or MPH" 146 "1~252 (PH)=1*(HEX) [KPH or MPH" 147 "1~252 (PH)=1*(HEX) [KPH or MPH" 148 "1~252 (PH)=1*(HEX) [KPH or MPH" 149 "1~252 (PH)=1*(HEX) [KPH or MPH" 150 "1~252 (PH)=1*(HEX) [KPH or MPH" 151 "1~252 (PH)=1*(HEX) [KPH or MPH" 152 "1~252 (PH)=1*(HEX) [KPH or MPH" 153 "1~252 (PH)=1*(HEX) [KPH or MPH" 154 "1~252 (PH)=1*(HEX) [KPH or MPH" 155 "1~252 (PH)=1*(HEX) [KPH or MPH" 156 "1~252 (PH)=1*(HEX) [KPH or MPH" 157 "1~252 (PH)=1*(HEX) [KPH or MPH" 158 "1~252 (PH)=1*(HEX) [KPH or MPH" 159 "1~252 (PH)=1*(HEX) [KPH or MPH" 160 "1~252 (PH)=1*(HEX) [KPH or MPH" 161 "1~252 (PH)=1*(HEX) [KPH or MPH" 162 "1~252 (PH)=1*(HEX) [KPH or MPH" 163 "1~252 (PH)=1*(HEX) [KPH or MPH" 164 "1~252 (PH)=1*(HEX) [KPH or MPH" 165 "1~252 (PH)=1*(HEX) [KPH or MPH" 166 "1~252 (PH)=1*(HEX) [KPH or MPH" 167 "1~252 (PH)=1*(HEX) [KPH or MPH" 168 "1~252 (PH)=1*(HEX) [KPH or MPH" 169 "1~252 (PH)=1*(HEX) [KPH or MPH" 170 "1~252 (PH)=1*(HEX) [KPH or MPH" 171 "1~252 (PH)=1*(HEX) [KPH or MPH" 172 "1~252 (PH)=1*(HEX) [KPH or MPH" 173 "1~252 (PH)=1*(HEX) [KPH or MPH" 174 "1~252 (PH)=1*(HEX) [KPH or MPH" 175 "1~252 (PH)=1*(HEX) [KPH or MPH" 176 "1~252 (PH)=1*(HEX) [KPH or MPH" 177 "1~252 (PH)=1*(HEX) [KPH or MPH" 178 "1~252 (PH)=1*(HEX) [KPH or MPH" 179 "1~252 (PH)=1*(HEX) [KPH or MPH" 180 "1~252 (PH)=1*(HEX) [KPH or MPH" 181 "1~252 (PH)=1*(HEX) [KPH or MPH" 182 "1~252 (PH)=1*(HEX) [KPH or MPH" 183 "1~252 (PH)=1*(HEX) [KPH or MPH" 184 "1~252 (PH)=1*(HEX) [KPH or MPH" 185 "1~252 (PH)=1*(HEX) [KPH or MPH" 186 "1~252 (PH)=1*(HEX) [KPH or MPH" 187 "1~252 (PH)=1*(HEX) [KPH or MPH" 188 "1~252 (PH)=1*(HEX) [KPH or MPH" 189 "1~252 (PH)=1*(HEX) [KPH or MPH" 190 "1~252 (PH)=1*(HEX) [KPH or MPH" 191 "1~252 (PH)=1*(HEX) [KPH or MPH" 192 "1~252 (PH)=1*(HEX) [KPH or MPH" 193 "1~252 (PH)=1*(HEX) [KPH or MPH" 194 "1~252 (PH)=1*(HEX) [KPH or MPH" 195 "1~252 (PH)=1*(HEX) [KPH or MPH" 196 "1~252 (PH)=1*(HEX) [KPH or MPH" 197 "1~252 (PH)=1*(HEX) [KPH or MPH" 198 "1~252 (PH)=1*(HEX) [KPH or MPH" 199 "1~252 (PH)=1*(HEX) [KPH or MPH" 200 "1~252 (PH)=1*(HEX) [KPH or MPH" 201 "1~252 (PH)=1*(HEX) [KPH or MPH" 202 "1~252 (PH)=1*(HEX) [KPH or MPH" 203 "1~252 (PH)=1*(HEX) [KPH or MPH" 204 "1~252 (PH)=1*(HEX) [KPH or MPH" 205 "1~252 (PH)=1*(HEX) [KPH or MPH" 206 "1~252 (PH)=1*(HEX) [KPH or MPH" 207 "1~252 (PH)=1*(HEX) [KPH or MPH" 208 "1~252 (PH)=1*(HEX) [KPH or MPH" 209 "1~252 (PH)=1*(HEX) [KPH or MPH" 210 "1~252 (PH)=1*(HEX) [KPH or MPH" 211 "1~252 (PH)=1*(HEX) [KPH or MPH" 212 "1~252 (PH)=1*(HEX) [KPH or MPH" 213 "1~252 (PH)=1*(HEX) [KPH or MPH" 214 "1~252 (PH)=1*(HEX) [KPH or MPH" 215 "1~252 (PH)=1*(HEX) [KPH or MPH" 216 "1~252 (PH)=1*(HEX) [KPH or MPH" 217 "1~252 (PH)=1*(HEX) [KPH or MPH" 218 "1~252 (PH)=1*(HEX) [KPH or MPH" 219 "1~252 (PH)=1*(HEX) [KPH or MPH" 220 "1~252 (PH)=1*(HEX) [KPH or MPH" 221 "1~252 (PH)=1*(HEX) [KPH or MPH" 222 "1~252 (PH)=1*(HEX) [KPH or MPH" 223 "1~252 (PH)=1*(HEX) [KPH or MPH" 224 "1~252 (PH)=1*(HEX) [KPH or MPH" 225 "1~252 (PH)=1*(HEX) [KPH or MPH" 226 "1~252 (PH)=1*(HEX) [KPH or MPH" 227 "1~252 (PH)=1*(HEX) [KPH or MPH" 228 "1~252 (PH)=1*(HEX) [KPH or MPH" 229 "1~252 (PH)=1*(HEX) [KPH or MPH" 230 "1~252 (PH)=1*(HEX) [KPH or MPH" 231 "1~252 (PH)=1*(HEX) [KPH or MPH" 232 "1~252 (PH)=1*(HEX) [KPH or MPH" 233 "1~252 (PH)=1*(HEX) [KPH or MPH" 234 "1~252 (PH)=1*(HEX) [KPH or MPH" 235 "1~252 (PH)=1*(HEX) [KPH or MPH" 236 "1~252 (PH)=1*(HEX) [KPH or MPH" 237 "1~252 (PH)=1*(HEX) [KPH or MPH" 238 "1~252 (PH)=1*(HEX) [KPH or MPH" 239 "1~252 (PH)=1*(HEX) [KPH or MPH" 240 "1~252 (PH)=1*(HEX) [KPH or MPH" 241 "1~252 (PH)=1*(HEX) [KPH or MPH" 242 "1~252 (PH)=1*(HEX) [KPH or MPH" 243 "1~252 (PH)=1*(HEX) [KPH or MPH" 244 "1~252 (PH)=1*(HEX) [KPH or MPH" 245 "1~252 (PH)=1*(HEX) [KPH or MPH" 246 "1~252 (PH)=1*(HEX) [KPH or MPH" 247 "1~252 (PH)=1*(HEX) [KPH or MPH" 248 "1~252 (PH)=1*(HEX) [KPH or MPH" 249 "1~252 (PH)=1*(HEX) [KPH or MPH" 250 "1~252 (PH)=1*(HEX) [KPH or MPH" 251 "1~252 (PH)=1*(HEX) [KPH or MPH" 252 "1~252 (PH)=1*(HEX) [KPH or MPH" 253 "LHD Conditional No Passing ZONE" 254 "RHD Conditional No Passing ZONE" 255 "Invalid" ;
VAL_ 1260 CF_ISLW_Spd_Dis_NAVI_Con2 0 "No Recognition (Default)" 1 "1~252 (PH)=1*(HEX) [KPH or MPH" 2 "1~252 (PH)=1*(HEX) [KPH or MPH" 3 "1~252 (PH)=1*(HEX) [KPH or MPH" 4 "1~252 (PH)=1*(HEX) [KPH or MPH" 5 "1~252 (PH)=1*(HEX) [KPH or MPH" 6 "1~252 (PH)=1*(HEX) [KPH or MPH" 7 "1~252 (PH)=1*(HEX) [KPH or MPH" 8 "1~252 (PH)=1*(HEX) [KPH or MPH" 9 "1~252 (PH)=1*(HEX) [KPH or MPH" 10 "1~252 (PH)=1*(HEX) [KPH or MPH" 11 "1~252 (PH)=1*(HEX) [KPH or MPH" 12 "1~252 (PH)=1*(HEX) [KPH or MPH" 13 "1~252 (PH)=1*(HEX) [KPH or MPH" 14 "1~252 (PH)=1*(HEX) [KPH or MPH" 15 "1~252 (PH)=1*(HEX) [KPH or MPH" 16 "1~252 (PH)=1*(HEX) [KPH or MPH" 17 "1~252 (PH)=1*(HEX) [KPH or MPH" 18 "1~252 (PH)=1*(HEX) [KPH or MPH" 19 "1~252 (PH)=1*(HEX) [KPH or MPH" 20 "1~252 (PH)=1*(HEX) [KPH or MPH" 21 "1~252 (PH)=1*(HEX) [KPH or MPH" 22 "1~252 (PH)=1*(HEX) [KPH or MPH" 23 "1~252 (PH)=1*(HEX) [KPH or MPH" 24 "1~252 (PH)=1*(HEX) [KPH or MPH" 25 "1~252 (PH)=1*(HEX) [KPH or MPH" 26 "1~252 (PH)=1*(HEX) [KPH or MPH" 27 "1~252 (PH)=1*(HEX) [KPH or MPH" 28 "1~252 (PH)=1*(HEX) [KPH or MPH" 29 "1~252 (PH)=1*(HEX) [KPH or MPH" 30 "1~252 (PH)=1*(HEX) [KPH or MPH" 31 "1~252 (PH)=1*(HEX) [KPH or MPH" 32 "1~252 (PH)=1*(HEX) [KPH or MPH" 33 "1~252 (PH)=1*(HEX) [KPH or MPH" 34 "1~252 (PH)=1*(HEX) [KPH or MPH" 35 "1~252 (PH)=1*(HEX) [KPH or MPH" 36 "1~252 (PH)=1*(HEX) [KPH or MPH" 37 "1~252 (PH)=1*(HEX) [KPH or MPH" 38 "1~252 (PH)=1*(HEX) [KPH or MPH" 39 "1~252 (PH)=1*(HEX) [KPH or MPH" 40 "1~252 (PH)=1*(HEX) [KPH or MPH" 41 "1~252 (PH)=1*(HEX) [KPH or MPH" 42 "1~252 (PH)=1*(HEX) [KPH or MPH" 43 "1~252 (PH)=1*(HEX) [KPH or MPH" 44 "1~252 (PH)=1*(HEX) [KPH or MPH" 45 "1~252 (PH)=1*(HEX) [KPH or MPH" 46 "1~252 (PH)=1*(HEX) [KPH or MPH" 47 "1~252 (PH)=1*(HEX) [KPH or MPH" 48 "1~252 (PH)=1*(HEX) [KPH or MPH" 49 "1~252 (PH)=1*(HEX) [KPH or MPH" 50 "1~252 (PH)=1*(HEX) [KPH or MPH" 51 "1~252 (PH)=1*(HEX) [KPH or MPH" 52 "1~252 (PH)=1*(HEX) [KPH or MPH" 53 "1~252 (PH)=1*(HEX) [KPH or MPH" 54 "1~252 (PH)=1*(HEX) [KPH or MPH" 55 "1~252 (PH)=1*(HEX) [KPH or MPH" 56 "1~252 (PH)=1*(HEX) [KPH or MPH" 57 "1~252 (PH)=1*(HEX) [KPH or MPH" 58 "1~252 (PH)=1*(HEX) [KPH or MPH" 59 "1~252 (PH)=1*(HEX) [KPH or MPH" 60 "1~252 (PH)=1*(HEX) [KPH or MPH" 61 "1~252 (PH)=1*(HEX) [KPH or MPH" 62 "1~252 (PH)=1*(HEX) [KPH or MPH" 63 "1~252 (PH)=1*(HEX) [KPH or MPH" 64 "1~252 (PH)=1*(HEX) [KPH or MPH" 65 "1~252 (PH)=1*(HEX) [KPH or MPH" 66 "1~252 (PH)=1*(HEX) [KPH or MPH" 67 "1~252 (PH)=1*(HEX) [KPH or MPH" 68 "1~252 (PH)=1*(HEX) [KPH or MPH" 69 "1~252 (PH)=1*(HEX) [KPH or MPH" 70 "1~252 (PH)=1*(HEX) [KPH or MPH" 71 "1~252 (PH)=1*(HEX) [KPH or MPH" 72 "1~252 (PH)=1*(HEX) [KPH or MPH" 73 "1~252 (PH)=1*(HEX) [KPH or MPH" 74 "1~252 (PH)=1*(HEX) [KPH or MPH" 75 "1~252 (PH)=1*(HEX) [KPH or MPH" 76 "1~252 (PH)=1*(HEX) [KPH or MPH" 77 "1~252 (PH)=1*(HEX) [KPH or MPH" 78 "1~252 (PH)=1*(HEX) [KPH or MPH" 79 "1~252 (PH)=1*(HEX) [KPH or MPH" 80 "1~252 (PH)=1*(HEX) [KPH or MPH" 81 "1~252 (PH)=1*(HEX) [KPH or MPH" 82 "1~252 (PH)=1*(HEX) [KPH or MPH" 83 "1~252 (PH)=1*(HEX) [KPH or MPH" 84 "1~252 (PH)=1*(HEX) [KPH or MPH" 85 "1~252 (PH)=1*(HEX) [KPH or MPH" 86 "1~252 (PH)=1*(HEX) [KPH or MPH" 87 "1~252 (PH)=1*(HEX) [KPH or MPH" 88 "1~252 (PH)=1*(HEX) [KPH or MPH" 89 "1~252 (PH)=1*(HEX) [KPH or MPH" 90 "1~252 (PH)=1*(HEX) [KPH or MPH" 91 "1~252 (PH)=1*(HEX) [KPH or MPH" 92 "1~252 (PH)=1*(HEX) [KPH or MPH" 93 "1~252 (PH)=1*(HEX) [KPH or MPH" 94 "1~252 (PH)=1*(HEX) [KPH or MPH" 95 "1~252 (PH)=1*(HEX) [KPH or MPH" 96 "1~252 (PH)=1*(HEX) [KPH or MPH" 97 "1~252 (PH)=1*(HEX) [KPH or MPH" 98 "1~252 (PH)=1*(HEX) [KPH or MPH" 99 "1~252 (PH)=1*(HEX) [KPH or MPH" 100 "1~252 (PH)=1*(HEX) [KPH or MPH" 101 "1~252 (PH)=1*(HEX) [KPH or MPH" 102 "1~252 (PH)=1*(HEX) [KPH or MPH" 103 "1~252 (PH)=1*(HEX) [KPH or MPH" 104 "1~252 (PH)=1*(HEX) [KPH or MPH" 105 "1~252 (PH)=1*(HEX) [KPH or MPH" 106 "1~252 (PH)=1*(HEX) [KPH or MPH" 107 "1~252 (PH)=1*(HEX) [KPH or MPH" 108 "1~252 (PH)=1*(HEX) [KPH or MPH" 109 "1~252 (PH)=1*(HEX) [KPH or MPH" 110 "1~252 (PH)=1*(HEX) [KPH or MPH" 111 "1~252 (PH)=1*(HEX) [KPH or MPH" 112 "1~252 (PH)=1*(HEX) [KPH or MPH" 113 "1~252 (PH)=1*(HEX) [KPH or MPH" 114 "1~252 (PH)=1*(HEX) [KPH or MPH" 115 "1~252 (PH)=1*(HEX) [KPH or MPH" 116 "1~252 (PH)=1*(HEX) [KPH or MPH" 117 "1~252 (PH)=1*(HEX) [KPH or MPH" 118 "1~252 (PH)=1*(HEX) [KPH or MPH" 119 "1~252 (PH)=1*(HEX) [KPH or MPH" 120 "1~252 (PH)=1*(HEX) [KPH or MPH" 121 "1~252 (PH)=1*(HEX) [KPH or MPH" 122 "1~252 (PH)=1*(HEX) [KPH or MPH" 123 "1~252 (PH)=1*(HEX) [KPH or MPH" 124 "1~252 (PH)=1*(HEX) [KPH or MPH" 125 "1~252 (PH)=1*(HEX) [KPH or MPH" 126 "1~252 (PH)=1*(HEX) [KPH or MPH" 127 "1~252 (PH)=1*(HEX) [KPH or MPH" 128 "1~252 (PH)=1*(HEX) [KPH or MPH" 129 "1~252 (PH)=1*(HEX) [KPH or MPH" 130 "1~252 (PH)=1*(HEX) [KPH or MPH" 131 "1~252 (PH)=1*(HEX) [KPH or MPH" 132 "1~252 (PH)=1*(HEX) [KPH or MPH" 133 "1~252 (PH)=1*(HEX) [KPH or MPH" 134 "1~252 (PH)=1*(HEX) [KPH or MPH" 135 "1~252 (PH)=1*(HEX) [KPH or MPH" 136 "1~252 (PH)=1*(HEX) [KPH or MPH" 137 "1~252 (PH)=1*(HEX) [KPH or MPH" 138 "1~252 (PH)=1*(HEX) [KPH or MPH" 139 "1~252 (PH)=1*(HEX) [KPH or MPH" 140 "1~252 (PH)=1*(HEX) [KPH or MPH" 141 "1~252 (PH)=1*(HEX) [KPH or MPH" 142 "1~252 (PH)=1*(HEX) [KPH or MPH" 143 "1~252 (PH)=1*(HEX) [KPH or MPH" 144 "1~252 (PH)=1*(HEX) [KPH or MPH" 145 "1~252 (PH)=1*(HEX) [KPH or MPH" 146 "1~252 (PH)=1*(HEX) [KPH or MPH" 147 "1~252 (PH)=1*(HEX) [KPH or MPH" 148 "1~252 (PH)=1*(HEX) [KPH or MPH" 149 "1~252 (PH)=1*(HEX) [KPH or MPH" 150 "1~252 (PH)=1*(HEX) [KPH or MPH" 151 "1~252 (PH)=1*(HEX) [KPH or MPH" 152 "1~252 (PH)=1*(HEX) [KPH or MPH" 153 "1~252 (PH)=1*(HEX) [KPH or MPH" 154 "1~252 (PH)=1*(HEX) [KPH or MPH" 155 "1~252 (PH)=1*(HEX) [KPH or MPH" 156 "1~252 (PH)=1*(HEX) [KPH or MPH" 157 "1~252 (PH)=1*(HEX) [KPH or MPH" 158 "1~252 (PH)=1*(HEX) [KPH or MPH" 159 "1~252 (PH)=1*(HEX) [KPH or MPH" 160 "1~252 (PH)=1*(HEX) [KPH or MPH" 161 "1~252 (PH)=1*(HEX) [KPH or MPH" 162 "1~252 (PH)=1*(HEX) [KPH or MPH" 163 "1~252 (PH)=1*(HEX) [KPH or MPH" 164 "1~252 (PH)=1*(HEX) [KPH or MPH" 165 "1~252 (PH)=1*(HEX) [KPH or MPH" 166 "1~252 (PH)=1*(HEX) [KPH or MPH" 167 "1~252 (PH)=1*(HEX) [KPH or MPH" 168 "1~252 (PH)=1*(HEX) [KPH or MPH" 169 "1~252 (PH)=1*(HEX) [KPH or MPH" 170 "1~252 (PH)=1*(HEX) [KPH or MPH" 171 "1~252 (PH)=1*(HEX) [KPH or MPH" 172 "1~252 (PH)=1*(HEX) [KPH or MPH" 173 "1~252 (PH)=1*(HEX) [KPH or MPH" 174 "1~252 (PH)=1*(HEX) [KPH or MPH" 175 "1~252 (PH)=1*(HEX) [KPH or MPH" 176 "1~252 (PH)=1*(HEX) [KPH or MPH" 177 "1~252 (PH)=1*(HEX) [KPH or MPH" 178 "1~252 (PH)=1*(HEX) [KPH or MPH" 179 "1~252 (PH)=1*(HEX) [KPH or MPH" 180 "1~252 (PH)=1*(HEX) [KPH or MPH" 181 "1~252 (PH)=1*(HEX) [KPH or MPH" 182 "1~252 (PH)=1*(HEX) [KPH or MPH" 183 "1~252 (PH)=1*(HEX) [KPH or MPH" 184 "1~252 (PH)=1*(HEX) [KPH or MPH" 185 "1~252 (PH)=1*(HEX) [KPH or MPH" 186 "1~252 (PH)=1*(HEX) [KPH or MPH" 187 "1~252 (PH)=1*(HEX) [KPH or MPH" 188 "1~252 (PH)=1*(HEX) [KPH or MPH" 189 "1~252 (PH)=1*(HEX) [KPH or MPH" 190 "1~252 (PH)=1*(HEX) [KPH or MPH" 191 "1~252 (PH)=1*(HEX) [KPH or MPH" 192 "1~252 (PH)=1*(HEX) [KPH or MPH" 193 "1~252 (PH)=1*(HEX) [KPH or MPH" 194 "1~252 (PH)=1*(HEX) [KPH or MPH" 195 "1~252 (PH)=1*(HEX) [KPH or MPH" 196 "1~252 (PH)=1*(HEX) [KPH or MPH" 197 "1~252 (PH)=1*(HEX) [KPH or MPH" 198 "1~252 (PH)=1*(HEX) [KPH or MPH" 199 "1~252 (PH)=1*(HEX) [KPH or MPH" 200 "1~252 (PH)=1*(HEX) [KPH or MPH" 201 "1~252 (PH)=1*(HEX) [KPH or MPH" 202 "1~252 (PH)=1*(HEX) [KPH or MPH" 203 "1~252 (PH)=1*(HEX) [KPH or MPH" 204 "1~252 (PH)=1*(HEX) [KPH or MPH" 205 "1~252 (PH)=1*(HEX) [KPH or MPH" 206 "1~252 (PH)=1*(HEX) [KPH or MPH" 207 "1~252 (PH)=1*(HEX) [KPH or MPH" 208 "1~252 (PH)=1*(HEX) [KPH or MPH" 209 "1~252 (PH)=1*(HEX) [KPH or MPH" 210 "1~252 (PH)=1*(HEX) [KPH or MPH" 211 "1~252 (PH)=1*(HEX) [KPH or MPH" 212 "1~252 (PH)=1*(HEX) [KPH or MPH" 213 "1~252 (PH)=1*(HEX) [KPH or MPH" 214 "1~252 (PH)=1*(HEX) [KPH or MPH" 215 "1~252 (PH)=1*(HEX) [KPH or MPH" 216 "1~252 (PH)=1*(HEX) [KPH or MPH" 217 "1~252 (PH)=1*(HEX) [KPH or MPH" 218 "1~252 (PH)=1*(HEX) [KPH or MPH" 219 "1~252 (PH)=1*(HEX) [KPH or MPH" 220 "1~252 (PH)=1*(HEX) [KPH or MPH" 221 "1~252 (PH)=1*(HEX) [KPH or MPH" 222 "1~252 (PH)=1*(HEX) [KPH or MPH" 223 "1~252 (PH)=1*(HEX) [KPH or MPH" 224 "1~252 (PH)=1*(HEX) [KPH or MPH" 225 "1~252 (PH)=1*(HEX) [KPH or MPH" 226 "1~252 (PH)=1*(HEX) [KPH or MPH" 227 "1~252 (PH)=1*(HEX) [KPH or MPH" 228 "1~252 (PH)=1*(HEX) [KPH or MPH" 229 "1~252 (PH)=1*(HEX) [KPH or MPH" 230 "1~252 (PH)=1*(HEX) [KPH or MPH" 231 "1~252 (PH)=1*(HEX) [KPH or MPH" 232 "1~252 (PH)=1*(HEX) [KPH or MPH" 233 "1~252 (PH)=1*(HEX) [KPH or MPH" 234 "1~252 (PH)=1*(HEX) [KPH or MPH" 235 "1~252 (PH)=1*(HEX) [KPH or MPH" 236 "1~252 (PH)=1*(HEX) [KPH or MPH" 237 "1~252 (PH)=1*(HEX) [KPH or MPH" 238 "1~252 (PH)=1*(HEX) [KPH or MPH" 239 "1~252 (PH)=1*(HEX) [KPH or MPH" 240 "1~252 (PH)=1*(HEX) [KPH or MPH" 241 "1~252 (PH)=1*(HEX) [KPH or MPH" 242 "1~252 (PH)=1*(HEX) [KPH or MPH" 243 "1~252 (PH)=1*(HEX) [KPH or MPH" 244 "1~252 (PH)=1*(HEX) [KPH or MPH" 245 "1~252 (PH)=1*(HEX) [KPH or MPH" 246 "1~252 (PH)=1*(HEX) [KPH or MPH" 247 "1~252 (PH)=1*(HEX) [KPH or MPH" 248 "1~252 (PH)=1*(HEX) [KPH or MPH" 249 "1~252 (PH)=1*(HEX) [KPH or MPH" 250 "1~252 (PH)=1*(HEX) [KPH or MPH" 251 "1~252 (PH)=1*(HEX) [KPH or MPH" 252 "1~252 (PH)=1*(HEX) [KPH or MPH" 253 "LHD Conditional No Passing ZONE" 254 "RHD Conditional No Passing ZONE" 255 "Invalid" ;
VAL_ 1260 ISLA_AddtnlSign 0 "No Recognition (default)" 1 "School Crossing" 16 "Do Not Pass" 17 "Reserved" 18 "Reserved" 19 "Reserved" 20 "Reserved" 21 "Reserved" 22 "Reserved" 23 "Reserved" 24 "Exit" 25 "Roundabout" 26 "Right Curve" 27 "Left Curve" 28 "Winding Road" 29 "Reserved" 30 "Reserved" 31 "Reserved" 2 "Pedestrian Crossing" 3 "Bicycle Crossing" 4 "Reserved" 5 "Reserved" 6 "Reserved" 7 "Reserved" 8 "Stop" 9 "Yield" 10 "Stop Ahead" 11 "Yield Ahead" 12 "Road Construction Ahead" 13 "Lane Reduction" 14 "Reserved" 15 "Reserved" ;
VAL_ 1260 ISLA_AutoUsmSta 0 "None Auto Function (Delete Menu)" 1 "Auto Off" 2 "Auto On" 3 "Invalid (GRAY)" ;
VAL_ 1260 ISLA_Cntry 0 "Europe/Russia/Australia" 1 "Domestic" 2 "China" 3 "USA" 4 "Canada" 5 "Australia" 6 "Reserved" 7 "Reserved" 8 "Reserved" 9 "Reserved" 10 "Reserved" 11 "Reserved" 12 "Reserved" 13 "Reserved" 14 "Reserved" 15 "Initial Value (default)" ;
VAL_ 1260 ISLA_OffstUsmSta 0 "None Offset Function (Delete Offset Menu)" 1 "-10kph or -5mph" 2 "-5kph or -3mph" 3 "0kph or 0mph" 4 "+5kph or +3mph" 5 "+10kph or +5mph" 6 "Reserved" 7 "Invalid (GRAY)" ;
VAL_ 1260 ISLA_OptUsmSta 0 "None ISLA Option (Delete ISLA Menu)" 1 "Off" 2 "Warning" 3 "Assist" 4 "Reserved" 5 "Reserved" 6 "Reserved" 7 "Invalid (GRAY)" ;
VAL_ 1260 ISLA_Popup 0 "No Popup" 1 "MSLA Speed will Change" 2 "MSLA Speed has Changed" 3 "CC_SCC Speed will Change" 4 "CC_SCC Speed has Changed" 5 "Reserved" 6 "Reserved" 7 "Reserved" ;
VAL_ 1260 ISLA_SchoolZone 0 "No School Zone" 1 "School Zone" ;
VAL_ 1156 CF_LeftLine_Departure 0 "No Left Line Departure" 1 "Left Line Departure" ;
VAL_ 1156 CF_LeftLine_Quality 0 "Very Low Quality" 1 "Low Quality" 2 "High Quality" 3 "Very High Quality" ;
VAL_ 1156 CF_RightLine_Departure 0 "No Right Line Departure" 1 "Right Line Departure" ;
VAL_ 1156 CF_RightLine_Quality 0 "Very Low Quality" 1 "Low Quality" 2 "High Quality" 3 "Very High Quality" ;
VAL_ 1191 CF_FCA_Equip_FR_CMR 0 "No Coding" 1 "Sensor Fusion FCA" 2 "Camera only FCA" 3 "No FCA Option" 4 "Reserved" 5 "Reserved" 6 "Reserved" 7 "Reserved" ;
VAL_ 897 CF_Mdps_LKA_FUNC 0 "The LKA function of MDPS is not plugged in (unplugged)." 1 "The LKA function of MDPS is plugged in." ;
VAL_ 897 CF_Mdps_Stat 0 "Reserved" 1 "Steering still in initialization phase" 2 "Steering ready, waits for PA command" 3 "Steering set in standby by PA" 4 "Steering requested to go to first activation step" 5 "Steering requested to go to final activation step" 6 "Steering went to error internally" 7 "Steering aborted the automatic function" 15 "Not Available" ;
VAL_ 897 CF_Mdps_Type 0 "C-MDPS" 1 "R-MDPS(Dual Pinion)" 2 "R-MDPS(Belt)" 3 "Reserved" ;
VAL_ 593 CF_Mdps_FailStat 0 "Not in fail state" 1 "In fail state" ;
VAL_ 593 CF_Mdps_ToiActive 0 "Deactivated" 1 "Activated" ;
VAL_ 593 CF_Mdps_ToiFlt 0 "No fault" 1 "Faulty" ;
VAL_ 593 CF_Mdps_ToiUnavail 0 "Available" 1 "Unavailable" ;
SIG_GROUP_ 870 CGW_PC4 1 : F_N_ENG N;
SIG_GROUP_ 871 CGW_PC5 1 : CF_Ems_IsgStat CF_Ems_SldAct G_SEL_DISP SLD_VS;
SIG_GROUP_ 1345 CGW1 1 : CF_Gway_AstDrSw CF_Gway_DrvDrSw CF_Gway_DrvSeatBeltSw CF_Gway_HazardSw CF_Gway_HBAControlMode CF_Gway_HeadLampHigh CF_Gway_HeadLampLow CF_Gway_InhibitRMT CF_Gway_RainSnsState CF_Gway_TSigLHSw CF_Gway_TSigRHSw CF_Gway_TurnSigLh CF_Gway_TurnSigRh CF_Gway_WiperAutoSw CF_Gway_WiperHighSw CF_Gway_WiperIntSw CF_Gway_WiperIntT CF_Gway_WiperLowSw CF_Gway_IGNSw;
SIG_GROUP_ 1363 CGW2 1 : CF_Gway_RLDrSw CF_Gway_RRDrSw CF_Gway_WiperParkPosition;
SIG_GROUP_ 1193 CGW8 1 : C_SMKTeleEngineRunning;
SIG_GROUP_ 1265 CLU11 1 : CF_Clu_AliveCnt1 CF_Clu_CruiseSwMain CF_Clu_CruiseSwState CF_Clu_SldMainSW CF_Clu_SPEED_UNIT CF_Clu_Vanz;
SIG_GROUP_ 1456 CLU12 1 : CF_Clu_Odometer;
SIG_GROUP_ 1292 CLU13 1 : CF_Clu_DAWLastBreakTime CF_Clu_DrivinglampStat CF_Clu_IceWarnIndStat;
SIG_GROUP_ 1307 CLU16 1 : CF_Clu_TirePressUnitNValueSet CF_Clu_DAWModeNValueSet CF_Clu_FCAModeNValueSet CF_Clu_HDANValueSet CF_Clu_USMReset CF_Gway_WPCNValueSet CF_Clu_MoodLpBrightNValueSet;
SIG_GROUP_ 1190 CLU19 1 : CF_AVN_CluUSMReset CF_AVN_DAWModeNValueSet_New CF_AVN_FCANValueSet CF_AVN_HBANValueSet CF_AVN_HDA_NValueSet CF_AVN_LkaModeNValueSet CF_AVN_LVDANValueSet CF_AVN_NSCCCamNValueSet CF_AVN_WarningTimingNValueSet CF_Clu_DawResetReq;
SIG_GROUP_ 913 CLU21 1 : CF_Clu_LFASwState;
SIG_GROUP_ 1474 CLU22 1 : CF_Clu_AdasISLAAutoSetReq CF_Clu_AdasISLASetReq CF_Clu_ISLAOffsetSetReq;
SIG_GROUP_ 809 EMS12 1 : ACC_ACT CONF_TCU MUL_CODE PV_AV_CAN;
SIG_GROUP_ 608 EMS16 1 : AliveCounter CF_Ems_AclAct Checksum ENG_STAT;
SIG_GROUP_ 544 ESP12 1 : CYL_PRES CYL_PRES_STAT CYL_PRESS_DIAG ESP12_AliveCounter ESP12_Checksum LAT_ACCEL LAT_ACCEL_DIAG LAT_ACCEL_STAT LONG_ACCEL LONG_ACCEL_DIAG LONG_ACCEL_STAT YAW_RATE YAW_RATE_DIAG YAW_RATE_STAT;
SIG_GROUP_ 909 FCA11_FS 1 : CF_VSM_BeltCmd CF_VSM_DecCmdAct CF_VSM_HBACmd CF_VSM_Prefill CF_VSM_Warn CR_FCA_Alive CR_VSM_DecCmd FCA_CmdAct FCA_CRC FCA_DrvSetStatus FCA_Failinfo FCA_RelativeVelocity FCA_Sensor_Type FCA_Status FCA_StopReq FCA_TimetoCollision FCA_WrngSndSta;
SIG_GROUP_ 1155 FCA12 1 : FCA_DrvSetState FCA_USM FCA_WarningTargetDisplay;
SIG_GROUP_ 1996 FR_CMR_GST_HSCAN 1 : FR_CMR_GST_Byte0 FR_CMR_GST_Byte1 FR_CMR_GST_Byte2 FR_CMR_GST_Byte3 FR_CMR_GST_Byte4 FR_CMR_GST_Byte5 FR_CMR_GST_Byte6 FR_CMR_GST_Byte7;
SIG_GROUP_ 2008 FR_RDR_GST_HSCAN 1 : FR_RDR_GST_Byte0 FR_RDR_GST_Byte1 FR_RDR_GST_Byte2 FR_RDR_GST_Byte3 FR_RDR_GST_Byte4 FR_RDR_GST_Byte5 FR_RDR_GST_Byte6 FR_RDR_GST_Byte7;
SIG_GROUP_ 2015 GST_ALL 1 : GST_ALL_Byte0 GST_ALL_Byte1 GST_ALL_Byte2 GST_ALL_Byte3 GST_ALL_Byte4 GST_ALL_Byte5 GST_ALL_Byte6 GST_ALL_Byte7;
SIG_GROUP_ 1988 GST_FR_CMR_HSCAN 1 : GST_FR_CMR_Byte0 GST_FR_CMR_Byte1 GST_FR_CMR_Byte2 GST_FR_CMR_Byte3 GST_FR_CMR_Byte4 GST_FR_CMR_Byte5 GST_FR_CMR_Byte6 GST_FR_CMR_Byte7;
SIG_GROUP_ 2000 GST_FR_RDR_HSCAN 1 : GST_FR_RDR_Byte0 GST_FR_RDR_Byte1 GST_FR_RDR_Byte2 GST_FR_RDR_Byte3 GST_FR_RDR_Byte4 GST_FR_RDR_Byte5 GST_FR_RDR_Byte6 GST_FR_RDR_Byte7;
SIG_GROUP_ 1157 HDA11 1 : CF_HDA_InfoDisplay CF_HDA_InfoDisplay2 CF_HDA_LFA_SymbolState CF_HDA_LFA_Wrn_Snd CF_HDA_Mode CF_HDA_Opt_USM;
SIG_GROUP_ 1470 HU_CLU_PE_05 1 : HU_NaviCamSettingStatus HU_NaviStatus;
SIG_GROUP_ 1407 HU_MON_PE_01 1 : HU_AdasSupport HU_DistributeInfo HU_Type;
SIG_GROUP_ 832 LKA11_FS 1 : CF_HBA_Lamp CF_HBA_Opt CF_HBA_Opt_USM CF_HBA_SysState CF_LKA_ActToi CF_LKA_CRC CF_LKA_FusionState CF_LKA_HandsOff_Snd CF_LKA_LaneRecogState CF_LKA_LHWarning CF_LKA_MsgCount CF_LKA_Opt_USM CF_LKA_RHWarning CF_LKA_SymbolState CF_LKA_SysState CF_LKA_SysWarning CF_LKA_ToiFlt CF_LKA_USM_Mode CR_LKA_StrToqReq;
SIG_GROUP_ 1342 LKA12 1 : CF_DAW_Opt_USM_NEW CF_DAW_Status CF_DAW_TimeReset CF_DAW_Warn CF_ISLW_Addinfo_Display CF_ISLW_OvrlapSign_Dis CF_ISLW_Spd_Dis_CLU_Main CF_ISLW_Spd_Dis_NAVI_Main CF_ISLW_Status CF_LeadVehDptAlert_Display CF_LeadVehDptAlert_USM ISLA_IcyWrn ISLA_SpdChgReq ISLA_SpdwOffst ISLA_SpdWrn ISLA_SwIgnoreReq ISLA_SymFlashMod;
SIG_GROUP_ 1260 LKA13 1 : CF_ISLW_ConInfo_Sta_Con1 CF_ISLW_ConInfo_Sta_Con2 CF_ISLW_Spd_Dis_CLU_Con1 CF_ISLW_Spd_Dis_CLU_Con2 CF_ISLW_Spd_Dis_NAVI_Con1 CF_ISLW_Spd_Dis_NAVI_Con2 ISLA_AddtnlSign ISLA_AutoUsmSta ISLA_Cntry ISLA_OffstUsmSta ISLA_OptUsmSta ISLA_Popup ISLA_SchoolZone;
SIG_GROUP_ 1156 LKA14 1 : CF_LaneInfo_AliveCounter CF_LeftLine_Departure CF_LeftLine_HeadingAngle CF_LeftLine_Position CF_LeftLine_Quality CF_RightLine_Departure CF_RightLine_HeadingAngle CF_RightLine_Position CF_RightLine_Quality;
SIG_GROUP_ 1191 LKA15 1 : CF_FCA_Equip_FR_CMR;
SIG_GROUP_ 1069 LKA16 1 : ID_CIPV Longitudinal_Distance Relative_Velocity;
SIG_GROUP_ 897 MDPS11_FS 1 : CF_Mdps_LKA_FUNC CF_Mdps_Stat CF_Mdps_Type;
SIG_GROUP_ 593 MDPS12_FS 1 : CF_Mdps_FailStat CF_Mdps_MsgCount2 CF_Mdps_ToiActive CF_Mdps_ToiFlt CF_Mdps_ToiUnavail CF_Mdps12_CRC CR_Mdps_StrColTq;
SIG_GROUP_ 2679898130 MEAS_1 1 : Meas1Data;
SIG_GROUP_ 2679898131 MEAS_2 1 : Meas2Data;
SIG_GROUP_ 2679898132 MEAS_3 1 : Meas3Data;
SIG_GROUP_ 2679898133 MEAS_4 1 : Meas4Data;
SIG_GROUP_ 2679898134 MEAS_5 1 : Meas5Data;
